VERSION "Vinfast Initial LGC"

NS_ :

BS_:

BU_: CHARGER_S VCU CHARGER_C HMI MCU REFLASH BMS1 BMS0 CLU
VAL_TABLE_ TestCmd 3 "Set UDT Fault" 2 "Set UDT warning2" 0 "Clear" 1 "Set UDT warning1" ;

BO_ 2432176283 E44_MCU: 8 Vector__XXX
 SG_ MCU_W_Phase_Current : 32|16@1+ (0.1,0) [0|6553.5] "A" Vector__XXX
 SG_ MCU_V_Phase_Current : 16|16@1+ (0.1,0) [0|6553.5] "A" Vector__XXX
 SG_ MCU_U_Phase_Current : 0|16@1+ (0.1,0) [0|6553.5] "A" Vector__XXX

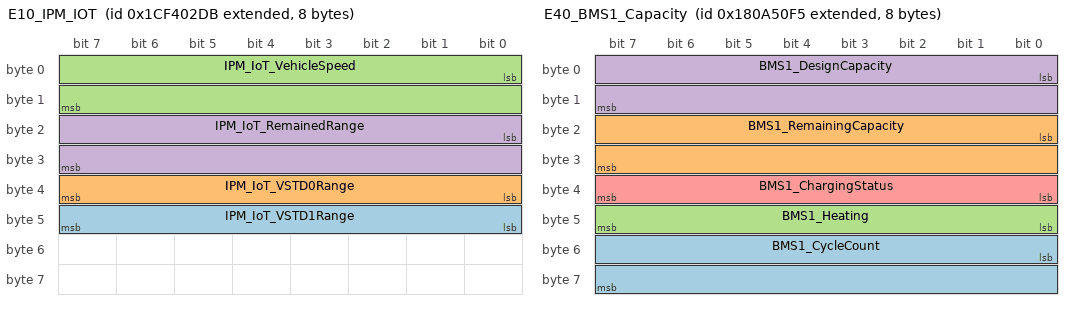
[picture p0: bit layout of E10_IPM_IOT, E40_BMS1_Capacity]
BO_ 2633237211 E10_IPM_IOT: 8 Vector__XXX
 SG_ IPM_IoT_VSTD1Range : 40|8@1+ (1,0) [0|255] "km" Vector__XXX
 SG_ IPM_IoT_VSTD0Range : 32|8@1+ (1,0) [0|255] "km" Vector__XXX
 SG_ IPM_IoT_VehicleSpeed : 0|16@1+ (0.1,0) [0|1000] "km/h" Vector__XXX
 SG_ IPM_IoT_RemainedRange : 16|16@1+ (0.1,0) [0|5000] "km" Vector__XXX

BO_ 2550878453 E39_BMS1_FailureCode: 8 Vector__XXX
 SG_ BMS1_VoltageAcquisitionFailure : 23|1@1+ (1,0) [0|1] "" Vector__XXX
 SG_ BMS1_TotalUndervoltage : 12|1@1+ (1,0) [0|1] "" Vector__XXX
 SG_ BMS1_TotalOvervoltage : 9|1@1+ (1,0) [0|1] "" Vector__XXX
 SG_ BMS1_TempAcquisitionFailure : 24|1@1+ (1,0) [0|1] "" Vector__XXX
 SG_ BMS1_MosTemperature : 6|1@1+ (1,0) [0|1] "" Vector__XXX
 SG_ BMS1_MosHighTemperature : 19|1@1+ (1,0) [0|1] "" Vector__XXX
 SG_ BMS1_LoadAccess : 4|1@1+ (1,0) [0|1] "" Vector__XXX
 SG_ BMS1_FullCharging : 10|1@1+ (1,0) [0|1] "" Vector__XXX
 SG_ BMS1_EnvironLowTemperature : 18|1@1+ (1,0) [0|1] "" Vector__XXX
 SG_ BMS1_EnvironHighTemperature : 17|1@1+ (1,0) [0|1] "" Vector__XXX
 SG_ BMS1_Discharging : 0|1@1+ (1,0) [0|1] "" Vector__XXX
 SG_ BMS1_DischargeShortCircuit : 21|1@1+ (1,0) [0|1] "" Vector__XXX
 SG_ BMS1_DischargeOvercurrent : 20|1@1+ (1,0) [0|1] "" Vector__XXX
 SG_ BMS1_DischargeMosOn : 2|1@1+ (1,0) [0|1] "" Vector__XXX
 SG_ BMS1_DischargeMosFailure : 25|1@1+ (1,0) [0|1] "" Vector__XXX
 SG_ BMS1_DischargeLowTemperature : 14|1@1+ (1,0) [0|1] "" Vector__XXX
 SG_ BMS1_DischargeHighTemperature : 13|1@1+ (1,0) [0|1] "" Vector__XXX
 SG_ BMS1_ChargingOvercurrent : 22|1@1+ (1,0) [0|1] "" Vector__XXX
 SG_ BMS1_ChargingMosFailure : 26|1@1+ (1,0) [0|1] "" Vector__XXX
 SG_ BMS1_ChargingLowTemperature : 16|1@1+ (1,0) [0|1] "" Vector__XXX
 SG_ BMS1_ChargingHighTemperature : 15|1@1+ (1,0) [0|1] "" Vector__XXX
 SG_ BMS1_Charging : 1|1@1+ (1,0) [0|1] "" Vector__XXX
 SG_ BMS1_ChargerisConnected : 5|1@1+ (1,0) [0|1] "" Vector__XXX
 SG_ BMS1_ChargeMosOn : 3|1@1+ (1,0) [0|1] "" Vector__XXX
 SG_ BMS1_CellVoltageDifference : 27|1@1+ (1,0) [0|1] "" Vector__XXX
 SG_ BMS1_CellUndervoltage : 11|1@1+ (1,0) [0|1] "" Vector__XXX
 SG_ BMS1_CellOvervoltage : 8|1@1+ (1,0) [0|1] "" Vector__XXX
 SG_ BMS1_AmbientTemperature : 7|1@1+ (1,0) [0|1] "" Vector__XXX

BO_ 2550878452 E19_BMS0_FailureCode: 8 Vector__XXX
 SG_ BMS0_VoltageAcquisitionFailure : 23|1@1+ (1,0) [0|1] "" Vector__XXX
 SG_ BMS0_TotalUndervoltage : 12|1@1+ (1,0) [0|1] "" Vector__XXX
 SG_ BMS0_TotalOvervoltage : 9|1@1+ (1,0) [0|1] "" Vector__XXX
 SG_ BMS0_TempAcquisitionFailure : 24|1@1+ (1,0) [0|1] "" Vector__XXX
 SG_ BMS0_MosTemperature : 6|1@1+ (1,0) [0|1] "" Vector__XXX
 SG_ BMS0_MosHighTemperature : 19|1@1+ (1,0) [0|1] "" Vector__XXX
 SG_ BMS0_LoadAccess : 4|1@1+ (1,0) [0|1] "" Vector__XXX
 SG_ BMS0_FullCharging : 10|1@1+ (1,0) [0|1] "" Vector__XXX
 SG_ BMS0_EnvironLowTemperature : 18|1@1+ (1,0) [0|1] "" Vector__XXX
 SG_ BMS0_EnvironHighTemperature : 17|1@1+ (1,0) [0|1] "" Vector__XXX
 SG_ BMS0_Discharging : 0|1@1+ (1,0) [0|1] "" Vector__XXX
 SG_ BMS0_DischargeShortCircuit : 21|1@1+ (1,0) [0|1] "" Vector__XXX
 SG_ BMS0_DischargeOvercurrent : 20|1@1+ (1,0) [0|1] "" Vector__XXX
 SG_ BMS0_DischargeMosOn : 2|1@1+ (1,0) [0|1] "" Vector__XXX
 SG_ BMS0_DischargeMosFailure : 25|1@1+ (1,0) [0|1] "" Vector__XXX
 SG_ BMS0_DischargeLowTemperature : 14|1@1+ (1,0) [0|1] "" Vector__XXX
 SG_ BMS0_DischargeHighTemperature : 13|1@1+ (1,0) [0|1] "" Vector__XXX
 SG_ BMS0_ChargingOvercurrent : 22|1@1+ (1,0) [0|1] "" Vector__XXX
 SG_ BMS0_ChargingMosFailure : 26|1@1+ (1,0) [0|1] "" Vector__XXX
 SG_ BMS0_ChargingLowTemperature : 16|1@1+ (1,0) [0|1] "" Vector__XXX
 SG_ BMS0_ChargingHighTemperature : 15|1@1+ (1,0) [0|1] "" Vector__XXX
 SG_ BMS0_Charging : 1|1@1+ (1,0) [0|1] "" Vector__XXX
 SG_ BMS0_ChargerisConnected : 5|1@1+ (1,0) [0|1] "" Vector__XXX
 SG_ BMS0_ChargeMosOn : 3|1@1+ (1,0) [0|1] "" Vector__XXX
 SG_ BMS0_CellVoltageDifference : 27|1@1+ (1,0) [0|1] "" Vector__XXX
 SG_ BMS0_CellUndervoltage : 11|1@1+ (1,0) [0|1] "" Vector__XXX
 SG_ BMS0_CellOvervoltage : 8|1@1+ (1,0) [0|1] "" Vector__XXX
 SG_ BMS0_AmbientTemperature : 7|1@1+ (1,0) [0|1] "" Vector__XXX

BO_ 1426 E53_SBC_Status2: 8 Vector__XXX
 SG_ SBC_OutputCurrent : 32|16@1+ (0.1,0) [0|6553.5] "A" Vector__XXX
 SG_ SBC_OutputVoltage : 16|16@1+ (0.1,0) [0|6553.5] "V" Vector__XXX
 SG_ SBC_InputVoltage : 0|16@1+ (0.1,0) [0|6553.5] "V" Vector__XXX

BO_ 2550588917 E42_BMS1_ChargerVoltageCurrent: 8 Vector__XXX
 SG_ BMS1_OutputControl : 32|8@1+ (1,0) [0|1] "" Vector__XXX
 SG_ BMS1_MaxVoltage : 0|16@1+ (0.1,0) [0|6553.5] "V" Vector__XXX
 SG_ BMS1_MaxCurrent : 16|16@1+ (1,0) [0|65535] "A" Vector__XXX

BO_ 2550747381 E41_BMS1_DebugInfo: 8 Vector__XXX
 SG_ BMS1_VersionNumber : 0|16@1+ (1,0) [0|65535] "" Vector__XXX

BO_ 2550812917 E40_BMS1_Capacity: 8 Vector__XXX
 SG_ BMS1_CycleCount : 48|16@1+ (1,0) [0|65535] "" Vector__XXX
 SG_ BMS1_RemainingCapacity : 16|16@1+ (1,0) [0|65535] "mAh" Vector__XXX
 SG_ BMS1_Heating : 40|8@1+ (1,0) [0|1] "" Vector__XXX
 SG_ BMS1_DesignCapacity : 0|16@1+ (1,0) [0|65535] "mAh" Vector__XXX
 SG_ BMS1_ChargingStatus : 32|8@1+ (1,0) [0|1] "" Vector__XXX

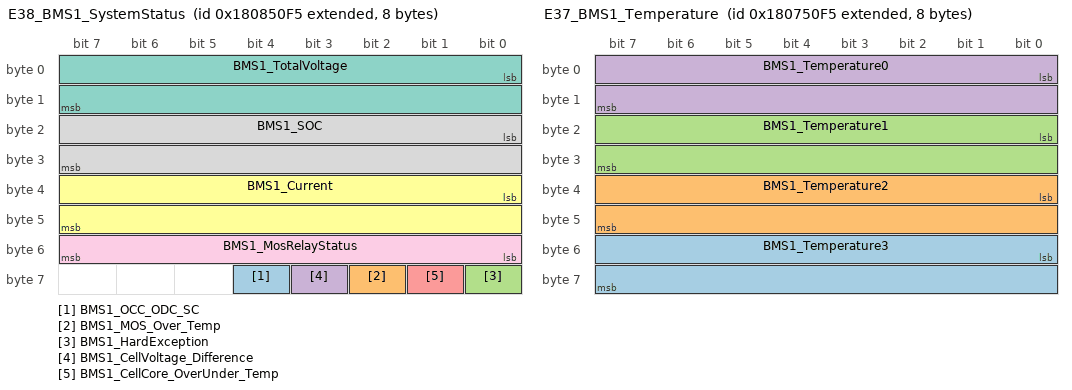
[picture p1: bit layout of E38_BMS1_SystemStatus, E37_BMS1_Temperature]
BO_ 2550681845 E38_BMS1_SystemStatus: 8 Vector__XXX
 SG_ BMS1_OCC_ODC_SC : 60|1@1+ (1,0) [0|1] "" Vector__XXX
 SG_ BMS1_MOS_Over_Temp : 58|1@1+ (1,0) [0|1] "" Vector__XXX
 SG_ BMS1_HardException : 56|1@1+ (1,0) [0|1] "" Vector__XXX
 SG_ BMS1_CellVoltage_Difference : 59|1@1+ (1,0) [0|1] "" Vector__XXX
 SG_ BMS1_CellCore_OverUnder_Temp : 57|1@1+ (1,0) [0|1] "" Vector__XXX
 SG_ BMS1_Current : 32|16@1+ (1,0) [0|65535] "A" Vector__XXX
 SG_ BMS1_TotalVoltage : 0|16@1+ (0.1,0) [0|6553.5] "V" Vector__XXX
 SG_ BMS1_SOC : 16|16@1+ (0.1,0) [0|6553.5] "%" Vector__XXX
 SG_ BMS1_MosRelayStatus : 48|8@1+ (1,0) [0|3] "" Vector__XXX

BO_ 2550616309 E37_BMS1_Temperature: 8 Vector__XXX
 SG_ BMS1_Temperature3 : 48|16@1+ (0.1,-40) [-40|6513.5] "℃" Vector__XXX
 SG_ BMS1_Temperature2 : 32|16@1+ (0.1,-40) [-40|6513.5] "℃" Vector__XXX
 SG_ BMS1_Temperature1 : 16|16@1+ (0.1,-40) [-40|6513.5] "℃" Vector__XXX
 SG_ BMS1_Temperature0 : 0|16@1+ (0.1,-40) [-40|6513.5] "℃" Vector__XXX

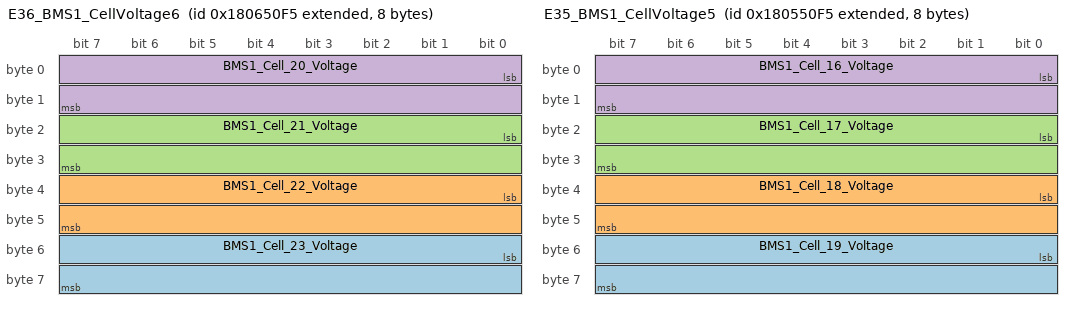
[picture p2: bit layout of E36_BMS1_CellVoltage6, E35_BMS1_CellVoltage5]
BO_ 2550550773 E36_BMS1_CellVoltage6: 8 Vector__XXX
 SG_ BMS1_Cell_23_Voltage : 48|16@1+ (1,0) [0|65535] "mV" Vector__XXX
 SG_ BMS1_Cell_22_Voltage : 32|16@1+ (1,0) [0|65535] "mV" Vector__XXX
 SG_ BMS1_Cell_21_Voltage : 16|16@1+ (1,0) [0|65535] "mV" Vector__XXX
 SG_ BMS1_Cell_20_Voltage : 0|16@1+ (1,0) [0|65535] "mV" Vector__XXX

BO_ 2550485237 E35_BMS1_CellVoltage5: 8 Vector__XXX
 SG_ BMS1_Cell_19_Voltage : 48|16@1+ (1,0) [0|65535] "mV" Vector__XXX
 SG_ BMS1_Cell_18_Voltage : 32|16@1+ (1,0) [0|65535] "mV" Vector__XXX
 SG_ BMS1_Cell_17_Voltage : 16|16@1+ (1,0) [0|65535] "mV" Vector__XXX
 SG_ BMS1_Cell_16_Voltage : 0|16@1+ (1,0) [0|65535] "mV" Vector__XXX

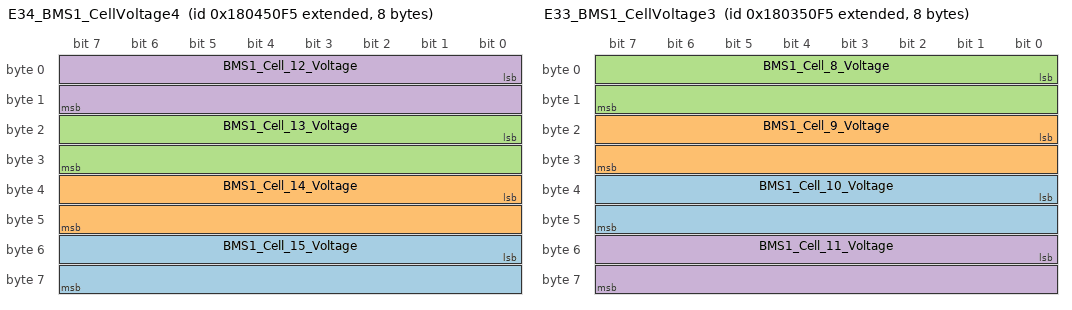
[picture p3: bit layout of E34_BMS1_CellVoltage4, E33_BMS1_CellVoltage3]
BO_ 2550419701 E34_BMS1_CellVoltage4: 8 Vector__XXX
 SG_ BMS1_Cell_15_Voltage : 48|16@1+ (1,0) [0|65535] "mV" Vector__XXX
 SG_ BMS1_Cell_14_Voltage : 32|16@1+ (1,0) [0|65535] "mV" Vector__XXX
 SG_ BMS1_Cell_13_Voltage : 16|16@1+ (1,0) [0|65535] "mV" Vector__XXX
 SG_ BMS1_Cell_12_Voltage : 0|16@1+ (1,0) [0|65535] "mV" Vector__XXX

BO_ 2550354165 E33_BMS1_CellVoltage3: 8 Vector__XXX
 SG_ BMS1_Cell_10_Voltage : 32|16@1+ (1,0) [0|65535] "mV" Vector__XXX
 SG_ BMS1_Cell_9_Voltage : 16|16@1+ (1,0) [0|65535] "mV" Vector__XXX
 SG_ BMS1_Cell_8_Voltage : 0|16@1+ (1,0) [0|65535] "mV" Vector__XXX
 SG_ BMS1_Cell_11_Voltage : 48|16@1+ (1,0) [0|65535] "mV" Vector__XXX

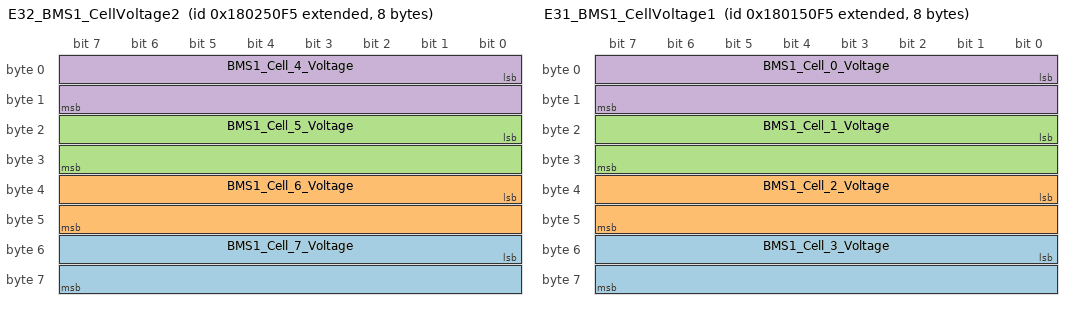
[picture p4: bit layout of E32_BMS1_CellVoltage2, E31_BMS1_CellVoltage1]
BO_ 2550288629 E32_BMS1_CellVoltage2: 8 Vector__XXX
 SG_ BMS1_Cell_7_Voltage : 48|16@1+ (1,0) [0|65535] "mV" Vector__XXX
 SG_ BMS1_Cell_6_Voltage : 32|16@1+ (1,0) [0|65535] "mV" Vector__XXX
 SG_ BMS1_Cell_5_Voltage : 16|16@1+ (1,0) [0|65535] "mV" Vector__XXX
 SG_ BMS1_Cell_4_Voltage : 0|16@1+ (1,0) [0|65535] "mV" Vector__XXX

BO_ 2550223093 E31_BMS1_CellVoltage1: 8 Vector__XXX
 SG_ BMS1_Cell_3_Voltage : 48|16@1+ (1,0) [0|65535] "mV" Vector__XXX
 SG_ BMS1_Cell_2_Voltage : 32|16@1+ (1,0) [0|65535] "mV" Vector__XXX
 SG_ BMS1_Cell_1_Voltage : 16|16@1+ (1,0) [0|65535] "mV" Vector__XXX
 SG_ BMS1_Cell_0_Voltage : 0|16@1+ (1,0) [0|65535] "mV" Vector__XXX

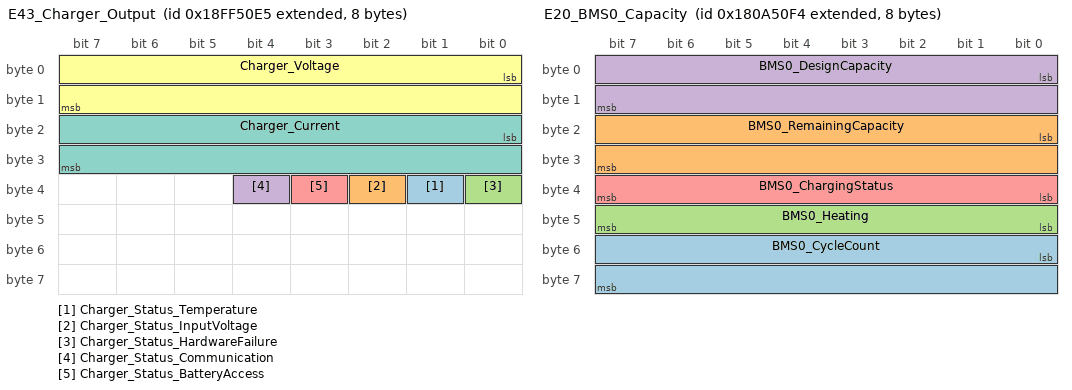
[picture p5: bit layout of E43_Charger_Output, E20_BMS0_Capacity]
BO_ 2566869221 E43_Charger_Output: 8 Vector__XXX
 SG_ Charger_Status_Temperature : 33|1@1+ (1,0) [0|1] "" Vector__XXX
 SG_ Charger_Status_InputVoltage : 34|1@1+ (1,0) [0|1] "" Vector__XXX
 SG_ Charger_Status_HardwareFailure : 32|1@1+ (1,0) [0|1] "" Vector__XXX
 SG_ Charger_Status_Communication : 36|1@1+ (1,0) [0|1] "" Vector__XXX
 SG_ Charger_Status_BatteryAccess : 35|1@1+ (1,0) [0|1] "" Vector__XXX
 SG_ Charger_Voltage : 0|16@1+ (0.1,0) [0|6553.5] "V" Vector__XXX
 SG_ Charger_Current : 16|16@1+ (0.1,0) [0|6553.5] "A" Vector__XXX

BO_ 2550588916 E22_BMS0_ChargerVoltageCurrent: 8 Vector__XXX
 SG_ BMS0_OutputControl : 32|8@1+ (1,0) [0|1] "" Vector__XXX
 SG_ BMS0_MaxVoltage : 0|16@1+ (0.1,0) [0|6553.5] "V" Vector__XXX
 SG_ BMS0_MaxCurrent : 16|16@1+ (1,0) [0|65535] "A" Vector__XXX

BO_ 2550747380 E21_BMS0_DebugInfo: 8 Vector__XXX
 SG_ BMS0_VersionNumber : 0|16@1+ (1,0) [0|65535] "" Vector__XXX

BO_ 2550812916 E20_BMS0_Capacity: 8 Vector__XXX
 SG_ BMS0_CycleCount : 48|16@1+ (1,0) [0|65535] "" Vector__XXX
 SG_ BMS0_RemainingCapacity : 16|16@1+ (1,0) [0|65535] "mAh" Vector__XXX
 SG_ BMS0_Heating : 40|8@1+ (1,0) [0|1] "" Vector__XXX
 SG_ BMS0_DesignCapacity : 0|16@1+ (1,0) [0|65535] "mAh" Vector__XXX
 SG_ BMS0_ChargingStatus : 32|8@1+ (1,0) [0|1] "" Vector__XXX

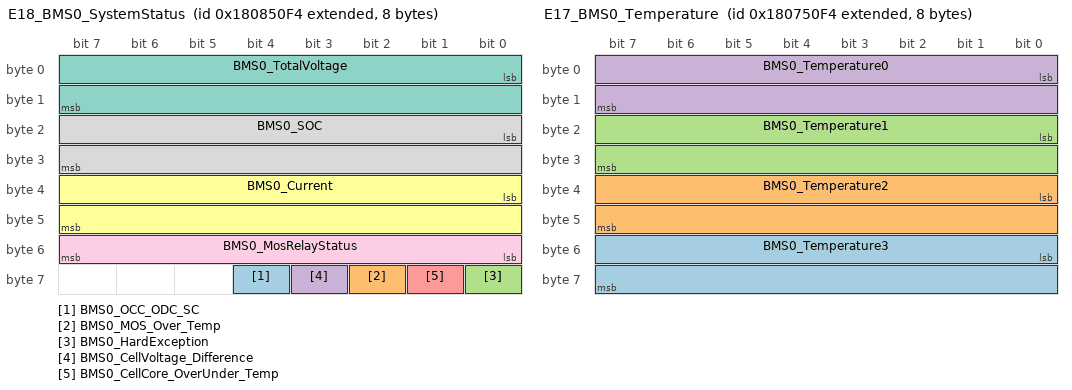
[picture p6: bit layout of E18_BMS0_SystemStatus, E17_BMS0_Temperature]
BO_ 2550681844 E18_BMS0_SystemStatus: 8 Vector__XXX
 SG_ BMS0_OCC_ODC_SC : 60|1@1+ (1,0) [0|1] "" Vector__XXX
 SG_ BMS0_MOS_Over_Temp : 58|1@1+ (1,0) [0|1] "" Vector__XXX
 SG_ BMS0_HardException : 56|1@1+ (1,0) [0|1] "" Vector__XXX
 SG_ BMS0_CellVoltage_Difference : 59|1@1+ (1,0) [0|1] "" Vector__XXX
 SG_ BMS0_CellCore_OverUnder_Temp : 57|1@1+ (1,0) [0|1] "" Vector__XXX
 SG_ BMS0_Current : 32|16@1+ (1,0) [0|65535] "A" Vector__XXX
 SG_ BMS0_TotalVoltage : 0|16@1+ (0.1,0) [0|6553.5] "V" Vector__XXX
 SG_ BMS0_SOC : 16|16@1+ (0.1,0) [0|6553.5] "%" Vector__XXX
 SG_ BMS0_MosRelayStatus : 48|8@1+ (1,0) [0|3] "" Vector__XXX

BO_ 2550616308 E17_BMS0_Temperature: 8 Vector__XXX
 SG_ BMS0_Temperature3 : 48|16@1+ (0.1,-40) [-40|6513.5] "℃" Vector__XXX
 SG_ BMS0_Temperature2 : 32|16@1+ (0.1,-40) [-40|6513.5] "℃" Vector__XXX
 SG_ BMS0_Temperature1 : 16|16@1+ (0.1,-40) [-40|6513.5] "℃" Vector__XXX
 SG_ BMS0_Temperature0 : 0|16@1+ (0.1,-40) [-40|6513.5] "℃" Vector__XXX

BO_ 2550550772 E16_BMS0_CellVoltage6: 8 Vector__XXX
 SG_ BMS0_Cell_23_Voltage : 48|16@1+ (1,0) [0|65535] "mV" Vector__XXX
 SG_ BMS0_Cell_22_Voltage : 32|16@1+ (1,0) [0|65535] "mV" Vector__XXX
 SG_ BMS0_Cell_21_Voltage : 16|16@1+ (1,0) [0|65535] "mV" Vector__XXX
 SG_ BMS0_Cell_20_Voltage : 0|16@1+ (1,0) [0|65535] "mV" Vector__XXX

BO_ 2550485236 E15_BMS0_CellVoltage5: 8 Vector__XXX
 SG_ BMS0_Cell_19_Voltage : 48|16@1+ (1,0) [0|65535] "mV" Vector__XXX
 SG_ BMS0_Cell_18_Voltage : 32|16@1+ (1,0) [0|65535] "mV" Vector__XXX
 SG_ BMS0_Cell_17_Voltage : 16|16@1+ (1,0) [0|65535] "mV" Vector__XXX
 SG_ BMS0_Cell_16_Voltage : 0|16@1+ (1,0) [0|65535] "mV" Vector__XXX

BO_ 2550419700 E14_BMS0_CellVoltage4: 8 Vector__XXX
 SG_ BMS0_Cell_15_Voltage : 48|16@1+ (1,0) [0|65535] "mV" Vector__XXX
 SG_ BMS0_Cell_14_Voltage : 32|16@1+ (1,0) [0|65535] "mV" Vector__XXX
 SG_ BMS0_Cell_13_Voltage : 16|16@1+ (1,0) [0|65535] "mV" Vector__XXX
 SG_ BMS0_Cell_12_Voltage : 0|16@1+ (1,0) [0|65535] "mV" Vector__XXX

BO_ 2550354164 E13_BMS0_CellVoltage3: 8 Vector__XXX
 SG_ BMS0_Cell_10_Voltage : 32|16@1+ (1,0) [0|65535] "mV" Vector__XXX
 SG_ BMS0_Cell_9_Voltage : 16|16@1+ (1,0) [0|65535] "mV" Vector__XXX
 SG_ BMS0_Cell_8_Voltage : 0|16@1+ (1,0) [0|65535] "mV" Vector__XXX
 SG_ BMS0_Cell_11_Voltage : 48|16@1+ (1,0) [0|65535] "mV" Vector__XXX

BO_ 2550288628 E12_BMS0_CellVoltage2: 8 Vector__XXX
 SG_ BMS0_Cell_7_Voltage : 48|16@1+ (1,0) [0|65535] "mV" Vector__XXX
 SG_ BMS0_Cell_6_Voltage : 32|16@1+ (1,0) [0|65535] "mV" Vector__XXX
 SG_ BMS0_Cell_5_Voltage : 16|16@1+ (1,0) [0|65535] "mV" Vector__XXX
 SG_ BMS0_Cell_4_Voltage : 0|16@1+ (1,0) [0|65535] "mV" Vector__XXX

BO_ 2550223092 E11_BMS0_CellVoltage1: 8 Vector__XXX
 SG_ BMS0_Cell_3_Voltage : 48|16@1+ (1,0) [0|65535] "mV" Vector__XXX
 SG_ BMS0_Cell_2_Voltage : 32|16@1+ (1,0) [0|65535] "mV" Vector__XXX
 SG_ BMS0_Cell_1_Voltage : 16|16@1+ (1,0) [0|65535] "mV" Vector__XXX
 SG_ BMS0_Cell_0_Voltage : 0|16@1+ (1,0) [0|65535] "mV" Vector__XXX

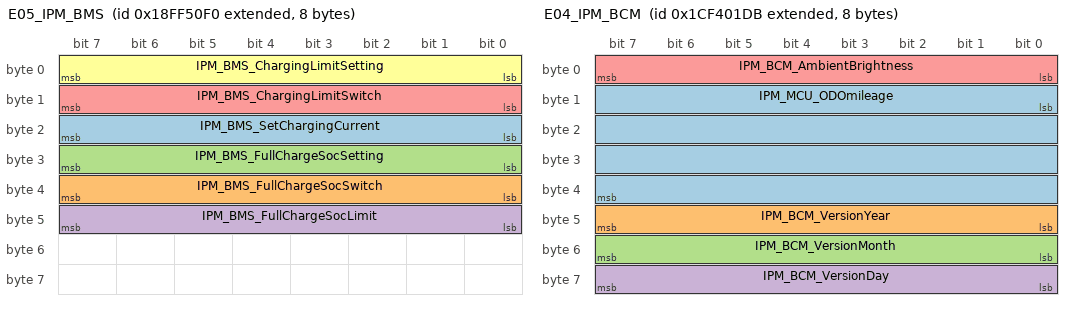
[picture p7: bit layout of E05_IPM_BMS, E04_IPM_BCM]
BO_ 2566869232 E05_IPM_BMS: 8 Vector__XXX
 SG_ IPM_BMS_SetChargingCurrent : 16|8@1+ (1,0) [0|100] "" Vector__XXX
 SG_ IPM_BMS_FullChargeSocSwitch : 32|8@1+ (1,0) [0|1] "" Vector__XXX
 SG_ IPM_BMS_FullChargeSocSetting : 24|8@1+ (1,0) [0|1] "" Vector__XXX
 SG_ IPM_BMS_FullChargeSocLimit : 40|8@1+ (1,0) [10|100] "" Vector__XXX
 SG_ IPM_BMS_ChargingLimitSwitch : 8|8@1+ (1,0) [0|1] "" Vector__XXX
 SG_ IPM_BMS_ChargingLimitSetting : 0|8@1+ (1,0) [0|1] "" Vector__XXX

BO_ 2633236955 E04_IPM_BCM: 8 Vector__XXX
 SG_ IPM_MCU_ODOmileage : 8|32@1+ (1,0) [0|999999] "km" Vector__XXX
 SG_ IPM_BCM_VersionYear : 40|8@1+ (1,0) [0|99] "" Vector__XXX
 SG_ IPM_BCM_VersionMonth : 48|8@1+ (1,0) [0|12] "" Vector__XXX
 SG_ IPM_BCM_VersionDay : 56|8@1+ (1,0) [0|31] "" Vector__XXX
 SG_ IPM_BCM_AmbientBrightness : 0|8@1+ (1,0) [0|10] "" Vector__XXX

BO_ 2550685947 E03_BCM_IPM: 8 Vector__XXX
 SG_ BCM_IPM_NFCcardCountdown : 40|8@1+ (1,0) [0|255] "" Vector__XXX
 SG_ BCM_IPM_BCMVersion : 48|16@1+ (1,0) [0|65535] "" Vector__XXX
 SG_ BCM_IPM_ChargerAccess : 6|1@1+ (1,0) [0|1] "" Vector__XXX
 SG_ BCM_IPM_ACC_Status : 11|1@1+ (1,0) [0|1] "" Vector__XXX
 SG_ BCM_IPM_WidnshieldMotor : 20|2@1+ (1,0) [0|3] "" Vector__XXX
 SG_ BCM_IPM_TapLock : 3|1@1+ (1,0) [0|1] "" Vector__XXX
 SG_ BCM_IPM_SideSupporter : 2|1@1+ (1,0) [0|1] "" Vector__XXX
 SG_ BCM_IPM_ShelfMotor : 22|2@1+ (1,0) [0|3] "" Vector__XXX
 SG_ BCM_IPM_PedalLock : 4|1@1+ (1,0) [0|1] "" Vector__XXX
 SG_ BCM_IPM_NfcCardStatus : 24|2@1+ (1,0) [0|3] "" Vector__XXX
 SG_ BCM_IPM_NfcCardModeCountdown : 32|8@1+ (1,0) [0|255] "" Vector__XXX
 SG_ BCM_IPM_NfcCardFeedback : 28|2@1+ (1,0) [0|3] "" Vector__XXX
 SG_ BCM_IPM_NfcCardDistribution : 26|2@1+ (1,0) [0|3] "" Vector__XXX
 SG_ BCM_IPM_Motion : 1|1@1+ (1,0) [0|1] "" Vector__XXX
 SG_ BCM_IPM_MechanicalKeyAcc : 9|1@1+ (1,0) [0|1] "" Vector__XXX
 SG_ BCM_IPM_InternalAcc : 8|1@1+ (1,0) [0|1] "" Vector__XXX
 SG_ BCM_IPM_Inclination : 0|1@1+ (1,0) [0|1] "" Vector__XXX
 SG_ BCM_IPM_HeatingSeat : 18|2@1+ (1,0) [0|3] "" Vector__XXX
 SG_ BCM_IPM_CombinationAuto : 10|1@1+ (1,0) [0|1] "" Vector__XXX
 SG_ BCM_IPM_BucketLock : 5|1@1+ (1,0) [0|1] "" Vector__XXX
 SG_ BCM_IPM_HeatingHandle : 16|2@1+ (1,0) [0|3] "" Vector__XXX

BO_ 2550681850 E01_BCM_MCU: 8 Vector__XXX
 SG_ BCM_IPM_ScreenSwitching : 32|8@1+ (1,0) [0|1] "" Vector__XXX
 SG_ BCM_IPM_VSTDConnection : 44|1@1+ (1,0) [0|1] "" Vector__XXX
 SG_ BCM_IPM_RightSwitchConnection : 42|1@1+ (1,0) [0|1] "" Vector__XXX
 SG_ BCM_IPM_RearLamlConnection : 41|1@1+ (1,0) [0|1] "" Vector__XXX
 SG_ BCM_IPM_LeftSwitchConnection : 43|1@1+ (1,0) [0|1] "" Vector__XXX
 SG_ BCM_IPM_HeadLamlConnection : 40|1@1+ (1,0) [0|1] "" Vector__XXX
 SG_ BCM_IPM_LowBrake : 23|1@1+ (1,0) [0|1] "" Vector__XXX
 SG_ BCM_IPM_ReverseGear_ReturnCancel : 22|1@1+ (1,0) [0|1] "" Vector__XXX
 SG_ BCM_MCU_MotorSelfLearning : 48|8@1+ (1,0) [0|1] "" Vector__XXX
 SG_ BCM_MCU_EmergencyExtinguishing : 20|1@1+ (1,0) [0|1] "" Vector__XXX
 SG_ BCM_MCU_Downshift : 19|1@1+ (1,0) [0|1] "" Vector__XXX
 SG_ BCM_MCU_Cruise : 21|1@1+ (1,0) [0|1] "" Vector__XXX
 SG_ BCM_MCU_ThrottleVoltage : 0|16@1+ (0.01,0) [0|500] "V" Vector__XXX
 SG_ BCM_MCU_CutOff_AutoButton : 17|1@1+ (1,0) [0|1] "" Vector__XXX
 SG_ BCM_MCU_SingleSupport : 18|1@1+ (1,0) [0|1] "" Vector__XXX
 SG_ BCM_MCU_DCDC_Voltage : 56|8@1+ (0.1,0) [0|25.5] "V" Vector__XXX
 SG_ BCM_MCU_Brake : 16|1@1+ (1,0) [0|1] "" Vector__XXX

BO_ 2550681849 E02_BCM_IPM: 8 Vector__XXX
 SG_ BCM_IPM_LightStatus_Passing : 5|1@1+ (1,0) [0|1] "" Vector__XXX
 SG_ BCM_IPM_DelayedPowerDown : 7|1@1+ (1,0) [0|1] "" Vector__XXX
 SG_ BCM_IPM_AutoHeadLamp : 6|1@1+ (1,0) [0|1] "" Vector__XXX
 SG_ BCM_IPM_WelcomeHome : 8|8@1+ (1,0) [0|255] "" Vector__XXX
 SG_ BCM_IPM_LightStatus_Turn_R : 1|1@1+ (1,0) [0|1] "" Vector__XXX
 SG_ BCM_IPM_LightStatus_Turn_L : 0|1@1+ (1,0) [0|1] "" Vector__XXX
 SG_ BCM_IPM_LightStatus_HighBeam : 3|1@1+ (1,0) [0|1] "" Vector__XXX
 SG_ BCM_IPM_LightStatus_HeadNear : 2|1@1+ (1,0) [0|1] "" Vector__XXX
 SG_ BCM_IPM_LightStatus_Brake : 4|1@1+ (1,0) [0|1] "" Vector__XXX
 SG_ BCM_IPM_LightFailure_Turn_R : 17|1@1+ (1,0) [0|1] "" Vector__XXX
 SG_ BCM_IPM_LightFailure_Turn_L : 16|1@1+ (1,0) [0|1] "" Vector__XXX
 SG_ BCM_IPM_LightFailure_HighBeam : 19|1@1+ (1,0) [0|1] "" Vector__XXX
 SG_ BCM_IPM_LightFailure_HeadNear : 18|1@1+ (1,0) [0|1] "" Vector__XXX
 SG_ BCM_IPM_LightFailure_Brake : 20|1@1+ (1,0) [0|1] "" Vector__XXX
 SG_ BCM_IPM_LightCurrent_Turn_R : 32|8@1+ (0.1,0) [0|25.5] "A" Vector__XXX
 SG_ BCM_IPM_LightCurrent_Turn_L : 24|8@1+ (0.1,0) [0|25.5] "A" Vector__XXX
 SG_ BCM_IPM_LightCurrent_HighBeam : 48|8@1+ (0.1,0) [0|25.5] "A" Vector__XXX
 SG_ BCM_IPM_LightCurrent_HeadNear : 40|8@1+ (0.1,0) [0|25.5] "A" Vector__XXX
 SG_ BCM_IPM_LightCurrent_Brake : 56|8@1+ (0.1,0) [0|25.5] "A" Vector__XXX

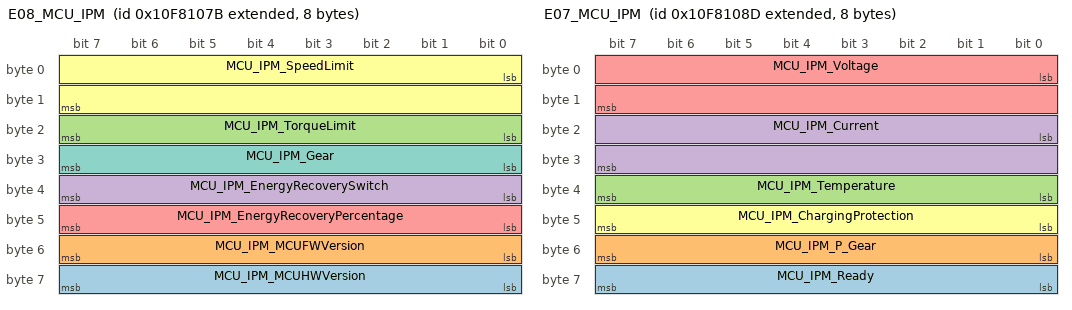
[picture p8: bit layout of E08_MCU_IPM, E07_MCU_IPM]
BO_ 2432176251 E08_MCU_IPM: 8 Vector__XXX
 SG_ MCU_IPM_MCUHWVersion : 56|8@1+ (1,0) [0|255] "" Vector__XXX
 SG_ MCU_IPM_MCUFWVersion : 48|8@1+ (1,0) [0|255] "" Vector__XXX
 SG_ MCU_IPM_TorqueLimit : 16|8@1+ (1,0) [0|100] "%" Vector__XXX
 SG_ MCU_IPM_EnergyRecoverySwitch : 32|8@1+ (1,0) [0|1] "" Vector__XXX
 SG_ MCU_IPM_EnergyRecoveryPercentage : 40|8@1+ (1,0) [0|100] "%" Vector__XXX
 SG_ MCU_IPM_SpeedLimit : 0|16@1+ (1,0) [0|20000] "RPM" Vector__XXX
 SG_ MCU_IPM_Gear : 24|8@1+ (1,0) [0|2] "" Vector__XXX

BO_ 2432176269 E07_MCU_IPM: 8 Vector__XXX
 SG_ MCU_IPM_Ready : 56|8@1+ (1,0) [0|1] "" Vector__XXX
 SG_ MCU_IPM_P_Gear : 48|8@1+ (1,0) [0|1] "" Vector__XXX
 SG_ MCU_IPM_Temperature : 32|8@1- (1,0) [-128|127] "℃" Vector__XXX
 SG_ MCU_IPM_Current : 16|16@1+ (0.1,0) [0|500] "A" Vector__XXX
 SG_ MCU_IPM_Voltage : 0|16@1+ (0.1,0) [0|1000] "V" Vector__XXX
 SG_ MCU_IPM_ChargingProtection : 40|8@1+ (1,0) [0|1] "" Vector__XXX

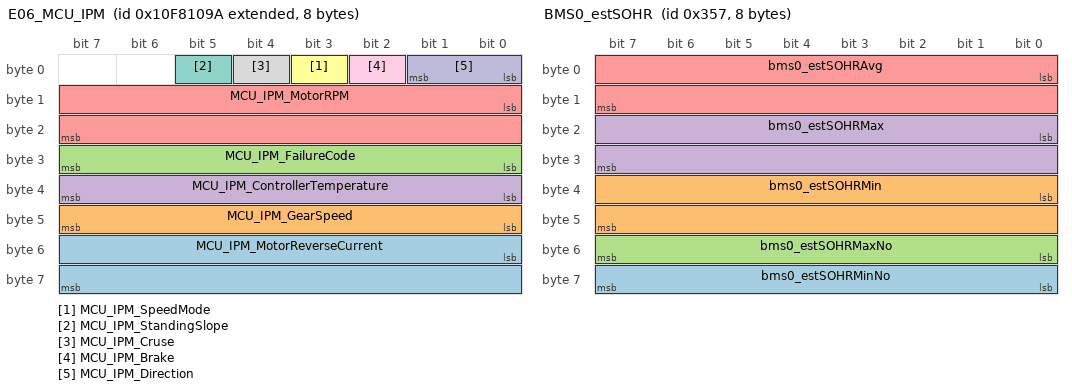
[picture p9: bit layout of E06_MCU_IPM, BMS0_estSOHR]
BO_ 2432176282 E06_MCU_IPM: 8 Vector__XXX
 SG_ MCU_IPM_MotorReverseCurrent : 48|16@1+ (0.1,0) [0|2000] "A" Vector__XXX
 SG_ MCU_IPM_GearSpeed : 40|8@1+ (1,0) [0|2] "" Vector__XXX
 SG_ MCU_IPM_FailureCode : 24|8@1+ (1,0) [0|20] "" Vector__XXX
 SG_ MCU_IPM_ControllerTemperature : 32|8@1- (1,0) [-128|127] "℃" Vector__XXX
 SG_ MCU_IPM_MotorRPM : 8|16@1+ (1,0) [0|20000] "RPM" Vector__XXX
 SG_ MCU_IPM_SpeedMode : 3|1@1+ (1,0) [0|1] "" Vector__XXX
 SG_ MCU_IPM_StandingSlope : 5|1@1+ (1,0) [0|1] "" Vector__XXX
 SG_ MCU_IPM_Cruse : 4|1@1+ (1,0) [0|1] "" Vector__XXX
 SG_ MCU_IPM_Brake : 2|1@1+ (1,0) [0|1] "" Vector__XXX
 SG_ MCU_IPM_Direction : 0|2@1+ (1,0) [0|2] "" Vector__XXX

BO_ 1425 E52_SBC_Status1: 2 Vector__XXX
 SG_ SBC_BMS_AliveCounter : 8|8@1+ (1,0) [0|255] "" Vector__XXX
 SG_ SBC_BMS_OnOffAck : 0|8@1+ (1,0) [0|255] "" Vector__XXX

BO_ 1424 E51_BMS_SBC_Control: 1 Vector__XXX
 SG_ BMS_SBC_SbcOn : 0|1@1+ (1,0) [0|1] "" Vector__XXX

BO_ 773 BMS0_devDebugEnable: 8 BMS0
 SG_ bms0_devDebugSox_Flag : 24|8@1+ (1,0) [0|255] "" Vector__XXX
 SG_ bms0_devDebugTemp_Flag : 16|8@1+ (1,0) [0|255] "" Vector__XXX
 SG_ bms0_devDebugCurrent_Flag : 8|8@1+ (1,0) [0|255] "" Vector__XXX
 SG_ bms0_devDebugCellVolt_Flag : 0|8@1+ (1,0) [0|255] "" Vector__XXX

BO_ 872 BMS1_msrPackStd: 8 BMS1
 SG_ bms1_msrCurrentPackStd : 0|16@1- (0.02,0) [-655.36|655.34] "A" Vector__XXX

BO_ 856 BMS0_msrPackStd: 8 BMS0
 SG_ bms0_msrCurrentPackStd : 0|16@1- (0.02,0) [-655.36|655.34] "A" Vector__XXX

BO_ 855 BMS0_estSOHR: 8 BMS0
 SG_ bms0_estSOHRMinNo : 56|8@1+ (1,0) [0|255] "" Vector__XXX
 SG_ bms0_estSOHRMin : 32|16@1+ (1,0) [0|65535] "%" Vector__XXX
 SG_ bms0_estSOHRMaxNo : 48|8@1+ (1,0) [0|255] "" Vector__XXX
 SG_ bms0_estSOHRMax : 16|16@1+ (1,0) [0|65535] "%" Vector__XXX
 SG_ bms0_estSOHRAvg : 0|16@1+ (1,0) [0|65535] "%" Vector__XXX

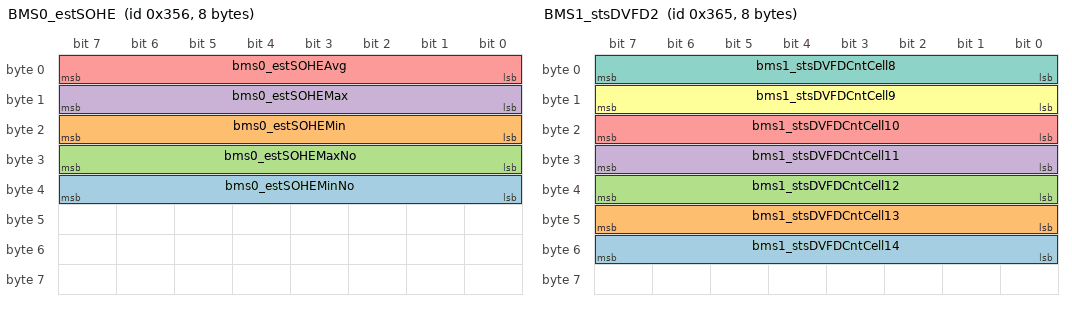
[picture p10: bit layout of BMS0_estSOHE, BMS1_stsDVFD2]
BO_ 854 BMS0_estSOHE: 8 BMS0
 SG_ bms0_estSOHEMinNo : 32|8@1+ (1,0) [0|255] "" Vector__XXX
 SG_ bms0_estSOHEMin : 16|8@1+ (1,0) [0|255] "%" Vector__XXX
 SG_ bms0_estSOHEMaxNo : 24|8@1+ (1,0) [0|15] "" Vector__XXX
 SG_ bms0_estSOHEMax : 8|8@1+ (1,0) [0|255] "%" Vector__XXX
 SG_ bms0_estSOHEAvg : 0|8@1+ (1,0) [0|255] "%" Vector__XXX

BO_ 869 BMS1_stsDVFD2: 8 BMS1
 SG_ bms1_stsDVFDCntCell14 : 48|8@1+ (1,0) [0|255] "" Vector__XXX
 SG_ bms1_stsDVFDCntCell13 : 40|8@1+ (1,0) [0|255] "" Vector__XXX
 SG_ bms1_stsDVFDCntCell12 : 32|8@1+ (1,0) [0|255] "" Vector__XXX
 SG_ bms1_stsDVFDCntCell11 : 24|8@1+ (1,0) [0|255] "" Vector__XXX
 SG_ bms1_stsDVFDCntCell10 : 16|8@1+ (1,0) [0|255] "" Vector__XXX
 SG_ bms1_stsDVFDCntCell9 : 8|8@1+ (1,0) [0|255] "" Vector__XXX
 SG_ bms1_stsDVFDCntCell8 : 0|8@1+ (1,0) [0|255] "" Vector__XXX

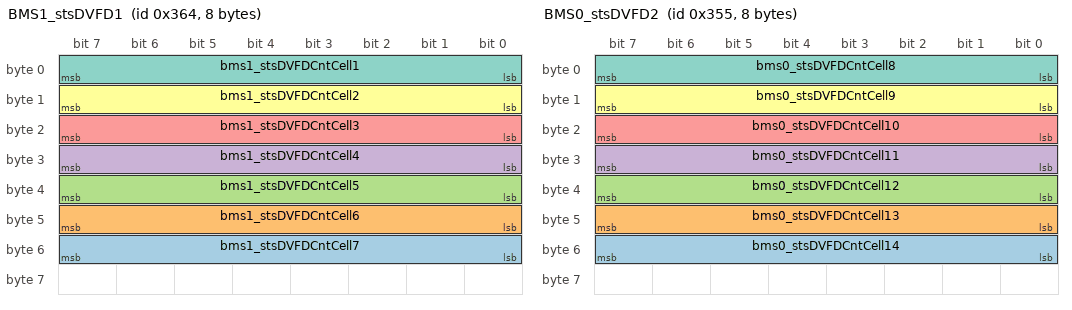
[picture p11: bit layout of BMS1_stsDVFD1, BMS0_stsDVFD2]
BO_ 868 BMS1_stsDVFD1: 8 BMS1
 SG_ bms1_stsDVFDCntCell7 : 48|8@1+ (1,0) [0|255] "" Vector__XXX
 SG_ bms1_stsDVFDCntCell6 : 40|8@1+ (1,0) [0|255] "" Vector__XXX
 SG_ bms1_stsDVFDCntCell5 : 32|8@1+ (1,0) [0|255] "" Vector__XXX
 SG_ bms1_stsDVFDCntCell4 : 24|8@1+ (1,0) [0|255] "" Vector__XXX
 SG_ bms1_stsDVFDCntCell3 : 16|8@1+ (1,0) [0|255] "" Vector__XXX
 SG_ bms1_stsDVFDCntCell2 : 8|8@1+ (1,0) [0|255] "" Vector__XXX
 SG_ bms1_stsDVFDCntCell1 : 0|8@1+ (1,0) [0|255] "" Vector__XXX

BO_ 853 BMS0_stsDVFD2: 8 BMS0
 SG_ bms0_stsDVFDCntCell14 : 48|8@1+ (1,0) [0|255] "" Vector__XXX
 SG_ bms0_stsDVFDCntCell13 : 40|8@1+ (1,0) [0|255] "" Vector__XXX
 SG_ bms0_stsDVFDCntCell12 : 32|8@1+ (1,0) [0|255] "" Vector__XXX
 SG_ bms0_stsDVFDCntCell11 : 24|8@1+ (1,0) [0|255] "" Vector__XXX
 SG_ bms0_stsDVFDCntCell10 : 16|8@1+ (1,0) [0|255] "" Vector__XXX
 SG_ bms0_stsDVFDCntCell9 : 8|8@1+ (1,0) [0|255] "" Vector__XXX
 SG_ bms0_stsDVFDCntCell8 : 0|8@1+ (1,0) [0|255] "" Vector__XXX

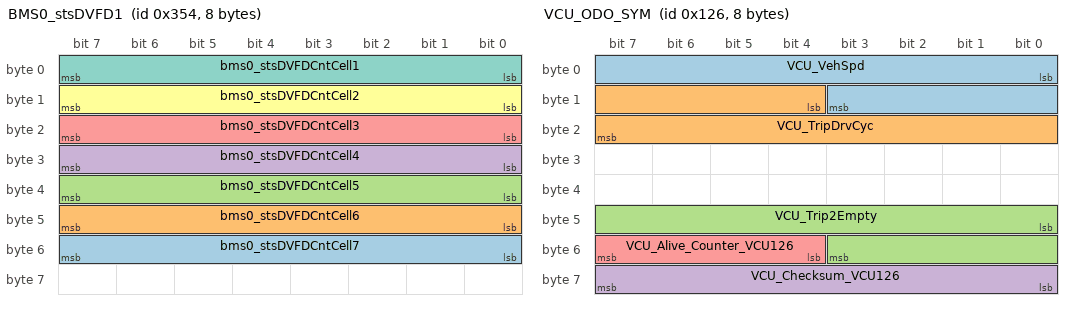
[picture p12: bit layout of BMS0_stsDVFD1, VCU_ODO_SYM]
BO_ 852 BMS0_stsDVFD1: 8 BMS0
 SG_ bms0_stsDVFDCntCell7 : 48|8@1+ (1,0) [0|255] "" Vector__XXX
 SG_ bms0_stsDVFDCntCell6 : 40|8@1+ (1,0) [0|255] "" Vector__XXX
 SG_ bms0_stsDVFDCntCell5 : 32|8@1+ (1,0) [0|255] "" Vector__XXX
 SG_ bms0_stsDVFDCntCell4 : 24|8@1+ (1,0) [0|255] "" Vector__XXX
 SG_ bms0_stsDVFDCntCell3 : 16|8@1+ (1,0) [0|255] "" Vector__XXX
 SG_ bms0_stsDVFDCntCell2 : 8|8@1+ (1,0) [0|255] "" Vector__XXX
 SG_ bms0_stsDVFDCntCell1 : 0|8@1+ (1,0) [0|255] "" Vector__XXX

BO_ 865 BMS1_estAccumEnergy: 8 BMS1
 SG_ bms1_estAccumEnergyDisc : 32|32@1- (0.001,0) [-2147483.648|2147483.647] "kWh" Vector__XXX
 SG_ bms1_estAccumEnergyChg : 0|32@1- (0.001,0) [-2147483.648|2147483.647] "kWh" Vector__XXX

BO_ 864 BMS1_estAccumCapacity: 8 BMS1
 SG_ bms1_estAccumCapacityDisc : 32|32@1- (1E-05,0) [-21474.83648|21474.83647] "kAh" Vector__XXX
 SG_ bms1_estAccumCapacityChg : 0|32@1- (1E-05,0) [-21474.83648|21474.83647] "kAh" Vector__XXX

BO_ 849 BMS0_estAccumEnergy: 8 Vector__XXX
 SG_ bms0_estAccumEnergyDisc : 32|32@1- (0.001,0) [-2147483.648|2147483.647] "kWh" Vector__XXX
 SG_ bms0_estAccumEnergyChg : 0|32@1- (0.001,0) [-2147483.648|2147483.647] "kWh" Vector__XXX

BO_ 848 BMS0_estAccumCapacity: 8 BMS0
 SG_ bms0_estAccumCapacityDisc : 32|32@1- (1E-05,0) [-21474.83648|21474.83647] "kAh" Vector__XXX
 SG_ bms0_estAccumCapacityChg : 0|32@1- (1E-05,0) [-21474.83648|21474.83647] "kAh"  CHARGER_S,CHARGER_C,VCU

BO_ 847 BMS1_msrTempAdvanced: 8 BMS1
 SG_ bms1_msrTempCell3Advanced : 32|16@1- (0.1,0) [-3276.8|3276.7] "℃"  VCU
 SG_ bms1_msrTempCell2Advanced : 16|16@1- (0.1,0) [-3276.8|3276.7] "℃"  VCU
 SG_ bms1_msrTempCell1Advanced : 0|16@1- (0.1,0) [-3276.8|3276.7] "℃"  VCU

BO_ 831 BMS0_msrTempAdvanced: 8 BMS0
 SG_ bms0_msrTempCell3Advanced : 32|16@1- (0.1,0) [-3276.8|3276.7] "℃"  VCU
 SG_ bms0_msrTempCell2Advanced : 16|16@1- (0.1,0) [-3276.8|3276.7] "℃"  VCU
 SG_ bms0_msrTempCell1Advanced : 0|16@1- (0.1,0) [-3276.8|3276.7] "℃"  VCU

BO_ 846 BMS1_estSOCAdvanced: 8 BMS1
 SG_ bms1_estSOHAdvanced : 16|16@1+ (0.1,0) [0|6553.5] "%"  VCU
 SG_ bms1_estRSOCAdvanced : 0|16@1+ (0.1,0) [0|6553.5] "%"  VCU

BO_ 830 BMS0_estSOCAdvanced: 8 BMS0
 SG_ bms0_estSOHAdvanced : 16|16@1+ (0.1,0) [0|6553.5] "%"  VCU
 SG_ bms0_estRSOCAdvanced : 0|16@1+ (0.1,0) [0|6553.5] "%"  VCU

BO_ 294 VCU_ODO_SYM: 8 VCU
 SG_ VCU_VehSpd : 0|12@1+ (0.1,0) [0|409.5] "km/h"  BMS1,BMS0
 SG_ VCU_TripDrvCyc : 12|12@1+ (0.1,0) [0|409.5] "km"  BMS1,BMS0
 SG_ VCU_Trip2Empty : 40|12@1+ (0.1,0) [0|409.5] ""  BMS1,BMS0
 SG_ VCU_Checksum_VCU126 : 56|8@1+ (1,0) [0|255] ""  BMS1,BMS0
 SG_ VCU_Alive_Counter_VCU126 : 52|4@1+ (1,0) [0|15] ""  BMS1,BMS0

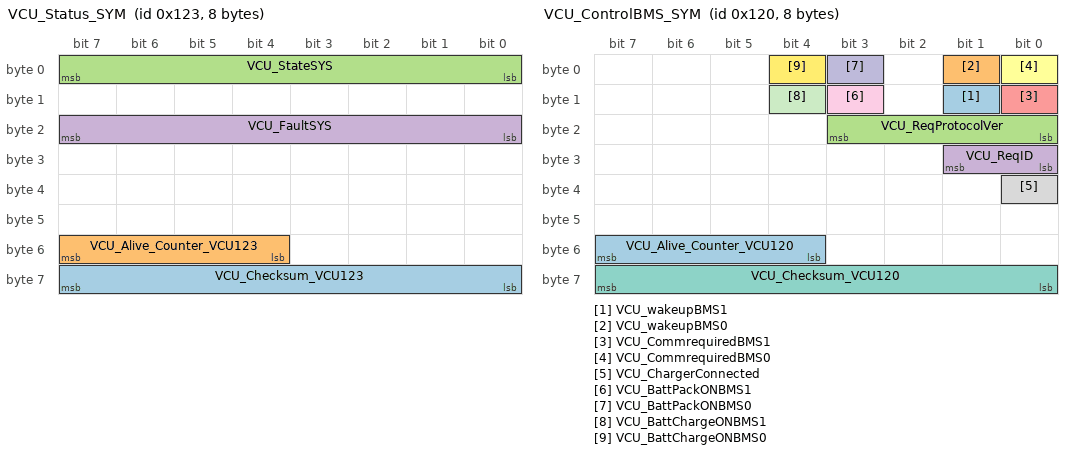
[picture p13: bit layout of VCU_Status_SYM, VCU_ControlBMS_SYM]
BO_ 291 VCU_Status_SYM: 8 VCU
 SG_ VCU_Checksum_VCU123 : 56|8@1+ (1,0) [0|255] ""  BMS1,BMS0
 SG_ VCU_Alive_Counter_VCU123 : 52|4@1+ (1,0) [0|15] ""  BMS1,BMS0
 SG_ VCU_StateSYS : 0|8@1+ (1,0) [0|255] ""  BMS1,BMS0
 SG_ VCU_FaultSYS : 16|8@1+ (1,0) [0|255] ""  BMS1,BMS0

BO_ 288 VCU_ControlBMS_SYM: 8 VCU
 SG_ VCU_wakeupBMS1 : 9|1@1+ (1,0) [0|1] ""  BMS1
 SG_ VCU_wakeupBMS0 : 1|1@1+ (1,0) [0|1] ""  BMS0
 SG_ VCU_ReqProtocolVer : 16|4@1+ (1,0) [0|15] ""  BMS1,BMS0
 SG_ VCU_ReqID : 24|2@1+ (1,0) [0|3] ""  BMS1,BMS0
 SG_ VCU_CommrequiredBMS1 : 8|1@1+ (1,0) [0|1] ""  BMS1
 SG_ VCU_CommrequiredBMS0 : 0|1@1+ (1,0) [0|1] ""  BMS0
 SG_ VCU_Checksum_VCU120 : 56|8@1+ (1,0) [0|255] ""  BMS1,BMS0
 SG_ VCU_ChargerConnected : 32|1@1+ (1,0) [0|1] ""  BMS1,BMS0
 SG_ VCU_BattPackONBMS1 : 11|1@1+ (1,0) [0|1] ""  BMS1
 SG_ VCU_BattPackONBMS0 : 3|1@1+ (1,0) [0|1] ""  BMS0
 SG_ VCU_BattChargeONBMS1 : 12|1@1+ (1,0) [0|1] ""  BMS1
 SG_ VCU_BattChargeONBMS0 : 4|1@1+ (1,0) [0|1] ""  BMS0
 SG_ VCU_Alive_Counter_VCU120 : 52|4@1+ (1,0) [0|15] ""  BMS1,BMS0

BO_ 1952 VCU_Mon_IO: 8 VCU
 SG_ Mon_KeyOnSw : 0|1@1+ (1,0) [0|1] "" Vector__XXX
 SG_ Mon_MCU_SUPPLY : 32|1@1+ (1,0) [0|1] "" Vector__XXX
 SG_ Mon_APP_SEN_SUPPLY : 33|1@1+ (1,0) [0|1] "" Vector__XXX
 SG_ Mon_ISO_CAN_BMS0_SUPPLY : 34|1@1+ (1,0) [0|1] "" Vector__XXX
 SG_ Mon_ChargeStsSw : 8|1@1+ (1,0) [0|1] "" Vector__XXX
 SG_ Mon_AppSw : 11|1@1+ (1,0) [0|1] "" Vector__XXX
 SG_ Mon_PassingSw : 18|1@1+ (1,0) [0|1] "" Vector__XXX
 SG_ Mon_RegenSw : 17|1@1+ (1,0) [0|1] "" Vector__XXX
 SG_ Mon_L_TurnSigSw : 2|1@1+ (1,0) [0|1] "" Vector__XXX
 SG_ Mon_R_TurnSigSw : 3|1@1+ (1,0) [0|1] "" Vector__XXX
 SG_ Mon_DCDC_RELAY : 36|1@1+ (1,0) [0|1] "" Vector__XXX
 SG_ Mon_LowBeamSw : 4|1@1+ (1,0) [0|1] "" Vector__XXX
 SG_ Mon_SeatOpenSw : 16|1@1+ (1,0) [0|1] "" Vector__XXX
 SG_ Mon_StartSw : 1|1@1+ (1,0) [0|1] "" Vector__XXX
 SG_ Mon_EmergencySw : 9|1@1+ (1,0) [0|1] "" Vector__XXX
 SG_ Mon_ReverseSw : 19|1@1+ (1,0) [0|1] "" Vector__XXX
 SG_ Mon_HignBeamSw : 5|1@1+ (1,0) [0|1] "" Vector__XXX
 SG_ Mon_BoostSw : 13|1@1+ (1,0) [0|1] "" Vector__XXX
 SG_ Mon_L_BatSw : 6|1@1+ (1,0) [0|1] "" Vector__XXX
 SG_ Mon_SeatOpenStsSw : 12|1@1+ (1,0) [0|1] "" Vector__XXX
 SG_ Mon_TripSw : 10|1@1+ (1,0) [0|1] "" Vector__XXX
 SG_ Mon_BatCoverOpenStsSw : 15|1@1+ (1,0) [0|1] "" Vector__XXX
 SG_ Mon_BrakeSw : 14|1@1+ (1,0) [0|1] "" Vector__XXX
 SG_ Mon_R_BatSw : 7|1@1+ (1,0) [0|1] "" Vector__XXX
 SG_ Mon_ISO_CAN_BMS1_SUPPLY : 35|1@1+ (1,0) [0|1] "" Vector__XXX
 SG_ Mon_SideStandSw : 20|1@1+ (1,0) [0|1] "" Vector__XXX
 SG_ Mon_HandleLock_Sol_N : 40|1@1+ (1,0) [0|1] "" Vector__XXX
 SG_ Mon_HandleLock_Sol_P : 41|1@1+ (1,0) [0|1] "" Vector__XXX
 SG_ Mon_Speaker_P : 43|1@1+ (1,0) [0|1] "" Vector__XXX
 SG_ Mon_Speaker_N : 42|1@1+ (1,0) [0|1] "" Vector__XXX
 SG_ Mon_HighBeamLamp : 46|1@1+ (1,0) [0|1] "" Vector__XXX
 SG_ Mon_LowBeamLamp : 45|1@1+ (1,0) [0|1] "" Vector__XXX
 SG_ Mon_L_TurnSigLamp : 51|1@1+ (1,0) [0|1] "" Vector__XXX
 SG_ Mon_ReverseLamp : 48|1@1+ (1,0) [0|1] "" Vector__XXX
 SG_ Mon_R_TurnSigLamp : 52|1@1+ (1,0) [0|1] "" Vector__XXX
 SG_ Mon_TailLamp : 44|1@1+ (1,0) [0|1] "" Vector__XXX
 SG_ Mon_WarningLamp2 : 50|1@1+ (1,0) [0|1] "" Vector__XXX
 SG_ Mon_WarningLamp1 : 49|1@1+ (1,0) [0|1] "" Vector__XXX
 SG_ Mon_CAN_LDO_EN : 24|1@1+ (1,0) [0|1] "" Vector__XXX
 SG_ Mon_Boost_Mod : 56|8@1+ (1,0) [0|255] "" Vector__XXX

BO_ 812 BMS1_ctrlCharger: 8 BMS1
 SG_ bms1_ctrlChargerTimeToFull : 32|16@1+ (1,0) [0|65535] "min"  VCU
 SG_ bms1_ctrlChargerLimitVoltage : 16|16@1+ (0.002,0) [0|131.07] "V"  CHARGER_S,VCU
 SG_ bms1_ctrlChargerLimitCurrent : 0|16@1- (0.02,0) [-655|655] "A"  CHARGER_S,VCU

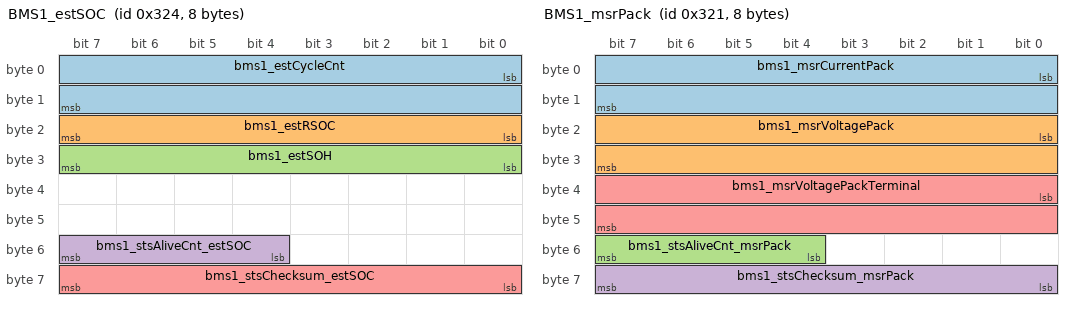
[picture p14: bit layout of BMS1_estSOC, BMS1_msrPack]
BO_ 804 BMS1_estSOC: 8 BMS1
 SG_ bms1_estCycleCnt : 0|16@1+ (1,0) [0|65535] ""  VCU
 SG_ bms1_estRSOC : 16|8@1+ (1,0) [0|255] "%"  VCU,CHARGER_S
 SG_ bms1_estSOH : 24|8@1+ (1,0) [0|255] "%"  VCU,CHARGER_S
 SG_ bms1_stsAliveCnt_estSOC : 52|4@1+ (1,0) [0|15] ""  VCU
 SG_ bms1_stsChecksum_estSOC : 56|8@1+ (1,0) [0|255] ""  VCU

BO_ 801 BMS1_msrPack: 8 BMS1
 SG_ bms1_msrCurrentPack : 0|16@1- (0.02,0) [-655|655] "A"  VCU,CHARGER_S
 SG_ bms1_msrVoltagePack : 16|16@1+ (0.002,0) [0|131.07] "V"  VCU,CHARGER_S
 SG_ bms1_stsAliveCnt_msrPack : 52|4@1+ (1,0) [0|15] ""  VCU
 SG_ bms1_stsChecksum_msrPack : 56|8@1+ (1,0) [0|255] ""  VCU
 SG_ bms1_msrVoltagePackTerminal : 32|16@1+ (0.002,0) [0|131.07] "V"  VCU,CHARGER_S

BO_ 800 BMS1_stsBMS: 8 BMS1
 SG_ bms1_stsAbnormalChargerCtrl : 48|1@1+ (1,0) [0|1] "" Vector__XXX
 SG_ bms1_stsBmsMode : 0|4@1+ (1,0) [0|15] ""  VCU,BMS0,CHARGER_S
 SG_ bms1_stsBmsState : 4|4@1+ (1,0) [0|15] ""  VCU,BMS0,CHARGER_S
 SG_ bms1_stsCurrentDirection : 14|2@1+ (1,0) [0|3] ""  VCU,BMS0,CHARGER_S
 SG_ bms1_stsDiagInfo : 16|8@1+ (1,0) [0|255] ""  VCU,BMS0,CHARGER_S
 SG_ bms1_stsFullyCharged : 26|2@1+ (1,0) [0|3] ""  VCU,BMS0,CHARGER_S
 SG_ bms1_stsIgnitionRecog : 24|2@1+ (1,0) [0|3] ""  VCU,BMS0,CHARGER_S
 SG_ bms1_stsPrechargeFET : 8|2@1+ (1,0) [0|3] ""  VCU,BMS0,CHARGER_S
 SG_ bms1_stsPwrCFET : 10|2@1+ (1,0) [0|3] ""  VCU,BMS0,CHARGER_S
 SG_ bms1_stsPwrDFET : 12|2@1+ (1,0) [0|3] ""  VCU,BMS0,CHARGER_S
 SG_ bms1_stsAliveCnt_stsBMS : 52|4@1+ (1,0) [0|15] ""  VCU,BMS0
 SG_ bms1_stsChecksum_stsBMS : 56|8@1+ (1,0) [0|255] ""  VCU,BMS0
 SG_ bms1_DiagMsg_Charger_Control : 28|2@1+ (1,0) [0|3] ""  VCU,CHARGER_S
 SG_ bms1_DiagMsg_Charger_Diag : 30|2@1+ (1,0) [0|3] ""  VCU,CHARGER_S
 SG_ bms1_DiagMsg_Charger_Status : 32|2@1+ (1,0) [0|3] ""  VCU,CHARGER_S
 SG_ bms1_DiagMsg_VCU_Control : 34|2@1+ (1,0) [0|3] ""  VCU
 SG_ bms1_DiagMsg_VCU_ODO : 36|2@1+ (1,0) [0|3] ""  VCU
 SG_ bms1_DiagMsg_VCU_Status : 38|2@1+ (1,0) [0|3] ""  VCU
 SG_ bms1_stsToogleMesaure : 50|1@1+ (1,0) [0|1] "-"  VCU
 SG_ bms1_stsToogleRunning : 51|1@1+ (1,0) [0|1] "-"  VCU
 SG_ bms1_stsLowSoheAlarm : 49|1@1+ (1,0) [0|1] "" Vector__XXX

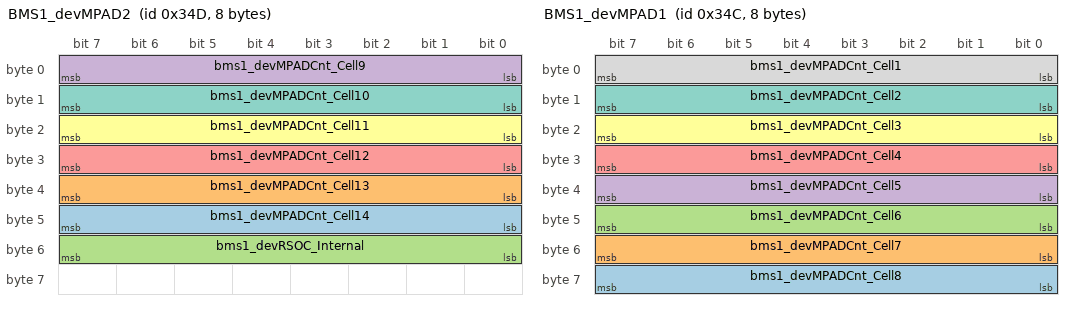
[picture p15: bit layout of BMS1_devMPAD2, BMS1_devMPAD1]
BO_ 845 BMS1_devMPAD2: 8 BMS1
 SG_ bms1_devMPADCnt_Cell14 : 40|8@1+ (1,0) [0|255] "" Vector__XXX
 SG_ bms1_devMPADCnt_Cell13 : 32|8@1+ (1,0) [0|255] "" Vector__XXX
 SG_ bms1_devRSOC_Internal : 48|8@1+ (1,0) [0|255] "%"  VCU
 SG_ bms1_devMPADCnt_Cell9 : 0|8@1+ (1,0) [0|255] ""  VCU
 SG_ bms1_devMPADCnt_Cell12 : 24|8@1+ (1,0) [0|255] ""  VCU
 SG_ bms1_devMPADCnt_Cell11 : 16|8@1+ (1,0) [0|255] ""  VCU
 SG_ bms1_devMPADCnt_Cell10 : 8|8@1+ (1,0) [0|255] ""  VCU

BO_ 844 BMS1_devMPAD1: 8 BMS1
 SG_ bms1_devMPADCnt_Cell8 : 56|8@1+ (1,0) [0|255] ""  VCU
 SG_ bms1_devMPADCnt_Cell7 : 48|8@1+ (1,0) [0|255] ""  VCU
 SG_ bms1_devMPADCnt_Cell6 : 40|8@1+ (1,0) [0|255] ""  VCU
 SG_ bms1_devMPADCnt_Cell5 : 32|8@1+ (1,0) [0|255] ""  VCU
 SG_ bms1_devMPADCnt_Cell4 : 24|8@1+ (1,0) [0|255] ""  VCU
 SG_ bms1_devMPADCnt_Cell3 : 16|8@1+ (1,0) [0|255] ""  VCU
 SG_ bms1_devMPADCnt_Cell2 : 8|8@1+ (1,0) [0|255] ""  VCU
 SG_ bms1_devMPADCnt_Cell1 : 0|8@1+ (1,0) [0|255] ""  VCU

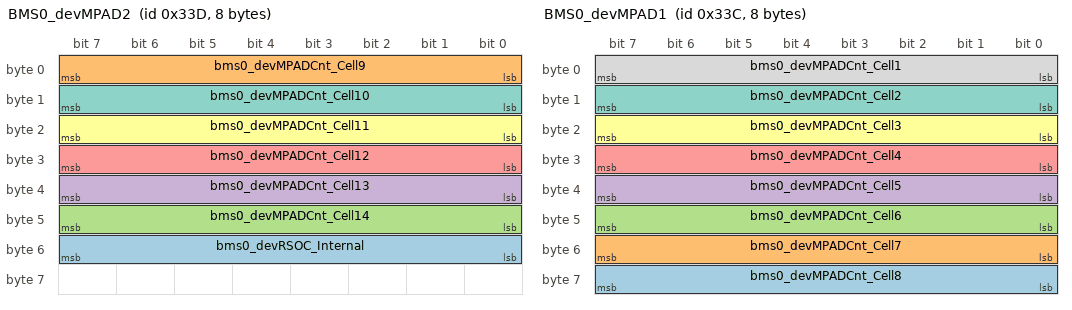
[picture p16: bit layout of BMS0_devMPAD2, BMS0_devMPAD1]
BO_ 829 BMS0_devMPAD2: 8 BMS0
 SG_ bms0_devRSOC_Internal : 48|8@1+ (1,0) [0|255] "%"  VCU
 SG_ bms0_devMPADCnt_Cell9 : 0|8@1+ (1,0) [0|255] ""  VCU
 SG_ bms0_devMPADCnt_Cell14 : 40|8@1+ (1,0) [0|255] ""  VCU
 SG_ bms0_devMPADCnt_Cell13 : 32|8@1+ (1,0) [0|255] ""  VCU
 SG_ bms0_devMPADCnt_Cell12 : 24|8@1+ (1,0) [0|255] ""  VCU
 SG_ bms0_devMPADCnt_Cell11 : 16|8@1+ (1,0) [0|255] ""  VCU
 SG_ bms0_devMPADCnt_Cell10 : 8|8@1+ (1,0) [0|255] ""  VCU

BO_ 828 BMS0_devMPAD1: 8 BMS0
 SG_ bms0_devMPADCnt_Cell8 : 56|8@1+ (1,0) [0|255] ""  VCU
 SG_ bms0_devMPADCnt_Cell7 : 48|8@1+ (1,0) [0|255] ""  VCU
 SG_ bms0_devMPADCnt_Cell6 : 40|8@1+ (1,0) [0|255] ""  VCU
 SG_ bms0_devMPADCnt_Cell5 : 32|8@1+ (1,0) [0|255] ""  VCU
 SG_ bms0_devMPADCnt_Cell4 : 24|8@1+ (1,0) [0|255] ""  VCU
 SG_ bms0_devMPADCnt_Cell3 : 16|8@1+ (1,0) [0|255] ""  VCU
 SG_ bms0_devMPADCnt_Cell2 : 8|8@1+ (1,0) [0|255] ""  VCU
 SG_ bms0_devMPADCnt_Cell1 : 0|8@1+ (1,0) [0|255] ""  VCU

BO_ 775 BMS0_MPAD2: 8 BMS0
 SG_ bms0_MPAD_EndUpdateRollCnt : 0|32@1+ (1,0) [0|4294967295] ""  REFLASH
 SG_ bms0_MPAD_EndAbDetAndBitFlag : 32|32@1+ (1,0) [0|4294967295] ""  REFLASH

BO_ 774 BMS0_MPAD1: 8 BMS0
 SG_ bms0_MPAD_StartUpdateRollCnt : 0|32@1+ (1,0) [0|4294967295] ""  REFLASH
 SG_ bms0_MPAD_StartAbDetAndBitFlag : 32|32@1+ (1,0) [0|4294967295] ""  REFLASH

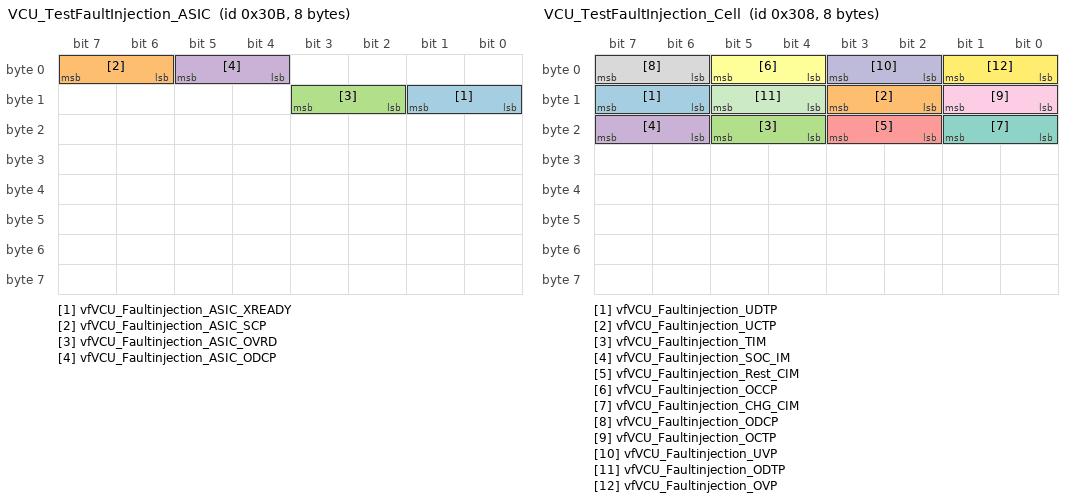
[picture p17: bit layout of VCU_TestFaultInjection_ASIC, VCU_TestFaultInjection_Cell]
BO_ 779 VCU_TestFaultInjection_ASIC: 8 VCU
 SG_ vfVCU_Faultinjection_ASIC_XREADY : 8|2@1+ (1,0) [0|1] ""  BMS1,BMS0
 SG_ vfVCU_Faultinjection_ASIC_SCP : 6|2@1+ (1,0) [0|1] ""  BMS1,BMS0
 SG_ vfVCU_Faultinjection_ASIC_OVRD : 10|2@1+ (1,0) [0|1] ""  BMS1,BMS0
 SG_ vfVCU_Faultinjection_ASIC_ODCP : 4|2@1+ (1,0) [0|1] ""  BMS1,BMS0

BO_ 776 VCU_TestFaultInjection_Cell: 8 VCU
 SG_ vfVCU_Faultinjection_UDTP : 14|2@1+ (1,0) [0|1] ""  BMS1,BMS0
 SG_ vfVCU_Faultinjection_UCTP : 10|2@1+ (1,0) [0|1] ""  BMS1,BMS0
 SG_ vfVCU_Faultinjection_TIM : 20|2@1+ (1,0) [0|1] ""  BMS1,BMS0
 SG_ vfVCU_Faultinjection_SOC_IM : 22|2@1+ (1,0) [0|1] ""  BMS1,BMS0
 SG_ vfVCU_Faultinjection_Rest_CIM : 18|2@1+ (1,0) [0|1] ""  BMS1,BMS0
 SG_ vfVCU_Faultinjection_OCCP : 4|2@1+ (1,0) [0|1] ""  BMS1,BMS0
 SG_ vfVCU_Faultinjection_CHG_CIM : 16|2@1+ (1,0) [0|1] ""  BMS1,BMS0
 SG_ vfVCU_Faultinjection_ODCP : 6|2@1+ (1,0) [0|1] ""  BMS1,BMS0
 SG_ vfVCU_Faultinjection_OCTP : 8|2@1+ (1,0) [0|1] ""  BMS1,BMS0
 SG_ vfVCU_Faultinjection_UVP : 2|2@1+ (1,0) [0|1] ""  BMS1,BMS0
 SG_ vfVCU_Faultinjection_ODTP : 12|2@1+ (1,0) [0|1] ""  BMS1,BMS0
 SG_ vfVCU_Faultinjection_OVP : 0|2@1+ (1,0) [0|1] ""  BMS1,BMS0

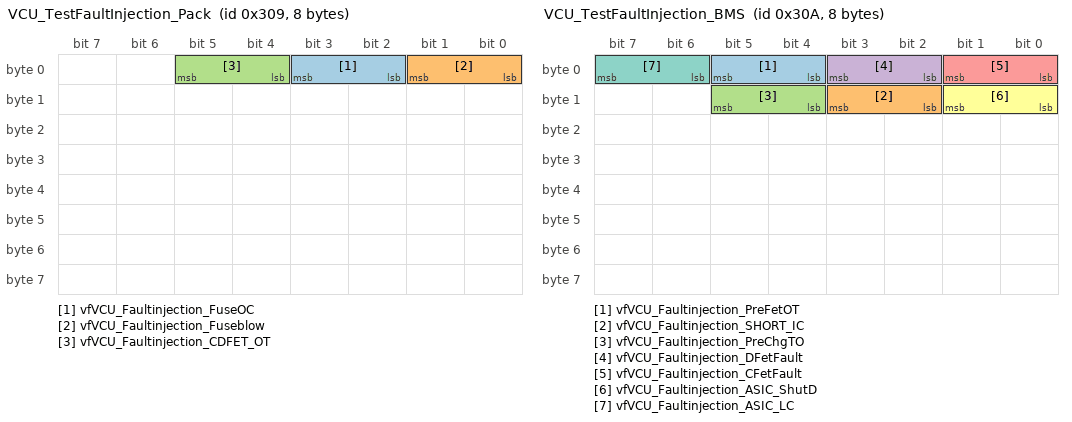
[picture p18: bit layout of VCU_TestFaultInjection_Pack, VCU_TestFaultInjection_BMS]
BO_ 777 VCU_TestFaultInjection_Pack: 8 VCU
 SG_ vfVCU_Faultinjection_FuseOC : 2|2@1+ (1,0) [0|1] ""  BMS1,BMS0
 SG_ vfVCU_Faultinjection_Fuseblow : 0|2@1+ (1,0) [0|1] ""  BMS1,BMS0
 SG_ vfVCU_Faultinjection_CDFET_OT : 4|2@1+ (1,0) [0|1] ""  BMS1,BMS0

BO_ 778 VCU_TestFaultInjection_BMS: 8 VCU
 SG_ vfVCU_Faultinjection_PreFetOT : 4|2@1+ (1,0) [0|1] ""  BMS0,BMS1
 SG_ vfVCU_Faultinjection_SHORT_IC : 10|2@1+ (1,0) [0|1] ""  BMS1,BMS0
 SG_ vfVCU_Faultinjection_PreChgTO : 12|2@1+ (1,0) [0|1] ""  BMS1,BMS0
 SG_ vfVCU_Faultinjection_DFetFault : 2|2@1+ (1,0) [0|1] ""  BMS1,BMS0
 SG_ vfVCU_Faultinjection_CFetFault : 0|2@1+ (1,0) [0|1] ""  BMS1,BMS0
 SG_ vfVCU_Faultinjection_ASIC_ShutD : 8|2@1+ (1,0) [0|1] ""  BMS1,BMS0
 SG_ vfVCU_Faultinjection_ASIC_LC : 6|2@1+ (1,0) [0|1] ""  BMS1,BMS0

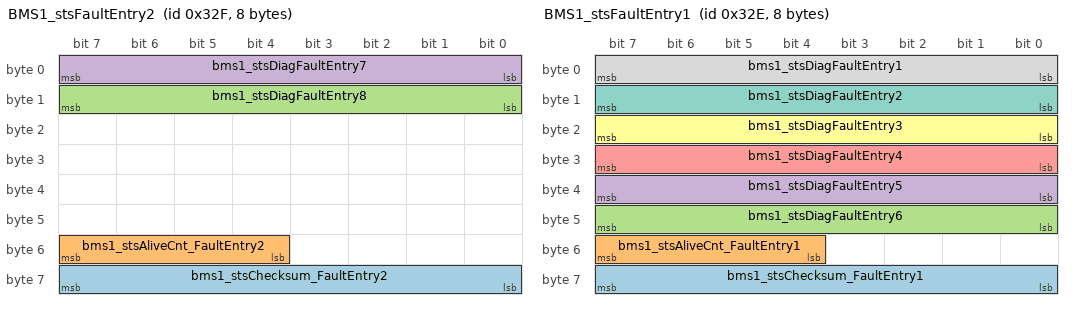
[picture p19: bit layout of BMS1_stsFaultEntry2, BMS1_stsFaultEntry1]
BO_ 815 BMS1_stsFaultEntry2: 8 BMS1
 SG_ bms1_stsChecksum_FaultEntry2 : 56|8@1+ (1,0) [0|255] ""  VCU
 SG_ bms1_stsAliveCnt_FaultEntry2 : 52|4@1+ (1,0) [0|15] ""  VCU
 SG_ bms1_stsDiagFaultEntry8 : 8|8@1+ (1,0) [0|255] ""  VCU
 SG_ bms1_stsDiagFaultEntry7 : 0|8@1+ (1,0) [0|255] ""  VCU

BO_ 814 BMS1_stsFaultEntry1: 8 BMS1
 SG_ bms1_stsChecksum_FaultEntry1 : 56|8@1+ (1,0) [0|255] ""  VCU
 SG_ bms1_stsAliveCnt_FaultEntry1 : 52|4@1+ (1,0) [0|15] ""  VCU
 SG_ bms1_stsDiagFaultEntry6 : 40|8@1+ (1,0) [0|255] ""  VCU
 SG_ bms1_stsDiagFaultEntry5 : 32|8@1+ (1,0) [0|255] ""  VCU
 SG_ bms1_stsDiagFaultEntry4 : 24|8@1+ (1,0) [0|255] ""  VCU
 SG_ bms1_stsDiagFaultEntry3 : 16|8@1+ (1,0) [0|255] ""  VCU
 SG_ bms1_stsDiagFaultEntry2 : 8|8@1+ (1,0) [0|255] ""  VCU
 SG_ bms1_stsDiagFaultEntry1 : 0|8@1+ (1,0) [0|255] ""  VCU

CM_ BU_ CHARGER_S "Series charger";
CM_ BU_ VCU "Vehicle control unit";
CM_ BU_ CHARGER_C "Cradle Charger";
CM_ BU_ HMI "Human interface";
CM_ BU_ MCU "Motor control unit";
CM_ BU_ REFLASH "Reflash tool (Boot update tool)";
CM_ BU_ BMS1 "48V Battery Pack0 (LGC)";
CM_ BU_ BMS0 "48V Battery Pack0 (LGC)";
CM_ BO_ 2432176283 "Message from MCU motor controller to instrument";
CM_ SG_ 2432176283 MCU_W_Phase_Current "Motor W-phase Current";
CM_ SG_ 2432176283 MCU_V_Phase_Current "Motor V-phase Current";
CM_ SG_ 2432176283 MCU_U_Phase_Current "Motor U-phase Current";
CM_ SG_ 2633237211 IPM_IoT_VSTD1Range "= SOC * 30km";
CM_ SG_ 2633237211 IPM_IoT_VSTD0Range "= SOC * 30km";
CM_ SG_ 2633237211 IPM_IoT_VehicleSpeed "= rpm * wheel diameter * speed coefficient";
CM_ SG_ 2633237211 IPM_IoT_RemainedRange "= main battery remaining capacity Ah * 1.5
1회 충전 주행거리가 나오면, 1.5는 수정될 예정";
CM_ BO_ 2550878453 "BMS #1 Failure Code";
CM_ SG_ 2550878453 BMS1_VoltageAcquisitionFailure "1: Voltage Acquisition Failure (such as collecting a single series of cell voltage 0V), 0: None";
CM_ SG_ 2550878453 BMS1_TotalUndervoltage "1: Total Undervoltage, 0: None";
CM_ SG_ 2550878453 BMS1_TotalOvervoltage "1: Total Overvoltage, 0: None";
CM_ SG_ 2550878453 BMS1_TempAcquisitionFailure "1: Temperature Acquisition Failure, 0: None";
CM_ SG_ 2550878453 BMS1_MosTemperature "1: MOS Temperature Fail, 0: None";
CM_ SG_ 2550878453 BMS1_MosHighTemperature "1: MOS High Temperature Protection, 0: None";
CM_ SG_ 2550878453 BMS1_LoadAccess "1: Load Access, 0: None
(Reserved)";
CM_ SG_ 2550878453 BMS1_FullCharging "1: Full Charging Protection, 0: None";
CM_ SG_ 2550878453 BMS1_EnvironLowTemperature "1: Environmental Low Temperature Protection, 0: None";
CM_ SG_ 2550878453 BMS1_EnvironHighTemperature "1: Environmental High Temperature Protection, 0: None";
CM_ SG_ 2550878453 BMS1_Discharging "1: Discharging, 0: No discharging";
CM_ SG_ 2550878453 BMS1_DischargeShortCircuit "1: Discharge Short Circuit Protection, 0: None";
CM_ SG_ 2550878453 BMS1_DischargeOvercurrent "1: Discharge Overcurrent Protection, 0: None";
CM_ SG_ 2550878453 BMS1_DischargeMosOn "1: Discharge MOS On, 0: None";
CM_ SG_ 2550878453 BMS1_DischargeMosFailure "1: Discharge MOS Failure, 0: None";
CM_ SG_ 2550878453 BMS1_DischargeLowTemperature "1: Discharge Low Temperature Protection, 0: None";
CM_ SG_ 2550878453 BMS1_DischargeHighTemperature "1: Discharge High Temperature Protection, 0: None";
CM_ SG_ 2550878453 BMS1_ChargingOvercurrent "1: Charging Overcurrent Protection, 0: None";
CM_ SG_ 2550878453 BMS1_ChargingMosFailure "1: Charging MOS Failure, 0: None";
CM_ SG_ 2550878453 BMS1_ChargingLowTemperature "1: Charging Low Temperature Protection, 0: None";
CM_ SG_ 2550878453 BMS1_ChargingHighTemperature "1: Charging High Temperature Protection, 0: None";
CM_ SG_ 2550878453 BMS1_Charging "1: Charging, 0: No charging";
CM_ SG_ 2550878453 BMS1_ChargerisConnected "1: Charger is Connected, 0: Charger is not connected";
CM_ SG_ 2550878453 BMS1_ChargeMosOn "1: Charge MOS On, 0: None";
CM_ SG_ 2550878453 BMS1_CellVoltageDifference "1: Battery Cell Voltage Difference (maximum cell voltage and minimum cell voltage difference greater than 0.3V), 0: None";
CM_ SG_ 2550878453 BMS1_CellUndervoltage "1: Cell Undervoltage, 0: None";
CM_ SG_ 2550878453 BMS1_CellOvervoltage "1: Cell Overvoltage, 0: None";
CM_ SG_ 2550878453 BMS1_AmbientTemperature "1: Ambient Temperature Fail, 0: None";
CM_ BO_ 2550878452 "BMS #0 Failure Code";
CM_ SG_ 2550878452 BMS0_VoltageAcquisitionFailure "1: Voltage Acquisition Failure (such as collecting a single series of cell voltage 0V), 0: None";
CM_ SG_ 2550878452 BMS0_TotalUndervoltage "1: Total Undervoltage, 0: None";
CM_ SG_ 2550878452 BMS0_TotalOvervoltage "1: Total Overvoltage, 0: None";
CM_ SG_ 2550878452 BMS0_TempAcquisitionFailure "1: Temperature Acquisition Failure, 0: None";
CM_ SG_ 2550878452 BMS0_MosTemperature "1: MOS Temperature Fail, 0: None";
CM_ SG_ 2550878452 BMS0_MosHighTemperature "1: MOS High Temperature Protection, 0: None";
CM_ SG_ 2550878452 BMS0_LoadAccess "1: Load Access, 0: None
(Reserved)";
CM_ SG_ 2550878452 BMS0_FullCharging "1: Full Charging Protection, 0: None";
CM_ SG_ 2550878452 BMS0_EnvironLowTemperature "1: Environmental Low Temperature Protection, 0: None";
CM_ SG_ 2550878452 BMS0_EnvironHighTemperature "1: Environmental High Temperature Protection, 0: None";
CM_ SG_ 2550878452 BMS0_Discharging "1: Discharging, 0: No discharging";
CM_ SG_ 2550878452 BMS0_DischargeShortCircuit "1: Discharge Short Circuit Protection, 0: None";
CM_ SG_ 2550878452 BMS0_DischargeOvercurrent "1: Discharge Overcurrent Protection, 0: None";
CM_ SG_ 2550878452 BMS0_DischargeMosOn "1: Discharge MOS On, 0: None";
CM_ SG_ 2550878452 BMS0_DischargeMosFailure "1: Discharge MOS Failure, 0: None";
CM_ SG_ 2550878452 BMS0_DischargeLowTemperature "1: Discharge Low Temperature Protection, 0: None";
CM_ SG_ 2550878452 BMS0_DischargeHighTemperature "1: Discharge High Temperature Protection, 0: None";
CM_ SG_ 2550878452 BMS0_ChargingOvercurrent "1: Charging Overcurrent Protection, 0: None";
CM_ SG_ 2550878452 BMS0_ChargingMosFailure "1: Charging MOS Failure, 0: None";
CM_ SG_ 2550878452 BMS0_ChargingLowTemperature "1: Charging Low Temperature Protection, 0: None";
CM_ SG_ 2550878452 BMS0_ChargingHighTemperature "1: Charging High Temperature Protection, 0: None";
CM_ SG_ 2550878452 BMS0_Charging "1: Charging, 0: No charging";
CM_ SG_ 2550878452 BMS0_ChargerisConnected "1: Charger is Connected, 0: Charger is not connected";
CM_ SG_ 2550878452 BMS0_ChargeMosOn "1: Charge MOS On, 0: None";
CM_ SG_ 2550878452 BMS0_CellVoltageDifference "1: Battery Cell Voltage Difference (maximum cell voltage and minimum cell voltage difference greater than 0.3V), 0: None";
CM_ SG_ 2550878452 BMS0_CellUndervoltage "1: Cell Undervoltage, 0: None";
CM_ SG_ 2550878452 BMS0_CellOvervoltage "1: Cell Overvoltage, 0: None";
CM_ SG_ 2550878452 BMS0_AmbientTemperature "1: Ambient Temperature Fail, 0: None";
CM_ BO_ 1426 "SBC Input/Output Voltage and Current";
CM_ BO_ 2550588917 "BMS #0 Charger Output Control Information
When BMS(A), BMS(B) is online at the same time, the charger only responds to BMS with low voltage.
";
CM_ SG_ 2550588917 BMS1_OutputControl "0: Charging.
1: Battery protection, Charger off
";
CM_ SG_ 2550588917 BMS1_MaxVoltage "Maximum allowable charging voltage";
CM_ SG_ 2550588917 BMS1_MaxCurrent "Maximum allowable charging current
";
CM_ BO_ 2550747381 "BMS #0 Debugging Information";
CM_ SG_ 2550747381 BMS1_VersionNumber "Version number";
CM_ BO_ 2550812917 "BMS #0
Design capacity
Remaining capacity
Charging status
Is it heating?
Cycle count";
CM_ SG_ 2550812917 BMS1_CycleCount "BMS #0 cycle count";
CM_ SG_ 2550812917 BMS1_RemainingCapacity "Remaining capacity";
CM_ SG_ 2550812917 BMS1_Heating "1: Heating
0: Unheated";
CM_ SG_ 2550812917 BMS1_DesignCapacity "Design capacity";
CM_ SG_ 2550812917 BMS1_ChargingStatus "1: Charging
0: not charging (Included CIN)
";
CM_ BO_ 2550681845 "BMS #0 System Status";
CM_ SG_ 2550681845 BMS1_OCC_ODC_SC "1:error, 0:none
Charging overcurrent, discharge overcurrent, short circuit.";
CM_ SG_ 2550681845 BMS1_MOS_Over_Temp "1:error, 0:none
Environmental, MOS high temperature protection";
CM_ SG_ 2550681845 BMS1_HardException "1: error, 0: none
voltage acquisition failure, temperature acquisition failure, charging and discharging MOS failure, etc
";
CM_ SG_ 2550681845 BMS1_CellVoltage_Difference "1:error, 0:none
Maximum cell voltage and minimum cell voltage difference greater than 0.3V";
CM_ SG_ 2550681845 BMS1_CellCore_OverUnder_Temp "1:error, 0:none
Battery charging/discharging high/low temperature protection

";
CM_ SG_ 2550681845 BMS1_Current "Battery current";
CM_ SG_ 2550681845 BMS1_TotalVoltage "Total battery voltage";
CM_ SG_ 2550681845 BMS1_SOC "SOC";
CM_ SG_ 2550681845 BMS1_MosRelayStatus "Bit0: Discharge MOS/Relay 0=Off 1=ON
Bit1: Charging MOS/Relay 0=Off 1=ON
";
CM_ BO_ 2550616309 "BMS #0 Battery Temperature Information (0-3)";
CM_ SG_ 2550616309 BMS1_Temperature3 "Battery temperature";
CM_ SG_ 2550616309 BMS1_Temperature2 "Battery temperature";
CM_ SG_ 2550616309 BMS1_Temperature1 "Battery temperature";
CM_ SG_ 2550616309 BMS1_Temperature0 "Battery temperature";
CM_ BO_ 2550550773 "BMS #0 Battery Cell Voltage Information (20-23) ";
CM_ SG_ 2550550773 BMS1_Cell_23_Voltage "Battery cell voltage";
CM_ SG_ 2550550773 BMS1_Cell_22_Voltage "Battery cell voltage";
CM_ SG_ 2550550773 BMS1_Cell_21_Voltage "Battery cell voltage";
CM_ SG_ 2550550773 BMS1_Cell_20_Voltage "Battery cell voltage";
CM_ BO_ 2550485237 "BMS #0 Battery Cell Voltage Information (16-19)";
CM_ SG_ 2550485237 BMS1_Cell_19_Voltage "Battery cell voltage";
CM_ SG_ 2550485237 BMS1_Cell_18_Voltage "Battery cell voltage";
CM_ SG_ 2550485237 BMS1_Cell_17_Voltage "Battery cell voltage";
CM_ SG_ 2550485237 BMS1_Cell_16_Voltage "Battery cell voltage";
CM_ BO_ 2550419701 "BMS #0 Battery Cell Voltage Information (12-15)";
CM_ SG_ 2550419701 BMS1_Cell_15_Voltage "Battery cell voltage";
CM_ SG_ 2550419701 BMS1_Cell_14_Voltage "Battery cell voltage";
CM_ SG_ 2550419701 BMS1_Cell_13_Voltage "Battery cell voltage";
CM_ SG_ 2550419701 BMS1_Cell_12_Voltage "Battery cell voltage";
CM_ BO_ 2550354165 "BMS #0 Battery Cell Voltage Information (8-11)";
CM_ SG_ 2550354165 BMS1_Cell_10_Voltage "Battery cell voltage";
CM_ SG_ 2550354165 BMS1_Cell_9_Voltage "Battery cell voltage";
CM_ SG_ 2550354165 BMS1_Cell_8_Voltage "Battery cell voltage";
CM_ SG_ 2550354165 BMS1_Cell_11_Voltage "Battery cell voltage";
CM_ BO_ 2550288629 "BMS #0 Battery Cell Voltage Information (4-7)";
CM_ SG_ 2550288629 BMS1_Cell_7_Voltage "Battery cell voltage";
CM_ SG_ 2550288629 BMS1_Cell_6_Voltage "Battery cell voltage";
CM_ SG_ 2550288629 BMS1_Cell_5_Voltage "Battery cell voltage";
CM_ SG_ 2550288629 BMS1_Cell_4_Voltage "Battery cell voltage";
CM_ BO_ 2550223093 "BMS #0 Battery Cell Voltage Information (0-3)";
CM_ SG_ 2550223093 BMS1_Cell_3_Voltage "Battery cell voltage";
CM_ SG_ 2550223093 BMS1_Cell_2_Voltage "Battery cell voltage";
CM_ SG_ 2550223093 BMS1_Cell_1_Voltage "Battery cell voltage";
CM_ SG_ 2550223093 BMS1_Cell_0_Voltage "Battery cell voltage";
CM_ BO_ 2566869221 "Charger output status information";
CM_ SG_ 2566869221 Charger_Status_Temperature "0: Normal
1: Charger temperature is too high to protect
";
CM_ SG_ 2566869221 Charger_Status_InputVoltage "0: Input voltage is normal
1: input voltage error, charger stop working
";
CM_ SG_ 2566869221 Charger_Status_HardwareFailure "0: Normal
1: Hardware failure
";
CM_ SG_ 2566869221 Charger_Status_Communication "0: Communication is normal
1: Communication reception timeout
";
CM_ SG_ 2566869221 Charger_Status_BatteryAccess "0: The battery is connected normally
1: The battery is not connected or the battery is reversed
(Initially, the BMS does not close the relay between the charger and the battery, so the charger will report failure 1 when it is powered on.)
";
CM_ SG_ 2566869221 Charger_Voltage "Charger output voltage";
CM_ SG_ 2566869221 Charger_Current "Charger output current";
CM_ BO_ 2550588916 "BMS #0 Charger Output Control Information
When BMS(A), BMS(B) is online at the same time, the charger only responds to BMS with low voltage.
";
CM_ SG_ 2550588916 BMS0_OutputControl "0: Charging.
1: Battery protection, Charger off
";
CM_ SG_ 2550588916 BMS0_MaxVoltage "Maximum allowable charging voltage";
CM_ SG_ 2550588916 BMS0_MaxCurrent "Maximum allowable charging current
";
CM_ BO_ 2550747380 "BMS #0 Debugging Information";
CM_ SG_ 2550747380 BMS0_VersionNumber "Version number";
CM_ BO_ 2550812916 "BMS #0
Design capacity
Remaining capacity
Charging status
Is it heating?
Cycle count";
CM_ SG_ 2550812916 BMS0_CycleCount "BMS #0 cycle count";
CM_ SG_ 2550812916 BMS0_RemainingCapacity "Remaining capacity";
CM_ SG_ 2550812916 BMS0_Heating "1: Heating
0: Unheated";
CM_ SG_ 2550812916 BMS0_DesignCapacity "Design capacity";
CM_ SG_ 2550812916 BMS0_ChargingStatus "1: Charging
0: not charging (Included CIN)
";
CM_ BO_ 2550681844 "BMS #0 System Status";
CM_ SG_ 2550681844 BMS0_OCC_ODC_SC "1:error, 0:none
Charging overcurrent, discharge overcurrent, short circuit.";
CM_ SG_ 2550681844 BMS0_MOS_Over_Temp "1:error, 0:none
Environmental, MOS high temperature protection";
CM_ SG_ 2550681844 BMS0_HardException "1: error, 0: none
voltage acquisition failure, temperature acquisition failure, charging and discharging MOS failure, etc
";
CM_ SG_ 2550681844 BMS0_CellVoltage_Difference "1:error, 0:none
Maximum cell voltage and minimum cell voltage difference greater than 0.3V";
CM_ SG_ 2550681844 BMS0_CellCore_OverUnder_Temp "1:error, 0:none
Battery charging/discharging high/low temperature protection

";
CM_ SG_ 2550681844 BMS0_Current "Battery current";
CM_ SG_ 2550681844 BMS0_TotalVoltage "Total battery voltage";
CM_ SG_ 2550681844 BMS0_SOC "SOC";
CM_ SG_ 2550681844 BMS0_MosRelayStatus "Bit0: Discharge MOS/Relay 0=Off 1=ON
Bit1: Charging MOS/Relay 0=Off 1=ON
";
CM_ BO_ 2550616308 "BMS #0 Battery Temperature Information (0-3)";
CM_ SG_ 2550616308 BMS0_Temperature3 "Battery temperature";
CM_ SG_ 2550616308 BMS0_Temperature2 "Battery temperature";
CM_ SG_ 2550616308 BMS0_Temperature1 "Battery temperature";
CM_ SG_ 2550616308 BMS0_Temperature0 "Battery temperature";
CM_ BO_ 2550550772 "BMS #0 Battery Cell Voltage Information (20-23) ";
CM_ SG_ 2550550772 BMS0_Cell_23_Voltage "Battery cell voltage";
CM_ SG_ 2550550772 BMS0_Cell_22_Voltage "Battery cell voltage";
CM_ SG_ 2550550772 BMS0_Cell_21_Voltage "Battery cell voltage";
CM_ SG_ 2550550772 BMS0_Cell_20_Voltage "Battery cell voltage";
CM_ BO_ 2550485236 "BMS #0 Battery Cell Voltage Information (16-19)";
CM_ SG_ 2550485236 BMS0_Cell_19_Voltage "Battery cell voltage";
CM_ SG_ 2550485236 BMS0_Cell_18_Voltage "Battery cell voltage";
CM_ SG_ 2550485236 BMS0_Cell_17_Voltage "Battery cell voltage";
CM_ SG_ 2550485236 BMS0_Cell_16_Voltage "Battery cell voltage";
CM_ BO_ 2550419700 "BMS #0 Battery Cell Voltage Information (12-15)";
CM_ SG_ 2550419700 BMS0_Cell_15_Voltage "Battery cell voltage";
CM_ SG_ 2550419700 BMS0_Cell_14_Voltage "Battery cell voltage";
CM_ SG_ 2550419700 BMS0_Cell_13_Voltage "Battery cell voltage";
CM_ SG_ 2550419700 BMS0_Cell_12_Voltage "Battery cell voltage";
CM_ BO_ 2550354164 "BMS #0 Battery Cell Voltage Information (8-11)";
CM_ SG_ 2550354164 BMS0_Cell_10_Voltage "Battery cell voltage";
CM_ SG_ 2550354164 BMS0_Cell_9_Voltage "Battery cell voltage";
CM_ SG_ 2550354164 BMS0_Cell_8_Voltage "Battery cell voltage";
CM_ SG_ 2550354164 BMS0_Cell_11_Voltage "Battery cell voltage";
CM_ BO_ 2550288628 "BMS #0 Battery Cell Voltage Information (4-7)";
CM_ SG_ 2550288628 BMS0_Cell_7_Voltage "Battery cell voltage";
CM_ SG_ 2550288628 BMS0_Cell_6_Voltage "Battery cell voltage";
CM_ SG_ 2550288628 BMS0_Cell_5_Voltage "Battery cell voltage";
CM_ SG_ 2550288628 BMS0_Cell_4_Voltage "Battery cell voltage";
CM_ BO_ 2550223092 "BMS #0 Battery Cell Voltage Information (0-3)";
CM_ SG_ 2550223092 BMS0_Cell_3_Voltage "Battery cell voltage";
CM_ SG_ 2550223092 BMS0_Cell_2_Voltage "Battery cell voltage";
CM_ SG_ 2550223092 BMS0_Cell_1_Voltage "Battery cell voltage";
CM_ SG_ 2550223092 BMS0_Cell_0_Voltage "Battery cell voltage";
CM_ BO_ 2566869232 "IPM instrument sends setup instructions to BMS
";
CM_ SG_ 2566869232 IPM_BMS_SetChargingCurrent "Set BMS allowable charging current";
CM_ SG_ 2566869232 IPM_BMS_FullChargeSocSwitch "0: SOC charging limit off (full charging)
1: SOC charging limit on
";
CM_ SG_ 2566869232 IPM_BMS_FullChargeSocSetting "0: read status (BMS cycle)
1: set status (IPM sends two frames)";
CM_ SG_ 2566869232 IPM_BMS_FullChargeSocLimit "Set full SOC
Charging power SOC minimum limit of 10%

";
CM_ SG_ 2566869232 IPM_BMS_ChargingLimitSwitch "0: turn off low power charging (max output)
1: turn on low power charging (set the current to the max allowable current for BMS according to yte3)
";
CM_ SG_ 2566869232 IPM_BMS_ChargingLimitSetting "Whether to set the current charging power limit current.
0: read status (BMS cycle)
1: set status (IPM sends two frames)
";
CM_ BO_ 2633236955 "Instrument data status";
CM_ SG_ 2633236955 IPM_MCU_ODOmileage "Instrument display total mileage
mileage data / km";
CM_ SG_ 2633236955 IPM_BCM_VersionYear "version number: year";
CM_ SG_ 2633236955 IPM_BCM_VersionMonth "version number: month";
CM_ SG_ 2633236955 IPM_BCM_VersionDay "version number: day";
CM_ SG_ 2633236955 IPM_BCM_AmbientBrightness "Ambient brightness level
01-level 1 (darkest)
02-level 2 (dark)
03-level 3 (dark)
Turn on (Auto mode)
04-level 4
05-level 5
06-level 6
do not switch
07-level 2 (light)
08-level 5 (light)
09-level 7 (brightest)
Turn off (Auto mode)
";
CM_ BO_ 2550685947 "Other keystrokes state and state command";
CM_ SG_ 2550685947 BCM_IPM_NFCcardCountdown "After entering card distribution mode, card distribution timeout countdown
";
CM_ SG_ 2550685947 BCM_IPM_BCMVersion "BCM Version Number";
CM_ SG_ 2550685947 BCM_IPM_ChargerAccess "charger access status
0: Not connected (disconnected)
1: Accessed (unlocked)";
CM_ SG_ 2550685947 BCM_IPM_ACC_Status "Bucket lock control After opening ACC,
Instrument screen off + forced P gear
0: not open
1: turned on (instrument off)";
CM_ SG_ 2550685947 BCM_IPM_WidnshieldMotor "Windshield status
0: off / disabled / no action
1: shelf forward moving
2: shelf backward moving
3: blocking / limiting protection
";
CM_ SG_ 2550685947 BCM_IPM_TapLock "0: locked
1: unlocked
";
CM_ SG_ 2550685947 BCM_IPM_SideSupporter "Side supporter sensor
0: drop
1: put away
";
CM_ SG_ 2550685947 BCM_IPM_ShelfMotor "Back shelf status
0: off / disabled / no action
1: shelf forward moving
2: shelf backward moving
3: blocking / limiting protection
";
CM_ SG_ 2550685947 BCM_IPM_PedalLock "0: locked (closed)
1: unlocked (opened)
";
CM_ SG_ 2550685947 BCM_IPM_NfcCardStatus "Card status: Number of cards
0: no card status
1: 1 card has been allocated
2: 2 cards have been allocated
3: 3 cards allocated (maximum)";
CM_ SG_ 2550685947 BCM_IPM_NfcCardModeCountdown "After entering card distribution mode, card distribution timeout countdown
";
CM_ SG_ 2550685947 BCM_IPM_NfcCardFeedback "Packa result feedback (Readable in card mode)
0: no feedback
1: card successful (1/3)
2: card successful (2/3)
3: card successful (3/3)
";
CM_ SG_ 2550685947 BCM_IPM_NfcCardDistribution "Card distribution mode
0: normal mode / exited
1: card distribution mode (1/3)
2: card distribution mode (2/3)
3: card distribution mode (3/3)
";
CM_ SG_ 2550685947 BCM_IPM_Motion "Three axis sensor
0: stopped
1: moving";
CM_ SG_ 2550685947 BCM_IPM_MechanicalKeyAcc "External ACC status (mechanical key open)
Note: Detects external ACC start-up, no defense (IoT state) within 1s, then synchronizes the tap lock unlock instruction
0: none
1: valid";
CM_ SG_ 2550685947 BCM_IPM_InternalAcc "BCM outputs ACC
Note: When the external ACC is currently judged to be 1. BCM cannot open/close internal ACC
0: none
1: valid
";
CM_ SG_ 2550685947 BCM_IPM_Inclination "Three axis sensor
0: normal
1: fall over";
CM_ SG_ 2550685947 BCM_IPM_HeatingSeat "Heating seat bucket operation status
0: off (disabled)
1: 1 stage heating
2: 2 stage heating
3: 3 stage heating
";
CM_ SG_ 2550685947 BCM_IPM_CombinationAuto "Bucket lock: Auto + P gear + No brake 1.5s;
Open pedal lock: Auto + P gear + Brake 1.5s;
Open ACC: Bluetooth valid + Seat valid + Auto click;
Close ACC: Motion stop + Emergency stopping signal + Auto 1.5s;
0: none
1: valid
";
CM_ SG_ 2550685947 BCM_IPM_BucketLock "0: locked (closed)
1: unlocked (opened)
";
CM_ SG_ 2550685947 BCM_IPM_HeatingHandle "Heating handle operation status
0: off (disabled)
1: 1 stage heating
2: 2 stage heating
3: 3 stage heating
";
CM_ BO_ 2550681850 "MCU control command, status (off signal status)";
CM_ SG_ 2550681850 BCM_IPM_ScreenSwitching "1. Switch instruction, immediately feedback throw screen is not connected, disappear after 2s;
2. enter the projection screen, return to the riding interface, cycle switching

0:Default
1:Switching";
CM_ SG_ 2550681850 BCM_IPM_VSTDConnection "VSTD Access Status (CAN)
Standard frame 0x314 This message status

0: Default is not connected (5s prompt)
1: Accessed (5s reminder)";
CM_ SG_ 2550681850 BCM_IPM_RightSwitchConnection "Right Switch Connection Status (LIN)

0: Access is normal
1: abnormalities are not detected (fault long display)";
CM_ SG_ 2550681850 BCM_IPM_RearLamlConnection "Rear taillight connection status (LIN)

0: Access is normal
1: abnormalities are not detected (fault long display)";
CM_ SG_ 2550681850 BCM_IPM_LeftSwitchConnection "Left Switch Connection Status (LIN)

0: Access is normal
1: abnormalities are not detected (fault long display)";
CM_ SG_ 2550681850 BCM_IPM_HeadLamlConnection "Headlamp Connection Status (LIN)

0: Access is normal
1: abnormalities are not detected (fault long display)";
CM_ SG_ 2550681850 BCM_IPM_LowBrake "Click the low brake signal on the extinguishing button
release P gear: brake + low brake

0: none
1: valid";
CM_ SG_ 2550681850 BCM_IPM_ReverseGear_ReturnCancel "0: none
1: valid
";
CM_ SG_ 2550681850 BCM_MCU_MotorSelfLearning "Controller self-learning instruction (BCM does not need)
0: default
1: self-learning
";
CM_ SG_ 2550681850 BCM_MCU_EmergencyExtinguishing "0: none
1: Off singnal / Forced P gear
";
CM_ SG_ 2550681850 BCM_MCU_Downshift "0: default
1: valid
";
CM_ SG_ 2550681850 BCM_MCU_Cruise "0: none
1: valid
";
CM_ SG_ 2550681850 BCM_MCU_ThrottleVoltage "Throttle signal output voltage";
CM_ SG_ 2550681850 BCM_MCU_CutOff_AutoButton "Cut-off_Auto button or Upshift_No 9 switch or High speed_pull switch
add time to judge: the controller needs to recognize signals such as click and click, long press, and double click.

0: default
1: valid";
CM_ SG_ 2550681850 BCM_MCU_SingleSupport "0: default
1: valid
";
CM_ SG_ 2550681850 BCM_MCU_DCDC_Voltage "Input voltage of BCM";
CM_ SG_ 2550681850 BCM_MCU_Brake "0: default
1: valid
";
CM_ BO_ 2550681849 "Lighting control instruction status (switch signal status)";
CM_ SG_ 2550681849 BCM_IPM_LightStatus_Passing "0: off
1: on";
CM_ SG_ 2550681849 BCM_IPM_DelayedPowerDown "Welcome home (all lights)
0: off
1: valid
";
CM_ SG_ 2550681849 BCM_IPM_AutoHeadLamp "Automatic Headlamp / Default on when power on
0: off
1: on";
CM_ SG_ 2550681849 BCM_IPM_WelcomeHome "Delayed power-off time
";
CM_ SG_ 2550681849 BCM_IPM_LightStatus_Turn_R "0: off
1: on";
CM_ SG_ 2550681849 BCM_IPM_LightStatus_Turn_L "0: off
1: on";
CM_ SG_ 2550681849 BCM_IPM_LightStatus_HighBeam "0: off
1: on";
CM_ SG_ 2550681849 BCM_IPM_LightStatus_HeadNear "0: off
1: on";
CM_ SG_ 2550681849 BCM_IPM_LightStatus_Brake "0: off
1: on";
CM_ SG_ 2550681849 BCM_IPM_LightFailure_Turn_R "0: none
1: failure
";
CM_ SG_ 2550681849 BCM_IPM_LightFailure_Turn_L "0: none
1: failure
";
CM_ SG_ 2550681849 BCM_IPM_LightFailure_HighBeam "0: none
1: failure
";
CM_ SG_ 2550681849 BCM_IPM_LightFailure_HeadNear "0: none
1: failure
";
CM_ SG_ 2550681849 BCM_IPM_LightFailure_Brake "0: none
1: failure
";
CM_ SG_ 2550681849 BCM_IPM_LightCurrent_Turn_R "R-turn lamp current
BCM output current";
CM_ SG_ 2550681849 BCM_IPM_LightCurrent_Turn_L "L-turn lamp current
BCM output current";
CM_ SG_ 2550681849 BCM_IPM_LightCurrent_HighBeam "High beam lamp current
BCM output current";
CM_ SG_ 2550681849 BCM_IPM_LightCurrent_HeadNear "Head light (near) lamp current
BCM output current";
CM_ SG_ 2550681849 BCM_IPM_LightCurrent_Brake "Brake lamp current
BCM output current";
CM_ BO_ 2432176251 "Message from MCU motor controller to instrument";
CM_ SG_ 2432176251 MCU_IPM_MCUHWVersion "MCU Hardware Version
11 = V1.1";
CM_ SG_ 2432176251 MCU_IPM_MCUFWVersion "MCU Firmware Version
11 = V1.1";
CM_ SG_ 2432176251 MCU_IPM_TorqueLimit "Maximum torque limit (%)";
CM_ SG_ 2432176251 MCU_IPM_EnergyRecoverySwitch "0: Invalid - Turn off energy recovery
1: valid - Enable energy recovery
";
CM_ SG_ 2432176251 MCU_IPM_EnergyRecoveryPercentage "Energy recovery intensity
Maximum energy recovery strength : 100%";
CM_ SG_ 2432176251 MCU_IPM_SpeedLimit "Maximum motor speed limit";
CM_ SG_ 2432176251 MCU_IPM_Gear "Used to correlate the maximum speed limit and torque limit, 
the maximum speed limit and output torque parameters under this range
Gear: 1st / 2nd / 3rd, cycle

1: 1st gear speed torque
2: 2nd gear speed torque
3: 3rd gear speed torque
";
CM_ BO_ 2432176269 "Message from MCU motor controller to instrument";
CM_ SG_ 2432176269 MCU_IPM_Ready "0: READY is not displayed
1: READY displayed";
CM_ SG_ 2432176269 MCU_IPM_P_Gear "0: P gear
1: P gear removed
";
CM_ SG_ 2432176269 MCU_IPM_Temperature "Motor Temperature";
CM_ SG_ 2432176269 MCU_IPM_Current "Current line output current";
CM_ SG_ 2432176269 MCU_IPM_Voltage "Current input voltage";
CM_ SG_ 2432176269 MCU_IPM_ChargingProtection "0: Not detected
1: Tested (Charged anti-walking)
";
CM_ BO_ 2432176282 "Message from MCU motor controller to instrument";
CM_ SG_ 2432176282 MCU_IPM_MotorReverseCurrent "Motor reverse current";
CM_ SG_ 2432176282 MCU_IPM_GearSpeed "0: Low speed (1st gear)
1: Medium speed (2nd gear)
2: High speed (3rd gear)";
CM_ SG_ 2432176282 MCU_IPM_FailureCode "See Failure Code List";
CM_ SG_ 2432176282 MCU_IPM_ControllerTemperature "Controller temperature";
CM_ SG_ 2432176282 MCU_IPM_MotorRPM "Motor speed";
CM_ SG_ 2432176282 MCU_IPM_SpeedMode "0: High speed
1: Low speed
";
CM_ SG_ 2432176282 MCU_IPM_StandingSlope "0: No standing slope
1: Standing on the slope
";
CM_ SG_ 2432176282 MCU_IPM_Cruse "0: No Cruise
1: Cruise
";
CM_ SG_ 2432176282 MCU_IPM_Brake "0: No brakes
1: Brake valid
";
CM_ SG_ 2432176282 MCU_IPM_Direction "00: Invalid/Default
01: Moving forward
10: Backward
";
CM_ BO_ 1425 "acknwledge of command and alive counter";
CM_ SG_ 1425 SBC_BMS_AliveCounter "increase by 1 each time when transmitting this message";
CM_ SG_ 1425 SBC_BMS_OnOffAck "1: charging on

2: charging off
";
CM_ BO_ 1424 "commands to control the SBC";
CM_ SG_ 1424 BMS_SBC_SbcOn "0:off, 1:on";
CM_ BO_ 773 "Test Command";
CM_ SG_ 773 bms0_devDebugSox_Flag "Status of cell balancing circuit.";
CM_ SG_ 773 bms0_devDebugTemp_Flag "Status of cell balancing circuit.";
CM_ SG_ 773 bms0_devDebugCurrent_Flag "Status of cell balancing circuit.";
CM_ SG_ 773 bms0_devDebugCellVolt_Flag "Status of cell balancing circuit.";
CM_ BO_ 872 "Status of battery pack.";
CM_ SG_ 872 bms1_msrCurrentPackStd "Measuring pack current,  charging is positive, discharging is negative.";
CM_ BO_ 856 "Status of battery pack.";
CM_ SG_ 856 bms0_msrCurrentPackStd "Measuring pack current,  charging is positive, discharging is negative.";
CM_ BO_ 855 "SOHR Avg, Max, Min";
CM_ SG_ 855 bms0_estSOHRMinNo "State of health.";
CM_ SG_ 855 bms0_estSOHRMin "State of health.";
CM_ SG_ 855 bms0_estSOHRMaxNo "State of health.";
CM_ SG_ 855 bms0_estSOHRMax "State of health.";
CM_ SG_ 855 bms0_estSOHRAvg "State of health.";
CM_ BO_ 854 "SOHE Avg, Max, Min";
CM_ SG_ 854 bms0_estSOHEMinNo "State of health.";
CM_ SG_ 854 bms0_estSOHEMin "State of health.";
CM_ SG_ 854 bms0_estSOHEMaxNo "State of health.";
CM_ SG_ 854 bms0_estSOHEMax "State of health.";
CM_ SG_ 854 bms0_estSOHEAvg "State of health.";
CM_ BO_ 869 "DVFD count for each Cell";
CM_ SG_ 869 bms1_stsDVFDCntCell14 "DVFD Count for each cell";
CM_ SG_ 869 bms1_stsDVFDCntCell13 "DVFD Count for each cell";
CM_ SG_ 869 bms1_stsDVFDCntCell12 "DVFD Count for each cell";
CM_ SG_ 869 bms1_stsDVFDCntCell11 "DVFD Count for each cell";
CM_ SG_ 869 bms1_stsDVFDCntCell10 "DVFD Count for each cell";
CM_ SG_ 869 bms1_stsDVFDCntCell9 "DVFD Count for each cell";
CM_ SG_ 869 bms1_stsDVFDCntCell8 "DVFD Count for each cell";
CM_ BO_ 868 "DVFD count for each Cell";
CM_ SG_ 868 bms1_stsDVFDCntCell7 "DVFD Count for each cell";
CM_ SG_ 868 bms1_stsDVFDCntCell6 "DVFD Count for each cell";
CM_ SG_ 868 bms1_stsDVFDCntCell5 "DVFD Count for each cell";
CM_ SG_ 868 bms1_stsDVFDCntCell4 "DVFD Count for each cell";
CM_ SG_ 868 bms1_stsDVFDCntCell3 "DVFD Count for each cell";
CM_ SG_ 868 bms1_stsDVFDCntCell2 "DVFD Count for each cell";
CM_ SG_ 868 bms1_stsDVFDCntCell1 "DVFD Count for each cell";
CM_ BO_ 853 "DVFD count for each Cell";
CM_ SG_ 853 bms0_stsDVFDCntCell14 "DVFD Count for each cell";
CM_ SG_ 853 bms0_stsDVFDCntCell13 "DVFD Count for each cell";
CM_ SG_ 853 bms0_stsDVFDCntCell12 "DVFD Count for each cell";
CM_ SG_ 853 bms0_stsDVFDCntCell11 "DVFD Count for each cell";
CM_ SG_ 853 bms0_stsDVFDCntCell10 "DVFD Count for each cell";
CM_ SG_ 853 bms0_stsDVFDCntCell9 "DVFD Count for each cell";
CM_ SG_ 853 bms0_stsDVFDCntCell8 "DVFD Count for each cell";
CM_ BO_ 852 "DVFD count for each Cell";
CM_ SG_ 852 bms0_stsDVFDCntCell7 "DVFD Count for each cell";
CM_ SG_ 852 bms0_stsDVFDCntCell6 "DVFD Count for each cell";
CM_ SG_ 852 bms0_stsDVFDCntCell5 "DVFD Count for each cell";
CM_ SG_ 852 bms0_stsDVFDCntCell4 "DVFD Count for each cell";
CM_ SG_ 852 bms0_stsDVFDCntCell3 "DVFD Count for each cell";
CM_ SG_ 852 bms0_stsDVFDCntCell2 "DVFD Count for each cell";
CM_ SG_ 852 bms0_stsDVFDCntCell1 "DVFD Count for each cell";
CM_ BO_ 865 "Accumulated Charging / Discharging Energy (for BSS)";
CM_ SG_ 865 bms1_estAccumEnergyDisc " Accumulated Discharging Energy";
CM_ SG_ 865 bms1_estAccumEnergyChg " Accumulated  Charging Energy";
CM_ BO_ 864 "Accumulated Charging / Discharging Capacity (for BSS)";
CM_ SG_ 864 bms1_estAccumCapacityDisc " Accumulated Discharging Capacity";
CM_ SG_ 864 bms1_estAccumCapacityChg " Accumulated Charging Capacity";
CM_ BO_ 849 "Accumulated Charging / Discharging Energy (for BSS)";
CM_ SG_ 849 bms0_estAccumEnergyDisc " Accumulated Discharging Energy";
CM_ SG_ 849 bms0_estAccumEnergyChg " Accumulated  Charging Energy";
CM_ BO_ 848 "Accumulated Charging / Discharging Capacity (for BSS)";
CM_ SG_ 848 bms0_estAccumCapacityDisc " Accumulated Discharging Capacity";
CM_ SG_ 848 bms0_estAccumCapacityChg " Accumulated Charging Capacity";
CM_ BO_ 847 "Cell temperature inside the battery pack. (Improved Resolution)";
CM_ SG_ 847 bms1_msrTempCell3Advanced "Cell3 Temperature - cell. (Improved Resolution)";
CM_ SG_ 847 bms1_msrTempCell2Advanced "Cell2 Temperature - cell. (Improved Resolution)";
CM_ SG_ 847 bms1_msrTempCell1Advanced "Cell1 Temperature - cell. (Improved Resolution)";
CM_ BO_ 831 "Cell temperature inside the battery pack. (Improved Resolution)";
CM_ SG_ 831 bms0_msrTempCell3Advanced "Cell3 Temperature - cell. (Improved Resolution)";
CM_ SG_ 831 bms0_msrTempCell2Advanced "Cell2 Temperature - cell. (Improved Resolution)";
CM_ SG_ 831 bms0_msrTempCell1Advanced "Cell1 Temperature - cell. (Improved Resolution)";
CM_ BO_ 846 "SOH, RSOC, Cycle count, ... of battery pack. (Improved Resolution)";
CM_ SG_ 846 bms1_estSOHAdvanced "State of health. (Improved Resolution)";
CM_ SG_ 846 bms1_estRSOCAdvanced "Relative State Of Charge. (Improved resolution)";
CM_ BO_ 830 "SOH, RSOC, Cycle count, ... of battery pack. (Improved Resolution)";
CM_ SG_ 830 bms0_estSOHAdvanced "State of health. (Improved Resolution)";
CM_ SG_ 830 bms0_estRSOCAdvanced "Relative State Of Charge. (Improved resolution)";
CM_ BO_ 294 "VCU - ODO Information";
CM_ BO_ 291 "VCU - VCU status";
CM_ BO_ 288 "VCU - BMS Control Message";
CM_ BO_ 812 "Status of Chariging status";
CM_ SG_ 812 bms1_ctrlChargerTimeToFull "Remaining Charging Time";
CM_ SG_ 812 bms1_ctrlChargerLimitVoltage "Voltage limitation value for charging (in case of fault, this value will be zero)";
CM_ SG_ 812 bms1_ctrlChargerLimitCurrent "Current limitation value for charging (in case of fault, this value will be zero)";
CM_ BO_ 804 "SOH, RSOC, Cycle count, ... of battery pack.";
CM_ SG_ 804 bms1_estCycleCnt "Cycle Count";
CM_ SG_ 804 bms1_estRSOC "Relative State Of Charge.";
CM_ SG_ 804 bms1_estSOH "State of health.";
CM_ SG_ 804 bms1_stsAliveCnt_estSOC "Alive count valure to check stuck message
(Value will be increased as like 0->1->2->…->15->0->1->2… every single transmit.)";
CM_ SG_ 804 bms1_stsChecksum_estSOC "Checksum value for each message
CS = BITWISEXOR([0],[1])
CS = BITWISEXOR(CS,[2])
CS = BITWISEXOR(CS,[3])
CS = BITWISEXOR(CS,[4])
CS = BITWISEXOR(CS,[5])
CS = BITWISEXOR(CS,[6])
[7] = CS";
CM_ BO_ 801 "Status of battery pack.";
CM_ SG_ 801 bms1_msrCurrentPack "Measuring pack current,  charging is positive, discharging is negative.";
CM_ SG_ 801 bms1_msrVoltagePack "Sum of all series cell voltage.";
CM_ SG_ 801 bms1_stsAliveCnt_msrPack "Alive count valure to check stuck message
(Value will be increased as like 0->1->2->…->15->0->1->2… every single transmit.)";
CM_ SG_ 801 bms1_stsChecksum_msrPack "Checksum value for each message
CS = BITWISEXOR([0],[1])
CS = BITWISEXOR(CS,[2])
CS = BITWISEXOR(CS,[3])
CS = BITWISEXOR(CS,[4])
CS = BITWISEXOR(CS,[5])
CS = BITWISEXOR(CS,[6])
[7] = CS";
CM_ SG_ 801 bms1_msrVoltagePackTerminal "voltage of battery terminal (p+,p-)";
CM_ BO_ 800 "Status of BMS.";
CM_ SG_ 800 bms1_stsAbnormalChargerCtrl "abnormal Charger current. > (limitcurrent * 1.1)";
CM_ SG_ 800 bms1_stsBmsMode "Present mode of the battery pack";
CM_ SG_ 800 bms1_stsBmsState "Present mode of the battery pack";
CM_ SG_ 800 bms1_stsCurrentDirection "Current(Amps) Direction";
CM_ SG_ 800 bms1_stsDiagInfo "This signal will be presented all diag. items status.";
CM_ SG_ 800 bms1_stsFullyCharged "Fully charged status. ";
CM_ SG_ 800 bms1_stsIgnitionRecog "Status that BMS recognizes ignition pin";
CM_ SG_ 800 bms1_stsPrechargeFET "control status of Precharge-FET";
CM_ SG_ 800 bms1_stsPwrCFET "control status of C-FET";
CM_ SG_ 800 bms1_stsPwrDFET "control status of D-FET";
CM_ SG_ 800 bms1_stsAliveCnt_stsBMS "Alive count valure to check stuck message
(Value will be increased as like 0->1->2->…->15->0->1->2… every single transmit.)";
CM_ SG_ 800 bms1_stsChecksum_stsBMS "Checksum value for each message
CS = BITWISEXOR([0],[1])
CS = BITWISEXOR(CS,[2])
CS = BITWISEXOR(CS,[3])
CS = BITWISEXOR(CS,[4])
CS = BITWISEXOR(CS,[5])
CS = BITWISEXOR(CS,[6])
[7] = CS";
CM_ SG_ 800 bms1_DiagMsg_Charger_Control "Message Diag.";
CM_ SG_ 800 bms1_DiagMsg_Charger_Diag "Message Diag.";
CM_ SG_ 800 bms1_DiagMsg_Charger_Status "Message Diag.";
CM_ SG_ 800 bms1_DiagMsg_VCU_Control "Message Diag.";
CM_ SG_ 800 bms1_DiagMsg_VCU_ODO "Message Diag.";
CM_ SG_ 800 bms1_DiagMsg_VCU_Status "Message Diag.";
CM_ SG_ 800 bms1_stsToogleMesaure "BMS Running toggle";
CM_ SG_ 800 bms1_stsToogleRunning "BMS Running toggle";
CM_ SG_ 800 bms1_stsLowSoheAlarm "low SOH alarm";
CM_ BO_ 845 "MPAD detect count";
CM_ SG_ 845 bms1_devMPADCnt_Cell14 "MPAD Count";
CM_ SG_ 845 bms1_devMPADCnt_Cell13 "MPAD Count";
CM_ SG_ 845 bms1_devRSOC_Internal "Relative State Of Charge. ( Internal )";
CM_ SG_ 845 bms1_devMPADCnt_Cell9 "MPAD Count";
CM_ SG_ 845 bms1_devMPADCnt_Cell12 "MPAD Count";
CM_ SG_ 845 bms1_devMPADCnt_Cell11 "MPAD Count";
CM_ SG_ 845 bms1_devMPADCnt_Cell10 "MPAD Count";
CM_ BO_ 844 "MPAD detect count";
CM_ SG_ 844 bms1_devMPADCnt_Cell8 "MPAD Count";
CM_ SG_ 844 bms1_devMPADCnt_Cell7 "MPAD Count";
CM_ SG_ 844 bms1_devMPADCnt_Cell6 "MPAD Count";
CM_ SG_ 844 bms1_devMPADCnt_Cell5 "MPAD Count";
CM_ SG_ 844 bms1_devMPADCnt_Cell4 "MPAD Count";
CM_ SG_ 844 bms1_devMPADCnt_Cell3 "MPAD Count";
CM_ SG_ 844 bms1_devMPADCnt_Cell2 "MPAD Count";
CM_ SG_ 844 bms1_devMPADCnt_Cell1 "MPAD Count";
CM_ BO_ 829 "MPAD detect count";
CM_ SG_ 829 bms0_devRSOC_Internal "Relative State Of Charge. ( Internal )";
CM_ SG_ 829 bms0_devMPADCnt_Cell9 "MPAD Count";
CM_ SG_ 829 bms0_devMPADCnt_Cell14 "MPAD Count";
CM_ SG_ 829 bms0_devMPADCnt_Cell13 "MPAD Count";
CM_ SG_ 829 bms0_devMPADCnt_Cell12 "MPAD Count";
CM_ SG_ 829 bms0_devMPADCnt_Cell11 "MPAD Count";
CM_ SG_ 829 bms0_devMPADCnt_Cell10 "MPAD Count";
CM_ BO_ 828 "MPAD detect count";
CM_ SG_ 828 bms0_devMPADCnt_Cell8 "MPAD Count";
CM_ SG_ 828 bms0_devMPADCnt_Cell7 "MPAD Count";
CM_ SG_ 828 bms0_devMPADCnt_Cell6 "MPAD Count";
CM_ SG_ 828 bms0_devMPADCnt_Cell5 "MPAD Count";
CM_ SG_ 828 bms0_devMPADCnt_Cell4 "MPAD Count";
CM_ SG_ 828 bms0_devMPADCnt_Cell3 "MPAD Count";
CM_ SG_ 828 bms0_devMPADCnt_Cell2 "MPAD Count";
CM_ SG_ 828 bms0_devMPADCnt_Cell1 "MPAD Count";
CM_ BO_ 775 "MPAD degug ( single pack )";
CM_ SG_ 775 bms0_MPAD_EndUpdateRollCnt "Pack life time mileage data (ODO data)";
CM_ SG_ 775 bms0_MPAD_EndAbDetAndBitFlag "Pack life time mileage data (ODO data)";
CM_ BO_ 774 "MPAD degug ( single pack )";
CM_ SG_ 774 bms0_MPAD_StartUpdateRollCnt "Pack life time mileage data (ODO data)";
CM_ SG_ 774 bms0_MPAD_StartAbDetAndBitFlag "Pack life time mileage data (ODO data)";
CM_ BO_ 779 "Test Command";
CM_ SG_ 779 vfVCU_Faultinjection_ASIC_XREADY "FaultInjection";
CM_ SG_ 779 vfVCU_Faultinjection_ASIC_SCP "FaultInjection";
CM_ SG_ 779 vfVCU_Faultinjection_ASIC_OVRD "FaultInjection";
CM_ SG_ 779 vfVCU_Faultinjection_ASIC_ODCP "FaultInjection";
CM_ BO_ 776 "Test Command";
CM_ SG_ 776 vfVCU_Faultinjection_UDTP "FaultInjection";
CM_ SG_ 776 vfVCU_Faultinjection_UCTP "FaultInjection";
CM_ SG_ 776 vfVCU_Faultinjection_TIM "FaultInjection";
CM_ SG_ 776 vfVCU_Faultinjection_SOC_IM "FaultInjection";
CM_ SG_ 776 vfVCU_Faultinjection_Rest_CIM "FaultInjection";
CM_ SG_ 776 vfVCU_Faultinjection_OCCP "FaultInjection";
CM_ SG_ 776 vfVCU_Faultinjection_CHG_CIM "FaultInjection";
CM_ SG_ 776 vfVCU_Faultinjection_ODCP "FaultInjection";
CM_ SG_ 776 vfVCU_Faultinjection_OCTP "FaultInjection";
CM_ SG_ 776 vfVCU_Faultinjection_UVP "FaultInjection";
CM_ SG_ 776 vfVCU_Faultinjection_ODTP "FaultInjection";
CM_ SG_ 776 vfVCU_Faultinjection_OVP "FaultInjection";
CM_ BO_ 777 "Test Command";
CM_ SG_ 777 vfVCU_Faultinjection_FuseOC "FaultInjection";
CM_ SG_ 777 vfVCU_Faultinjection_Fuseblow "FaultInjection";
CM_ SG_ 777 vfVCU_Faultinjection_CDFET_OT "FaultInjection";
CM_ BO_ 778 "Test Command";
CM_ SG_ 778 vfVCU_Faultinjection_PreFetOT "FaultInjection";
CM_ SG_ 778 vfVCU_Faultinjection_SHORT_IC "FaultInjection";
CM_ SG_ 778 vfVCU_Faultinjection_PreChgTO "FaultInjection : Precharge timeout";
CM_ SG_ 778 vfVCU_Faultinjection_DFetFault "FaultInjection";
CM_ SG_ 778 vfVCU_Faultinjection_CFetFault "FaultInjection";
CM_ SG_ 778 vfVCU_Faultinjection_ASIC_ShutD "FaultInjection";
CM_ SG_ 778 vfVCU_Faultinjection_ASIC_LC "FaultInjection";
CM_ BO_ 815 "FaultEntry ( 7~8 / 8 )";
CM_ SG_ 815 bms1_stsChecksum_FaultEntry2 "Checksum value for each message
CS = BITWISEXOR([0],[1])
CS = BITWISEXOR(CS,[2])
CS = BITWISEXOR(CS,[3])
CS = BITWISEXOR(CS,[4])
CS = BITWISEXOR(CS,[5])
CS = BITWISEXOR(CS,[6])
[7] = CS";
CM_ SG_ 815 bms1_stsAliveCnt_FaultEntry2 "Alive count valure to check stuck message
(Value will be increased as like 0->1->2->…->15->0->1->2… every single transmit.)";
CM_ SG_ 815 bms1_stsDiagFaultEntry8 "This signal will be presented diag. list ( 8/8 )";
CM_ SG_ 815 bms1_stsDiagFaultEntry7 "This signal will be presented diag. list ( 7/8 )";
CM_ BO_ 814 "FaultEntry ( 1~6 / 8 )";
CM_ SG_ 814 bms1_stsChecksum_FaultEntry1 "Checksum value for each message
CS = BITWISEXOR([0],[1])
CS = BITWISEXOR(CS,[2])
CS = BITWISEXOR(CS,[3])
CS = BITWISEXOR(CS,[4])
CS = BITWISEXOR(CS,[5])
CS = BITWISEXOR(CS,[6])
[7] = CS";
CM_ SG_ 814 bms1_stsAliveCnt_FaultEntry1 "Alive count valure to check stuck message
(Value will be increased as like 0->1->2->…->15->0->1->2… every single transmit.)";
CM_ SG_ 814 bms1_stsDiagFaultEntry6 "This signal will be presented diag. list ( 6/8 )";
CM_ SG_ 814 bms1_stsDiagFaultEntry5 "This signal will be presented diag. list ( 5/8 )";
CM_ SG_ 814 bms1_stsDiagFaultEntry4 "This signal will be presented diag. list ( 4/8 )";
CM_ SG_ 814 bms1_stsDiagFaultEntry3 "This signal will be presented diag. list ( 3/8 )";
CM_ SG_ 814 bms1_stsDiagFaultEntry2 "This signal will be presented diag. list ( 2/8 )";
CM_ SG_ 814 bms1_stsDiagFaultEntry1 "This signal will be presented diag. list ( 1/8 )";
BA_DEF_  "BusECUIdLength" INT 5 6;
BA_DEF_  "BusID" INT 0 255;
BA_DEF_  "BusName" STRING ;
BA_DEF_  "BusType" STRING ;
BA_DEF_  "DBName" STRING ;
BA_DEF_ BO_  "cycleMilliSecs100" INT 0 100;
BA_DEF_ BO_  "GenMsgCycleTime" INT 0 65000;
BA_DEF_ BO_  "GenMsgSendType" ENUM  "Fixed Periodic","Enabled Periodic","NoMsgSendType","Event";
BA_DEF_ BO_  "targetGw" ENUM  "BPG","BGW","IVI","SDCM","ALL";
BA_DEF_ BO_  "transmitMsgRateEthernetMs" ENUM  "10","100","1000";
BA_DEF_ BU_  "NmDefaultAddress" ENUM  "USE_PRIMARY_ADDRESS","USE_SECONDARY_ADDRESS";
BA_DEF_ BU_  "NodeLayerModules" STRING ;
BA_DEF_ SG_  "GenSigStartValue" INT 0 0;
BA_DEF_ SG_  "SNARequired" ENUM  "Required","NotRequired";
BA_DEF_DEF_  "BusECUIdLength" 5;
BA_DEF_DEF_  "BusID" 0;
BA_DEF_DEF_  "BusName" "AuxBattery";
BA_DEF_DEF_  "BusType" "CAN";
BA_DEF_DEF_  "DBName" "";
BA_DEF_DEF_  "cycleMilliSecs100" 100;
BA_DEF_DEF_  "GenMsgCycleTime" 0;
BA_DEF_DEF_  "GenMsgSendType" "NoMsgSendType";
BA_DEF_DEF_  "targetGw" "ALL";
BA_DEF_DEF_  "transmitMsgRateEthernetMs" "1000";
BA_DEF_DEF_  "NmDefaultAddress" "USE_PRIMARY_ADDRESS";
BA_DEF_DEF_  "NodeLayerModules" "CANoeILNLVector.dll";
BA_DEF_DEF_  "GenSigStartValue" 0;
BA_DEF_DEF_  "SNARequired" "Required";
BA_ "BusID" 136;
BA_ "BusName" "Battery";
BA_ "DBName" "EV";
BA_ "transmitMsgRateEthernetMs" BO_ 2550685947 1;
BA_ "transmitMsgRateEthernetMs" BO_ 2550681850 1;
BA_ "transmitMsgRateEthernetMs" BO_ 2550681849 1;
BA_ "transmitMsgRateEthernetMs" BO_ 2432176251 1;
BA_ "transmitMsgRateEthernetMs" BO_ 2432176269 1;
BA_ "transmitMsgRateEthernetMs" BO_ 2432176282 1;
BA_ "GenMsgCycleTime" BO_ 773 100;
BA_ "GenMsgSendType" BO_ 773 0;
BA_ "GenMsgSendType" BO_ 872 0;
BA_ "GenMsgCycleTime" BO_ 872 250;
BA_ "GenMsgSendType" BO_ 856 0;
BA_ "GenMsgCycleTime" BO_ 856 250;
BA_ "GenMsgCycleTime" BO_ 855 100;
BA_ "GenMsgSendType" BO_ 855 0;
BA_ "GenMsgCycleTime" BO_ 854 100;
BA_ "GenMsgSendType" BO_ 854 0;
BA_ "GenMsgSendType" BO_ 869 0;
BA_ "GenMsgCycleTime" BO_ 869 5000;
BA_ "GenMsgSendType" BO_ 868 0;
BA_ "GenMsgCycleTime" BO_ 868 5000;
BA_ "GenMsgSendType" BO_ 853 0;
BA_ "GenMsgCycleTime" BO_ 853 5000;
BA_ "GenMsgSendType" BO_ 852 0;
BA_ "GenMsgCycleTime" BO_ 852 5000;
BA_ "GenMsgSendType" BO_ 865 0;
BA_ "GenMsgCycleTime" BO_ 865 1000;
BA_ "GenMsgSendType" BO_ 864 0;
BA_ "GenMsgCycleTime" BO_ 864 1000;
BA_ "GenMsgSendType" BO_ 849 0;
BA_ "GenMsgCycleTime" BO_ 849 1000;
BA_ "GenMsgSendType" BO_ 848 0;
BA_ "GenMsgCycleTime" BO_ 848 1000;
BA_ "GenMsgSendType" BO_ 847 0;
BA_ "GenMsgCycleTime" BO_ 847 1000;
BA_ "GenMsgSendType" BO_ 831 0;
BA_ "GenMsgCycleTime" BO_ 831 1000;
BA_ "GenMsgSendType" BO_ 846 0;
BA_ "GenMsgCycleTime" BO_ 846 100;
BA_ "GenMsgSendType" BO_ 830 0;
BA_ "GenMsgCycleTime" BO_ 830 100;
BA_ "GenMsgCycleTime" BO_ 294 100;
BA_ "GenMsgSendType" BO_ 294 0;
BA_ "GenMsgCycleTime" BO_ 291 10;
BA_ "GenMsgSendType" BO_ 291 0;
BA_ "GenMsgCycleTime" BO_ 288 10;
BA_ "GenMsgSendType" BO_ 288 0;
BA_ "GenMsgSendType" BO_ 812 0;
BA_ "GenMsgCycleTime" BO_ 812 1000;
BA_ "GenMsgSendType" BO_ 804 0;
BA_ "GenMsgCycleTime" BO_ 804 100;
BA_ "GenMsgSendType" BO_ 801 0;
BA_ "GenMsgCycleTime" BO_ 801 150;
BA_ "GenMsgSendType" BO_ 800 0;
BA_ "GenMsgCycleTime" BO_ 800 10;
BA_ "GenMsgCycleTime" BO_ 845 1000;
BA_ "GenMsgSendType" BO_ 845 0;
BA_ "GenMsgCycleTime" BO_ 844 1000;
BA_ "GenMsgSendType" BO_ 844 0;
BA_ "GenMsgCycleTime" BO_ 829 1000;
BA_ "GenMsgSendType" BO_ 829 0;
BA_ "GenMsgCycleTime" BO_ 828 1000;
BA_ "GenMsgSendType" BO_ 828 0;
BA_ "GenMsgCycleTime" BO_ 775 250;
BA_ "GenMsgSendType" BO_ 775 0;
BA_ "GenMsgCycleTime" BO_ 774 250;
BA_ "GenMsgSendType" BO_ 774 0;
BA_ "GenMsgSendType" BO_ 779 0;
BA_ "GenMsgCycleTime" BO_ 779 100;
BA_ "GenMsgSendType" BO_ 776 0;
BA_ "GenMsgCycleTime" BO_ 776 100;
BA_ "GenMsgSendType" BO_ 777 0;
BA_ "GenMsgCycleTime" BO_ 777 100;
BA_ "GenMsgSendType" BO_ 778 0;
BA_ "GenMsgCycleTime" BO_ 778 100;
BA_ "GenMsgCycleTime" BO_ 815 100;
BA_ "GenMsgSendType" BO_ 815 0;
BA_ "GenMsgCycleTime" BO_ 814 100;
BA_ "GenMsgSendType" BO_ 814 0;
BA_ "GenSigStartValue" SG_ 2550616309 BMS1_Temperature3 400;
BA_ "GenSigStartValue" SG_ 2550616309 BMS1_Temperature2 400;
BA_ "GenSigStartValue" SG_ 2550616309 BMS1_Temperature1 400;
BA_ "GenSigStartValue" SG_ 2550616309 BMS1_Temperature0 400;
BA_ "GenSigStartValue" SG_ 2550616308 BMS0_Temperature3 400;
BA_ "GenSigStartValue" SG_ 2550616308 BMS0_Temperature2 400;
BA_ "GenSigStartValue" SG_ 2550616308 BMS0_Temperature1 400;
BA_ "GenSigStartValue" SG_ 2550616308 BMS0_Temperature0 400;
BA_ "GenSigStartValue" SG_ 2566869232 IPM_BMS_FullChargeSocLimit 100;
VAL_ 291 VCU_StateSYS 1 "Sleep" 0 "Shutdown" ;
VAL_ 291 VCU_FaultSYS 0 "-" ;
VAL_ 288 VCU_wakeupBMS1 1 "ON" 0 "OFF" ;
VAL_ 288 VCU_wakeupBMS0 1 "ON" 0 "OFF" ;
VAL_ 288 VCU_ReqProtocolVer 14 "RSVD" 13 "RSVD" 12 "RSVD" 11 "RSVD" 10 "RSVD" 9 "RSVD" 8 "RSVD" 7 "RSVD" 6 "RSVD" 5 "RSVD" 4 "RSVD" 3 "RSVD" 2 "WACCO" 1 "SYM" 0 "KEF" ;
VAL_ 288 VCU_ReqID 3 "RSVD" 2 "2nd Pack upper 1st Pack" 1 "1st Pack nearby GND" 0 "RSVD" ;
VAL_ 288 VCU_CommrequiredBMS1 0 "OFF" 1 "ON" ;
VAL_ 288 VCU_CommrequiredBMS0 0 "OFF" 1 "ON" ;
VAL_ 288 VCU_ChargerConnected 0 "OFF" 1 "ON" ;
VAL_ 288 VCU_BattPackONBMS1 0 "OFF" 1 "ON" ;
VAL_ 288 VCU_BattPackONBMS0 0 "OFF" 1 "ON" ;
VAL_ 288 VCU_BattChargeONBMS1 0 "OFF" 1 "ON" ;
VAL_ 288 VCU_BattChargeONBMS0 0 "OFF" 1 "ON" ;
VAL_ 800 bms1_stsBmsMode 0 "STANDBY Mode" 1 "SNA" 2 "SNA" 3 "WORKING Mode" ;
VAL_ 800 bms1_stsBmsState 0 "NORAML State" 1 "SLEEP State" 2 "SHUTDOWN State" 3 "MAINTENANCE State" ;
VAL_ 800 bms1_stsCurrentDirection 0 "REST" 1 "CHARGING" 2 "DISCHARGING" ;
VAL_ 800 bms1_stsDiagInfo 140 "Diag Cell - Diff SOHe_FAILURE" 139 "Diag Cell - Diff SOHe_FAULT" 138 "Diag Cell - Diff SOHe_WARN2" 137 "Diag Cell - Diff SOHe_WARN1" 136 "Diag Cell - Low SOHe_FAILURE" 135 "Diag Cell - Low SOHe_FAULT" 134 "Diag Cell - Low SOHe_WARN2" 133 "Diag Cell - Low SOHe_WARN1" 132 "Diag ASIC - OVERRIDE_FAILURE" 131 "Diag ASIC - OVERRIDE_FAULT" 130 "Diag ASIC - OVERRIDE_WARN2" 129 "Diag ASIC - OVERRIDE_WARN1" 128 "Diag ASIC - XREADY_FAILURE" 127 "Diag ASIC - XREADY_FAULT" 126 "Diag ASIC - XREADY_WARN2" 125 "Diag ASIC - XREADY_WARN1" 124 "SNA" 123 "SNA" 122 "SNA" 121 "SNA" 120 "Diag ASIC - SCD_FAILURE" 119 "Diag ASIC - SCD_FAULT" 118 "Diag ASIC - SCD_WARN2" 117 "Diag ASIC - SCD_WARN1" 116 "SNA" 115 "SNA" 114 "SNA" 113 "SNA" 112 "Diag ASIC - ODC_FAILURE" 111 "Diag ASIC - ODC_FAULT" 110 "Diag ASIC - ODC_WARN2" 109 "Diag ASIC - ODC_WARN1" 108 "Diag ASIC - UV_FAILURE" 107 "Diag ASIC - UV_FAULT" 106 "Diag ASIC - UV_WARN2" 105 "Diag ASIC - UV_WARN1" 104 "Diag ASIC - OV_FAILURE" 103 "Diag ASIC - OV_FAULT" 102 "Diag ASIC - OV_WARN2" 101 "Diag ASIC - OV_WARN1" 100 "Diag Pack - FETsOT_FAILURE" 99 "Diag Pack - FETsOT_FAULT" 98 "Diag Pack - FETsOT_WARN2" 97 "Diag Pack - FETsOT_WARN1" 96 "Diag Pack - FUSEOC_FAILURE" 95 "Diag Pack - FUSEOC_FAULT" 94 "Diag Pack - FUSEOC_WARN2" 93 "Diag Pack - FUSEOC_WARN1" 92 "Diag Pack - FUSEBLOW_FAILURE" 91 "Diag Pack - FUSEBLOW_FAULT" 90 "Diag Pack - FUSEBLOW_WARN2" 89 "Diag Pack - FUSEBLOW_WARN1" 88 "Diag Pack - FUSEROHM_FAILURE" 87 "Diag Pack - FUSEROHM_FAULT" 86 "Diag Pack - FUSEROHM_WARN2" 85 "Diag Pack - FUSEROHM_WARN1" 84 "Diag BMS- ASIC_LOC_FAILURE" 83 "Diag BMS- ASIC_LOC_FAULT" 82 "Diag BMS- ASIC_LOC_WARN2" 81 "Diag BMS- ASIC_LOC_WARN1" 80 "Diag BMS- ASIC_SHUTDOWN_FAILURE" 79 "Diag BMS- ASIC_SHUTDOWN_FAULT" 78 "Diag BMS- ASIC_SHUTDOWN_WARN2" 77 "Diag BMS- ASIC_SHUTDOWN_WARN1" 76 "Diag BMS- PFET_TIMEOUT_FAILURE" 75 "Diag BMS- PFET_TIMEOUT_FAULT" 74 "Diag BMS- PFET_TIMEOUT_WARN2" 73 "Diag BMS- PFET_TIMEOUT_WARN1" 72 "Diag BMS- PFET_OT_FAILURE" 71 "Diag BMS- PFET_OT_FAULT" 70 "Diag BMS- PFET_OT_WARN2" 69 "Diag BMS- PFET_OT_WARN1" 68 "Diag BMS- CFET_FAILURE" 67 "Diag BMS- CFET_FAULT" 66 "Diag BMS- CFET_WARN2" 65 "Diag BMS- CFET_WARN1" 64 "Diag BMS- DFET_FAILURE" 63 "Diag BMS- DFET_FAULT" 62 "Diag BMS- DFET_WARN2" 61 "Diag BMS- DFET_WARN1" 60 "Diag BMS- SHORT IC" 59 "Diag BMS- OVIC_FAULT" 58 "Diag BMS- OVIC_WARN2" 57 "Diag BMS- OVIC_WARN1" 56 "Diag Cell - SOC-IM_FAILURE" 55 "Diag Cell - SOC-IM_FAULT" 54 "Diag Cell - SOC-IM_WARN2" 53 "Diag Cell - SOC-IM_WARN1" 52 "Diag Cell - TIM_FAILURE" 51 "Diag Cell - TIM_FAULT" 50 "Diag Cell - TIM_WARN2" 49 "Diag Cell - TIM_WARN1" 48 "Diag Cell - CIM-REST_FAILURE" 47 "Diag Cell - CIM-REST_FAULT" 46 "Diag Cell - CIM-REST_WARN2" 45 "Diag Cell - CIM-REST_WARN1" 44 "Diag Cell - CIM-CHG_FAILURE" 43 "Diag Cell - CIM-CHG_FAULT" 42 "Diag Cell - CIM-CHG_WARN2" 41 "Diag Cell - CIM-CHG_WARN1" 40 "Diag Cell - UDTP_FAILURE" 39 "Diag Cell - UDTP_FAULT" 38 "Diag Cell - UDTP_WARN2" 37 "Diag Cell - UDTP_WARN1" 36 "Diag Cell - UCTP_FAILURE" 35 "Diag Cell - UCTP_FAULT" 34 "Diag Cell - UCTP_WARN2" 33 "Diag Cell - UCTP_WARN1" 32 "Diag Cell - ODTP_FAILURE" 31 "Diag Cell - ODTP_FAULT" 30 "Diag Cell - ODTP_WARN2" 29 "Diag Cell - ODTP_WARN1" 28 "Diag Cell - OCTP_FAILURE" 27 "Diag Cell - OCTP_FAULT" 26 "Diag Cell - OCTP_WARN2" 25 "Diag Cell - OCTP_WARN1" 24 "Diag Cell - ODCP_FAILURE" 23 "Diag Cell - ODCP_FAULT" 22 "Diag Cell - ODCP_WARN2" 21 "Diag Cell - ODCP_WARN1" 20 "Diag Cell - OCCP_FAILURE" 19 "Diag Cell - OCCP_FAULT" 18 "Diag Cell - OCCP_WARN2" 17 "Diag Cell - OCCP_WARN1" 16 "Diag Cell - UVP_PACK_FAILURE" 15 "Diag Cell - UVP_PACK_FAULT" 14 "Diag Cell - UVP_PACK_WARN2" 13 "Diag Cell - UVP_PACK_WARN1" 12 "Diag Cell - OVP_PACK_FAILURE" 11 "Diag Cell - OVP_PACK_FAULT" 10 "Diag Cell - OVP_PACK_WARN2" 9 "Diag Cell - OVP_PACK_WARN1" 8 "Diag Cell - UVP_FAILURE" 7 "Diag Cell - UVP_FAULT" 6 "Diag Cell - UVP_WARN2" 5 "Diag Cell - UVP_WARN1" 4 "Diag Cell - OVP_FAILURE" 3 "Diag Cell - OVP_FAULT" 2 "Diag Cell - OVP_WARN2" 1 "Diag Cell - OVP_WARN1" 0 "NORMAL" ;
VAL_ 800 bms1_stsFullyCharged 0 "N/A" 1 "CHARGING" 2 "FULLY CHARGED" ;
VAL_ 800 bms1_stsIgnitionRecog 0 "DISABLE" 1 "ENABLE" ;
VAL_ 800 bms1_stsPrechargeFET 0 "OFF" 1 "ON" 2 "RSVD1" 3 "RSVD2" ;
VAL_ 800 bms1_stsPwrCFET 0 "OFF" 1 "ON" 2 "RSVD1" 3 "RSVD2" ;
VAL_ 800 bms1_stsPwrDFET 0 "OFF" 1 "ON" 2 "RSVD1" 3 "RSVD2" ;
VAL_ 800 bms1_DiagMsg_Charger_Control 3 "Message Timeout Error" 2 "CheckSum Error" 0 "Normal" 1 "Alive Count Error" ;
VAL_ 800 bms1_DiagMsg_Charger_Diag 3 "Message Timeout Error" 2 "CheckSum Error" 0 "Normal" 1 "Alive Count Error" ;
VAL_ 800 bms1_DiagMsg_Charger_Status 3 "Message Timeout Error" 2 "CheckSum Error" 0 "Normal" 1 "Alive Count Error" ;
VAL_ 800 bms1_DiagMsg_VCU_Control 3 "Message Timeout Error" 2 "CheckSum Error" 0 "Normal" 1 "Alive Count Error" ;
VAL_ 800 bms1_DiagMsg_VCU_ODO 3 "Message Timeout Error" 2 "CheckSum Error" 0 "Normal" 1 "Alive Count Error" ;
VAL_ 800 bms1_DiagMsg_VCU_Status 3 "Message Timeout Error" 2 "CheckSum Error" 0 "Normal" 1 "Alive Count Error" ;
VAL_ 779 vfVCU_Faultinjection_ASIC_XREADY 3 "Fault" 0 "Normal" ;
VAL_ 779 vfVCU_Faultinjection_ASIC_SCP 3 "Fault" 0 "Normal" ;
VAL_ 779 vfVCU_Faultinjection_ASIC_OVRD 3 "Fault" 0 "Normal" ;
VAL_ 779 vfVCU_Faultinjection_ASIC_ODCP 3 "Fault" 0 "Normal" ;
VAL_ 776 vfVCU_Faultinjection_UDTP 3 "Set Fault" 2 "Set warning2" 0 "Normal" 1 "Set warning1" ;
VAL_ 776 vfVCU_Faultinjection_UCTP 3 "Set Fault" 2 "Set warning2" 0 "Normal" 1 "Set warning1" ;
VAL_ 776 vfVCU_Faultinjection_TIM 0 "Normal" 1 "Set warning1" ;
VAL_ 776 vfVCU_Faultinjection_SOC_IM 3 "Set Fault" 0 "Normal" 1 "Set warning1" ;
VAL_ 776 vfVCU_Faultinjection_Rest_CIM 0 "Normal" 1 "Set warning1" ;
VAL_ 776 vfVCU_Faultinjection_OCCP 3 "Set Fault" 2 "Set warning2" 0 "Normal" 1 "Set warning1" ;
VAL_ 776 vfVCU_Faultinjection_CHG_CIM 0 "Normal" 1 "Set warning1" ;
VAL_ 776 vfVCU_Faultinjection_ODCP 3 "Set Fault" 2 "Set warning2" 0 "Normal" 1 "Set warning1" ;
VAL_ 776 vfVCU_Faultinjection_OCTP 3 "Set Fault" 2 "Set warning2" 0 "Normal" 1 "Set warning1" ;
VAL_ 776 vfVCU_Faultinjection_UVP 3 "Set Fault" 2 "Set warning2" 0 "Normal" 1 "Set warning1" ;
VAL_ 776 vfVCU_Faultinjection_ODTP 3 "Set Fault" 2 "Set warning2" 0 "Normal" 1 "Set warning1" ;
VAL_ 776 vfVCU_Faultinjection_OVP 3 "Set Fault" 2 "Set warning2" 0 "Normal" 1 "Set warning1" ;
VAL_ 777 vfVCU_Faultinjection_FuseOC 2 "Warning2" 0 "Normal" 1 "Warning1" ;
VAL_ 777 vfVCU_Faultinjection_Fuseblow 3 "Fault" 0 "Normal" ;
VAL_ 777 vfVCU_Faultinjection_CDFET_OT 3 "Fault" 2 "Warning2" 0 "Normal" 1 "Warning1" ;
VAL_ 778 vfVCU_Faultinjection_PreFetOT 3 "Fault" 0 "Normal" ;
VAL_ 778 vfVCU_Faultinjection_SHORT_IC 3 "Fault" 0 "Normal" ;
VAL_ 778 vfVCU_Faultinjection_PreChgTO 3 "Fault" 0 "Normal" ;
VAL_ 778 vfVCU_Faultinjection_DFetFault 3 "Fault" 0 "Normal" ;
VAL_ 778 vfVCU_Faultinjection_CFetFault 3 "Fault" 0 "Normal" ;
VAL_ 778 vfVCU_Faultinjection_ASIC_ShutD 3 "Fault" 0 "Normal" ;
VAL_ 778 vfVCU_Faultinjection_ASIC_LC 3 "Fault" 0 "Normal" ;
VAL_ 815 bms1_stsDiagFaultEntry8 136 "Diag Cell - Low SOHe_FAILURE" 135 "Diag Cell - Low SOHe_FAULT" 134 "Diag Cell - Low SOHe_WARN2" 133 "Diag Cell - Low SOHe_WARN1" 132 "Diag ASIC - OVERRIDE_FAILURE" 131 "Diag ASIC - OVERRIDE_FAULT" 130 "Diag ASIC - OVERRIDE_WARN2" 129 "Diag ASIC - OVERRIDE_WARN1" 128 "Diag ASIC - XREADY_FAILURE" 127 "Diag ASIC - XREADY_FAULT" 126 "Diag ASIC - XREADY_WARN2" 125 "Diag ASIC - XREADY_WARN1" 124 "SNA" 123 "SNA" 122 "SNA" 121 "SNA" 120 "Diag ASIC - SCD_FAILURE" 119 "Diag ASIC - SCD_FAULT" 118 "Diag ASIC - SCD_WARN2" 117 "Diag ASIC - SCD_WARN1" 116 "SNA" 115 "SNA" 114 "SNA" 113 "SNA" 112 "Diag ASIC - ODC_FAILURE" 111 "Diag ASIC - ODC_FAULT" 110 "Diag ASIC - ODC_WARN2" 109 "Diag ASIC - ODC_WARN1" 108 "Diag ASIC - UV_FAILURE" 107 "Diag ASIC - UV_FAULT" 106 "Diag ASIC - UV_WARN2" 105 "Diag ASIC - UV_WARN1" 104 "Diag ASIC - OV_FAILURE" 103 "Diag ASIC - OV_FAULT" 102 "Diag ASIC - OV_WARN2" 101 "Diag ASIC - OV_WARN1" 100 "Diag Pack - FETsOT_FAILURE" 99 "Diag Pack - FETsOT_FAULT" 98 "Diag Pack - FETsOT_WARN2" 97 "Diag Pack - FETsOT_WARN1" 96 "Diag Pack - FUSEOC_FAILURE" 95 "Diag Pack - FUSEOC_FAULT" 94 "Diag Pack - FUSEOC_WARN2" 93 "Diag Pack - FUSEOC_WARN1" 92 "Diag Pack - FUSEBLOW_FAILURE" 91 "Diag Pack - FUSEBLOW_FAULT" 90 "Diag Pack - FUSEBLOW_WARN2" 89 "Diag Pack - FUSEBLOW_WARN1" 88 "Diag Pack - FUSEROHM_FAILURE" 87 "Diag Pack - FUSEROHM_FAULT" 86 "Diag Pack - FUSEROHM_WARN2" 85 "Diag Pack - FUSEROHM_WARN1" 84 "Diag BMS- ASIC_LOC_FAILURE" 83 "Diag BMS- ASIC_LOC_FAULT" 82 "Diag BMS- ASIC_LOC_WARN2" 81 "Diag BMS- ASIC_LOC_WARN1" 80 "Diag BMS- ASIC_SHUTDOWN_FAILURE" 79 "Diag BMS- ASIC_SHUTDOWN_FAULT" 78 "Diag BMS- ASIC_SHUTDOWN_WARN2" 77 "Diag BMS- ASIC_SHUTDOWN_WARN1" 76 "Diag BMS- PFET_TIMEOUT_FAILURE" 75 "Diag BMS- PFET_TIMEOUT_FAULT" 74 "Diag BMS- PFET_TIMEOUT_WARN2" 73 "Diag BMS- PFET_TIMEOUT_WARN1" 72 "Diag BMS- PFET_OT_FAILURE" 71 "Diag BMS- PFET_OT_FAULT" 70 "Diag BMS- PFET_OT_WARN2" 69 "Diag BMS- PFET_OT_WARN1" 68 "Diag BMS- CFET_FAILURE" 67 "Diag BMS- CFET_FAULT" 66 "Diag BMS- CFET_WARN2" 65 "Diag BMS- CFET_WARN1" 64 "Diag BMS- DFET_FAILURE" 63 "Diag BMS- DFET_FAULT" 62 "Diag BMS- DFET_WARN2" 61 "Diag BMS- DFET_WARN1" 60 "Diag BMS- SHORT IC" 59 "Diag BMS- OVIC_FAULT" 58 "Diag BMS- OVIC_WARN2" 57 "Diag BMS- OVIC_WARN1" 56 "Diag Cell - SOC-IM_FAILURE" 55 "Diag Cell - SOC-IM_FAULT" 54 "Diag Cell - SOC-IM_WARN2" 53 "Diag Cell - SOC-IM_WARN1" 52 "Diag Cell - TIM_FAILURE" 51 "Diag Cell - TIM_FAULT" 50 "Diag Cell - TIM_WARN2" 49 "Diag Cell - TIM_WARN1" 48 "Diag Cell - CIM-REST_FAILURE" 47 "Diag Cell - CIM-REST_FAULT" 46 "Diag Cell - CIM-REST_WARN2" 45 "Diag Cell - CIM-REST_WARN1" 44 "Diag Cell - CIM-CHG_FAILURE" 43 "Diag Cell - CIM-CHG_FAULT" 42 "Diag Cell - CIM-CHG_WARN2" 41 "Diag Cell - CIM-CHG_WARN1" 40 "Diag Cell - UDTP_FAILURE" 39 "Diag Cell - UDTP_FAULT" 38 "Diag Cell - UDTP_WARN2" 37 "Diag Cell - UDTP_WARN1" 36 "Diag Cell - UCTP_FAILURE" 35 "Diag Cell - UCTP_FAULT" 34 "Diag Cell - UCTP_WARN2" 33 "Diag Cell - UCTP_WARN1" 32 "Diag Cell - ODTP_FAILURE" 31 "Diag Cell - ODTP_FAULT" 30 "Diag Cell - ODTP_WARN2" 29 "Diag Cell - ODTP_WARN1" 28 "Diag Cell - OCTP_FAILURE" 27 "Diag Cell - OCTP_FAULT" 26 "Diag Cell - OCTP_WARN2" 25 "Diag Cell - OCTP_WARN1" 24 "Diag Cell - ODCP_FAILURE" 23 "Diag Cell - ODCP_FAULT" 22 "Diag Cell - ODCP_WARN2" 21 "Diag Cell - ODCP_WARN1" 20 "Diag Cell - OCCP_FAILURE" 19 "Diag Cell - OCCP_FAULT" 18 "Diag Cell - OCCP_WARN2" 17 "Diag Cell - OCCP_WARN1" 16 "Diag Cell - UVP_PACK_FAILURE" 15 "Diag Cell - UVP_PACK_FAULT" 14 "Diag Cell - UVP_PACK_WARN2" 13 "Diag Cell - UVP_PACK_WARN1" 12 "Diag Cell - OVP_PACK_FAILURE" 11 "Diag Cell - OVP_PACK_FAULT" 10 "Diag Cell - OVP_PACK_WARN2" 9 "Diag Cell - OVP_PACK_WARN1" 8 "Diag Cell - UVP_FAILURE" 7 "Diag Cell - UVP_FAULT" 6 "Diag Cell - UVP_WARN2" 5 "Diag Cell - UVP_WARN1" 4 "Diag Cell - OVP_FAILURE" 3 "Diag Cell - OVP_FAULT" 2 "Diag Cell - OVP_WARN2" 1 "Diag Cell - OVP_WARN1" 0 "NORMAL" ;
VAL_ 815 bms1_stsDiagFaultEntry7 136 "Diag Cell - Low SOHe_FAILURE" 135 "Diag Cell - Low SOHe_FAULT" 134 "Diag Cell - Low SOHe_WARN2" 133 "Diag Cell - Low SOHe_WARN1" 132 "Diag ASIC - OVERRIDE_FAILURE" 131 "Diag ASIC - OVERRIDE_FAULT" 130 "Diag ASIC - OVERRIDE_WARN2" 129 "Diag ASIC - OVERRIDE_WARN1" 128 "Diag ASIC - XREADY_FAILURE" 127 "Diag ASIC - XREADY_FAULT" 126 "Diag ASIC - XREADY_WARN2" 125 "Diag ASIC - XREADY_WARN1" 124 "SNA" 123 "SNA" 122 "SNA" 121 "SNA" 120 "Diag ASIC - SCD_FAILURE" 119 "Diag ASIC - SCD_FAULT" 118 "Diag ASIC - SCD_WARN2" 117 "Diag ASIC - SCD_WARN1" 116 "SNA" 115 "SNA" 114 "SNA" 113 "SNA" 112 "Diag ASIC - ODC_FAILURE" 111 "Diag ASIC - ODC_FAULT" 110 "Diag ASIC - ODC_WARN2" 109 "Diag ASIC - ODC_WARN1" 108 "Diag ASIC - UV_FAILURE" 107 "Diag ASIC - UV_FAULT" 106 "Diag ASIC - UV_WARN2" 105 "Diag ASIC - UV_WARN1" 104 "Diag ASIC - OV_FAILURE" 103 "Diag ASIC - OV_FAULT" 102 "Diag ASIC - OV_WARN2" 101 "Diag ASIC - OV_WARN1" 100 "Diag Pack - FETsOT_FAILURE" 99 "Diag Pack - FETsOT_FAULT" 98 "Diag Pack - FETsOT_WARN2" 97 "Diag Pack - FETsOT_WARN1" 96 "Diag Pack - FUSEOC_FAILURE" 95 "Diag Pack - FUSEOC_FAULT" 94 "Diag Pack - FUSEOC_WARN2" 93 "Diag Pack - FUSEOC_WARN1" 92 "Diag Pack - FUSEBLOW_FAILURE" 91 "Diag Pack - FUSEBLOW_FAULT" 90 "Diag Pack - FUSEBLOW_WARN2" 89 "Diag Pack - FUSEBLOW_WARN1" 88 "Diag Pack - FUSEROHM_FAILURE" 87 "Diag Pack - FUSEROHM_FAULT" 86 "Diag Pack - FUSEROHM_WARN2" 85 "Diag Pack - FUSEROHM_WARN1" 84 "Diag BMS- ASIC_LOC_FAILURE" 83 "Diag BMS- ASIC_LOC_FAULT" 82 "Diag BMS- ASIC_LOC_WARN2" 81 "Diag BMS- ASIC_LOC_WARN1" 80 "Diag BMS- ASIC_SHUTDOWN_FAILURE" 79 "Diag BMS- ASIC_SHUTDOWN_FAULT" 78 "Diag BMS- ASIC_SHUTDOWN_WARN2" 77 "Diag BMS- ASIC_SHUTDOWN_WARN1" 76 "Diag BMS- PFET_TIMEOUT_FAILURE" 75 "Diag BMS- PFET_TIMEOUT_FAULT" 74 "Diag BMS- PFET_TIMEOUT_WARN2" 73 "Diag BMS- PFET_TIMEOUT_WARN1" 72 "Diag BMS- PFET_OT_FAILURE" 71 "Diag BMS- PFET_OT_FAULT" 70 "Diag BMS- PFET_OT_WARN2" 69 "Diag BMS- PFET_OT_WARN1" 68 "Diag BMS- CFET_FAILURE" 67 "Diag BMS- CFET_FAULT" 66 "Diag BMS- CFET_WARN2" 65 "Diag BMS- CFET_WARN1" 64 "Diag BMS- DFET_FAILURE" 63 "Diag BMS- DFET_FAULT" 62 "Diag BMS- DFET_WARN2" 61 "Diag BMS- DFET_WARN1" 60 "Diag BMS- SHORT IC" 59 "Diag BMS- OVIC_FAULT" 58 "Diag BMS- OVIC_WARN2" 57 "Diag BMS- OVIC_WARN1" 56 "Diag Cell - SOC-IM_FAILURE" 55 "Diag Cell - SOC-IM_FAULT" 54 "Diag Cell - SOC-IM_WARN2" 53 "Diag Cell - SOC-IM_WARN1" 52 "Diag Cell - TIM_FAILURE" 51 "Diag Cell - TIM_FAULT" 50 "Diag Cell - TIM_WARN2" 49 "Diag Cell - TIM_WARN1" 48 "Diag Cell - CIM-REST_FAILURE" 47 "Diag Cell - CIM-REST_FAULT" 46 "Diag Cell - CIM-REST_WARN2" 45 "Diag Cell - CIM-REST_WARN1" 44 "Diag Cell - CIM-CHG_FAILURE" 43 "Diag Cell - CIM-CHG_FAULT" 42 "Diag Cell - CIM-CHG_WARN2" 41 "Diag Cell - CIM-CHG_WARN1" 40 "Diag Cell - UDTP_FAILURE" 39 "Diag Cell - UDTP_FAULT" 38 "Diag Cell - UDTP_WARN2" 37 "Diag Cell - UDTP_WARN1" 36 "Diag Cell - UCTP_FAILURE" 35 "Diag Cell - UCTP_FAULT" 34 "Diag Cell - UCTP_WARN2" 33 "Diag Cell - UCTP_WARN1" 32 "Diag Cell - ODTP_FAILURE" 31 "Diag Cell - ODTP_FAULT" 30 "Diag Cell - ODTP_WARN2" 29 "Diag Cell - ODTP_WARN1" 28 "Diag Cell - OCTP_FAILURE" 27 "Diag Cell - OCTP_FAULT" 26 "Diag Cell - OCTP_WARN2" 25 "Diag Cell - OCTP_WARN1" 24 "Diag Cell - ODCP_FAILURE" 23 "Diag Cell - ODCP_FAULT" 22 "Diag Cell - ODCP_WARN2" 21 "Diag Cell - ODCP_WARN1" 20 "Diag Cell - OCCP_FAILURE" 19 "Diag Cell - OCCP_FAULT" 18 "Diag Cell - OCCP_WARN2" 17 "Diag Cell - OCCP_WARN1" 16 "Diag Cell - UVP_PACK_FAILURE" 15 "Diag Cell - UVP_PACK_FAULT" 14 "Diag Cell - UVP_PACK_WARN2" 13 "Diag Cell - UVP_PACK_WARN1" 12 "Diag Cell - OVP_PACK_FAILURE" 11 "Diag Cell - OVP_PACK_FAULT" 10 "Diag Cell - OVP_PACK_WARN2" 9 "Diag Cell - OVP_PACK_WARN1" 8 "Diag Cell - UVP_FAILURE" 7 "Diag Cell - UVP_FAULT" 6 "Diag Cell - UVP_WARN2" 5 "Diag Cell - UVP_WARN1" 4 "Diag Cell - OVP_FAILURE" 3 "Diag Cell - OVP_FAULT" 2 "Diag Cell - OVP_WARN2" 1 "Diag Cell - OVP_WARN1" 0 "NORMAL" ;
VAL_ 814 bms1_stsDiagFaultEntry6 136 "Diag Cell - Low SOHe_FAILURE" 135 "Diag Cell - Low SOHe_FAULT" 134 "Diag Cell - Low SOHe_WARN2" 133 "Diag Cell - Low SOHe_WARN1" 132 "Diag ASIC - OVERRIDE_FAILURE" 131 "Diag ASIC - OVERRIDE_FAULT" 130 "Diag ASIC - OVERRIDE_WARN2" 129 "Diag ASIC - OVERRIDE_WARN1" 128 "Diag ASIC - XREADY_FAILURE" 127 "Diag ASIC - XREADY_FAULT" 126 "Diag ASIC - XREADY_WARN2" 125 "Diag ASIC - XREADY_WARN1" 124 "SNA" 123 "SNA" 122 "SNA" 121 "SNA" 120 "Diag ASIC - SCD_FAILURE" 119 "Diag ASIC - SCD_FAULT" 118 "Diag ASIC - SCD_WARN2" 117 "Diag ASIC - SCD_WARN1" 116 "SNA" 115 "SNA" 114 "SNA" 113 "SNA" 112 "Diag ASIC - ODC_FAILURE" 111 "Diag ASIC - ODC_FAULT" 110 "Diag ASIC - ODC_WARN2" 109 "Diag ASIC - ODC_WARN1" 108 "Diag ASIC - UV_FAILURE" 107 "Diag ASIC - UV_FAULT" 106 "Diag ASIC - UV_WARN2" 105 "Diag ASIC - UV_WARN1" 104 "Diag ASIC - OV_FAILURE" 103 "Diag ASIC - OV_FAULT" 102 "Diag ASIC - OV_WARN2" 101 "Diag ASIC - OV_WARN1" 100 "Diag Pack - FETsOT_FAILURE" 99 "Diag Pack - FETsOT_FAULT" 98 "Diag Pack - FETsOT_WARN2" 97 "Diag Pack - FETsOT_WARN1" 96 "Diag Pack - FUSEOC_FAILURE" 95 "Diag Pack - FUSEOC_FAULT" 94 "Diag Pack - FUSEOC_WARN2" 93 "Diag Pack - FUSEOC_WARN1" 92 "Diag Pack - FUSEBLOW_FAILURE" 91 "Diag Pack - FUSEBLOW_FAULT" 90 "Diag Pack - FUSEBLOW_WARN2" 89 "Diag Pack - FUSEBLOW_WARN1" 88 "Diag Pack - FUSEROHM_FAILURE" 87 "Diag Pack - FUSEROHM_FAULT" 86 "Diag Pack - FUSEROHM_WARN2" 85 "Diag Pack - FUSEROHM_WARN1" 84 "Diag BMS- ASIC_LOC_FAILURE" 83 "Diag BMS- ASIC_LOC_FAULT" 82 "Diag BMS- ASIC_LOC_WARN2" 81 "Diag BMS- ASIC_LOC_WARN1" 80 "Diag BMS- ASIC_SHUTDOWN_FAILURE" 79 "Diag BMS- ASIC_SHUTDOWN_FAULT" 78 "Diag BMS- ASIC_SHUTDOWN_WARN2" 77 "Diag BMS- ASIC_SHUTDOWN_WARN1" 76 "Diag BMS- PFET_TIMEOUT_FAILURE" 75 "Diag BMS- PFET_TIMEOUT_FAULT" 74 "Diag BMS- PFET_TIMEOUT_WARN2" 73 "Diag BMS- PFET_TIMEOUT_WARN1" 72 "Diag BMS- PFET_OT_FAILURE" 71 "Diag BMS- PFET_OT_FAULT" 70 "Diag BMS- PFET_OT_WARN2" 69 "Diag BMS- PFET_OT_WARN1" 68 "Diag BMS- CFET_FAILURE" 67 "Diag BMS- CFET_FAULT" 66 "Diag BMS- CFET_WARN2" 65 "Diag BMS- CFET_WARN1" 64 "Diag BMS- DFET_FAILURE" 63 "Diag BMS- DFET_FAULT" 62 "Diag BMS- DFET_WARN2" 61 "Diag BMS- DFET_WARN1" 60 "Diag BMS- SHORT IC" 59 "Diag BMS- OVIC_FAULT" 58 "Diag BMS- OVIC_WARN2" 57 "Diag BMS- OVIC_WARN1" 56 "Diag Cell - SOC-IM_FAILURE" 55 "Diag Cell - SOC-IM_FAULT" 54 "Diag Cell - SOC-IM_WARN2" 53 "Diag Cell - SOC-IM_WARN1" 52 "Diag Cell - TIM_FAILURE" 51 "Diag Cell - TIM_FAULT" 50 "Diag Cell - TIM_WARN2" 49 "Diag Cell - TIM_WARN1" 48 "Diag Cell - CIM-REST_FAILURE" 47 "Diag Cell - CIM-REST_FAULT" 46 "Diag Cell - CIM-REST_WARN2" 45 "Diag Cell - CIM-REST_WARN1" 44 "Diag Cell - CIM-CHG_FAILURE" 43 "Diag Cell - CIM-CHG_FAULT" 42 "Diag Cell - CIM-CHG_WARN2" 41 "Diag Cell - CIM-CHG_WARN1" 40 "Diag Cell - UDTP_FAILURE" 39 "Diag Cell - UDTP_FAULT" 38 "Diag Cell - UDTP_WARN2" 37 "Diag Cell - UDTP_WARN1" 36 "Diag Cell - UCTP_FAILURE" 35 "Diag Cell - UCTP_FAULT" 34 "Diag Cell - UCTP_WARN2" 33 "Diag Cell - UCTP_WARN1" 32 "Diag Cell - ODTP_FAILURE" 31 "Diag Cell - ODTP_FAULT" 30 "Diag Cell - ODTP_WARN2" 29 "Diag Cell - ODTP_WARN1" 28 "Diag Cell - OCTP_FAILURE" 27 "Diag Cell - OCTP_FAULT" 26 "Diag Cell - OCTP_WARN2" 25 "Diag Cell - OCTP_WARN1" 24 "Diag Cell - ODCP_FAILURE" 23 "Diag Cell - ODCP_FAULT" 22 "Diag Cell - ODCP_WARN2" 21 "Diag Cell - ODCP_WARN1" 20 "Diag Cell - OCCP_FAILURE" 19 "Diag Cell - OCCP_FAULT" 18 "Diag Cell - OCCP_WARN2" 17 "Diag Cell - OCCP_WARN1" 16 "Diag Cell - UVP_PACK_FAILURE" 15 "Diag Cell - UVP_PACK_FAULT" 14 "Diag Cell - UVP_PACK_WARN2" 13 "Diag Cell - UVP_PACK_WARN1" 12 "Diag Cell - OVP_PACK_FAILURE" 11 "Diag Cell - OVP_PACK_FAULT" 10 "Diag Cell - OVP_PACK_WARN2" 9 "Diag Cell - OVP_PACK_WARN1" 8 "Diag Cell - UVP_FAILURE" 7 "Diag Cell - UVP_FAULT" 6 "Diag Cell - UVP_WARN2" 5 "Diag Cell - UVP_WARN1" 4 "Diag Cell - OVP_FAILURE" 3 "Diag Cell - OVP_FAULT" 2 "Diag Cell - OVP_WARN2" 1 "Diag Cell - OVP_WARN1" 0 "NORMAL" ;
VAL_ 814 bms1_stsDiagFaultEntry5 136 "Diag Cell - Low SOHe_FAILURE" 135 "Diag Cell - Low SOHe_FAULT" 134 "Diag Cell - Low SOHe_WARN2" 133 "Diag Cell - Low SOHe_WARN1" 132 "Diag ASIC - OVERRIDE_FAILURE" 131 "Diag ASIC - OVERRIDE_FAULT" 130 "Diag ASIC - OVERRIDE_WARN2" 129 "Diag ASIC - OVERRIDE_WARN1" 128 "Diag ASIC - XREADY_FAILURE" 127 "Diag ASIC - XREADY_FAULT" 126 "Diag ASIC - XREADY_WARN2" 125 "Diag ASIC - XREADY_WARN1" 124 "SNA" 123 "SNA" 122 "SNA" 121 "SNA" 120 "Diag ASIC - SCD_FAILURE" 119 "Diag ASIC - SCD_FAULT" 118 "Diag ASIC - SCD_WARN2" 117 "Diag ASIC - SCD_WARN1" 116 "SNA" 115 "SNA" 114 "SNA" 113 "SNA" 112 "Diag ASIC - ODC_FAILURE" 111 "Diag ASIC - ODC_FAULT" 110 "Diag ASIC - ODC_WARN2" 109 "Diag ASIC - ODC_WARN1" 108 "Diag ASIC - UV_FAILURE" 107 "Diag ASIC - UV_FAULT" 106 "Diag ASIC - UV_WARN2" 105 "Diag ASIC - UV_WARN1" 104 "Diag ASIC - OV_FAILURE" 103 "Diag ASIC - OV_FAULT" 102 "Diag ASIC - OV_WARN2" 101 "Diag ASIC - OV_WARN1" 100 "Diag Pack - FETsOT_FAILURE" 99 "Diag Pack - FETsOT_FAULT" 98 "Diag Pack - FETsOT_WARN2" 97 "Diag Pack - FETsOT_WARN1" 96 "Diag Pack - FUSEOC_FAILURE" 95 "Diag Pack - FUSEOC_FAULT" 94 "Diag Pack - FUSEOC_WARN2" 93 "Diag Pack - FUSEOC_WARN1" 92 "Diag Pack - FUSEBLOW_FAILURE" 91 "Diag Pack - FUSEBLOW_FAULT" 90 "Diag Pack - FUSEBLOW_WARN2" 89 "Diag Pack - FUSEBLOW_WARN1" 88 "Diag Pack - FUSEROHM_FAILURE" 87 "Diag Pack - FUSEROHM_FAULT" 86 "Diag Pack - FUSEROHM_WARN2" 85 "Diag Pack - FUSEROHM_WARN1" 84 "Diag BMS- ASIC_LOC_FAILURE" 83 "Diag BMS- ASIC_LOC_FAULT" 82 "Diag BMS- ASIC_LOC_WARN2" 81 "Diag BMS- ASIC_LOC_WARN1" 80 "Diag BMS- ASIC_SHUTDOWN_FAILURE" 79 "Diag BMS- ASIC_SHUTDOWN_FAULT" 78 "Diag BMS- ASIC_SHUTDOWN_WARN2" 77 "Diag BMS- ASIC_SHUTDOWN_WARN1" 76 "Diag BMS- PFET_TIMEOUT_FAILURE" 75 "Diag BMS- PFET_TIMEOUT_FAULT" 74 "Diag BMS- PFET_TIMEOUT_WARN2" 73 "Diag BMS- PFET_TIMEOUT_WARN1" 72 "Diag BMS- PFET_OT_FAILURE" 71 "Diag BMS- PFET_OT_FAULT" 70 "Diag BMS- PFET_OT_WARN2" 69 "Diag BMS- PFET_OT_WARN1" 68 "Diag BMS- CFET_FAILURE" 67 "Diag BMS- CFET_FAULT" 66 "Diag BMS- CFET_WARN2" 65 "Diag BMS- CFET_WARN1" 64 "Diag BMS- DFET_FAILURE" 63 "Diag BMS- DFET_FAULT" 62 "Diag BMS- DFET_WARN2" 61 "Diag BMS- DFET_WARN1" 60 "Diag BMS- SHORT IC" 59 "Diag BMS- OVIC_FAULT" 58 "Diag BMS- OVIC_WARN2" 57 "Diag BMS- OVIC_WARN1" 56 "Diag Cell - SOC-IM_FAILURE" 55 "Diag Cell - SOC-IM_FAULT" 54 "Diag Cell - SOC-IM_WARN2" 53 "Diag Cell - SOC-IM_WARN1" 52 "Diag Cell - TIM_FAILURE" 51 "Diag Cell - TIM_FAULT" 50 "Diag Cell - TIM_WARN2" 49 "Diag Cell - TIM_WARN1" 48 "Diag Cell - CIM-REST_FAILURE" 47 "Diag Cell - CIM-REST_FAULT" 46 "Diag Cell - CIM-REST_WARN2" 45 "Diag Cell - CIM-REST_WARN1" 44 "Diag Cell - CIM-CHG_FAILURE" 43 "Diag Cell - CIM-CHG_FAULT" 42 "Diag Cell - CIM-CHG_WARN2" 41 "Diag Cell - CIM-CHG_WARN1" 40 "Diag Cell - UDTP_FAILURE" 39 "Diag Cell - UDTP_FAULT" 38 "Diag Cell - UDTP_WARN2" 37 "Diag Cell - UDTP_WARN1" 36 "Diag Cell - UCTP_FAILURE" 35 "Diag Cell - UCTP_FAULT" 34 "Diag Cell - UCTP_WARN2" 33 "Diag Cell - UCTP_WARN1" 32 "Diag Cell - ODTP_FAILURE" 31 "Diag Cell - ODTP_FAULT" 30 "Diag Cell - ODTP_WARN2" 29 "Diag Cell - ODTP_WARN1" 28 "Diag Cell - OCTP_FAILURE" 27 "Diag Cell - OCTP_FAULT" 26 "Diag Cell - OCTP_WARN2" 25 "Diag Cell - OCTP_WARN1" 24 "Diag Cell - ODCP_FAILURE" 23 "Diag Cell - ODCP_FAULT" 22 "Diag Cell - ODCP_WARN2" 21 "Diag Cell - ODCP_WARN1" 20 "Diag Cell - OCCP_FAILURE" 19 "Diag Cell - OCCP_FAULT" 18 "Diag Cell - OCCP_WARN2" 17 "Diag Cell - OCCP_WARN1" 16 "Diag Cell - UVP_PACK_FAILURE" 15 "Diag Cell - UVP_PACK_FAULT" 14 "Diag Cell - UVP_PACK_WARN2" 13 "Diag Cell - UVP_PACK_WARN1" 12 "Diag Cell - OVP_PACK_FAILURE" 11 "Diag Cell - OVP_PACK_FAULT" 10 "Diag Cell - OVP_PACK_WARN2" 9 "Diag Cell - OVP_PACK_WARN1" 8 "Diag Cell - UVP_FAILURE" 7 "Diag Cell - UVP_FAULT" 6 "Diag Cell - UVP_WARN2" 5 "Diag Cell - UVP_WARN1" 4 "Diag Cell - OVP_FAILURE" 3 "Diag Cell - OVP_FAULT" 2 "Diag Cell - OVP_WARN2" 1 "Diag Cell - OVP_WARN1" 0 "NORMAL" ;
VAL_ 814 bms1_stsDiagFaultEntry4 136 "Diag Cell - Low SOHe_FAILURE" 135 "Diag Cell - Low SOHe_FAULT" 134 "Diag Cell - Low SOHe_WARN2" 133 "Diag Cell - Low SOHe_WARN1" 132 "Diag ASIC - OVERRIDE_FAILURE" 131 "Diag ASIC - OVERRIDE_FAULT" 130 "Diag ASIC - OVERRIDE_WARN2" 129 "Diag ASIC - OVERRIDE_WARN1" 128 "Diag ASIC - XREADY_FAILURE" 127 "Diag ASIC - XREADY_FAULT" 126 "Diag ASIC - XREADY_WARN2" 125 "Diag ASIC - XREADY_WARN1" 124 "SNA" 123 "SNA" 122 "SNA" 121 "SNA" 120 "Diag ASIC - SCD_FAILURE" 119 "Diag ASIC - SCD_FAULT" 118 "Diag ASIC - SCD_WARN2" 117 "Diag ASIC - SCD_WARN1" 116 "SNA" 115 "SNA" 114 "SNA" 113 "SNA" 112 "Diag ASIC - ODC_FAILURE" 111 "Diag ASIC - ODC_FAULT" 110 "Diag ASIC - ODC_WARN2" 109 "Diag ASIC - ODC_WARN1" 108 "Diag ASIC - UV_FAILURE" 107 "Diag ASIC - UV_FAULT" 106 "Diag ASIC - UV_WARN2" 105 "Diag ASIC - UV_WARN1" 104 "Diag ASIC - OV_FAILURE" 103 "Diag ASIC - OV_FAULT" 102 "Diag ASIC - OV_WARN2" 101 "Diag ASIC - OV_WARN1" 100 "Diag Pack - FETsOT_FAILURE" 99 "Diag Pack - FETsOT_FAULT" 98 "Diag Pack - FETsOT_WARN2" 97 "Diag Pack - FETsOT_WARN1" 96 "Diag Pack - FUSEOC_FAILURE" 95 "Diag Pack - FUSEOC_FAULT" 94 "Diag Pack - FUSEOC_WARN2" 93 "Diag Pack - FUSEOC_WARN1" 92 "Diag Pack - FUSEBLOW_FAILURE" 91 "Diag Pack - FUSEBLOW_FAULT" 90 "Diag Pack - FUSEBLOW_WARN2" 89 "Diag Pack - FUSEBLOW_WARN1" 88 "Diag Pack - FUSEROHM_FAILURE" 87 "Diag Pack - FUSEROHM_FAULT" 86 "Diag Pack - FUSEROHM_WARN2" 85 "Diag Pack - FUSEROHM_WARN1" 84 "Diag BMS- ASIC_LOC_FAILURE" 83 "Diag BMS- ASIC_LOC_FAULT" 82 "Diag BMS- ASIC_LOC_WARN2" 81 "Diag BMS- ASIC_LOC_WARN1" 80 "Diag BMS- ASIC_SHUTDOWN_FAILURE" 79 "Diag BMS- ASIC_SHUTDOWN_FAULT" 78 "Diag BMS- ASIC_SHUTDOWN_WARN2" 77 "Diag BMS- ASIC_SHUTDOWN_WARN1" 76 "Diag BMS- PFET_TIMEOUT_FAILURE" 75 "Diag BMS- PFET_TIMEOUT_FAULT" 74 "Diag BMS- PFET_TIMEOUT_WARN2" 73 "Diag BMS- PFET_TIMEOUT_WARN1" 72 "Diag BMS- PFET_OT_FAILURE" 71 "Diag BMS- PFET_OT_FAULT" 70 "Diag BMS- PFET_OT_WARN2" 69 "Diag BMS- PFET_OT_WARN1" 68 "Diag BMS- CFET_FAILURE" 67 "Diag BMS- CFET_FAULT" 66 "Diag BMS- CFET_WARN2" 65 "Diag BMS- CFET_WARN1" 64 "Diag BMS- DFET_FAILURE" 63 "Diag BMS- DFET_FAULT" 62 "Diag BMS- DFET_WARN2" 61 "Diag BMS- DFET_WARN1" 60 "Diag BMS- SHORT IC" 59 "Diag BMS- OVIC_FAULT" 58 "Diag BMS- OVIC_WARN2" 57 "Diag BMS- OVIC_WARN1" 56 "Diag Cell - SOC-IM_FAILURE" 55 "Diag Cell - SOC-IM_FAULT" 54 "Diag Cell - SOC-IM_WARN2" 53 "Diag Cell - SOC-IM_WARN1" 52 "Diag Cell - TIM_FAILURE" 51 "Diag Cell - TIM_FAULT" 50 "Diag Cell - TIM_WARN2" 49 "Diag Cell - TIM_WARN1" 48 "Diag Cell - CIM-REST_FAILURE" 47 "Diag Cell - CIM-REST_FAULT" 46 "Diag Cell - CIM-REST_WARN2" 45 "Diag Cell - CIM-REST_WARN1" 44 "Diag Cell - CIM-CHG_FAILURE" 43 "Diag Cell - CIM-CHG_FAULT" 42 "Diag Cell - CIM-CHG_WARN2" 41 "Diag Cell - CIM-CHG_WARN1" 40 "Diag Cell - UDTP_FAILURE" 39 "Diag Cell - UDTP_FAULT" 38 "Diag Cell - UDTP_WARN2" 37 "Diag Cell - UDTP_WARN1" 36 "Diag Cell - UCTP_FAILURE" 35 "Diag Cell - UCTP_FAULT" 34 "Diag Cell - UCTP_WARN2" 33 "Diag Cell - UCTP_WARN1" 32 "Diag Cell - ODTP_FAILURE" 31 "Diag Cell - ODTP_FAULT" 30 "Diag Cell - ODTP_WARN2" 29 "Diag Cell - ODTP_WARN1" 28 "Diag Cell - OCTP_FAILURE" 27 "Diag Cell - OCTP_FAULT" 26 "Diag Cell - OCTP_WARN2" 25 "Diag Cell - OCTP_WARN1" 24 "Diag Cell - ODCP_FAILURE" 23 "Diag Cell - ODCP_FAULT" 22 "Diag Cell - ODCP_WARN2" 21 "Diag Cell - ODCP_WARN1" 20 "Diag Cell - OCCP_FAILURE" 19 "Diag Cell - OCCP_FAULT" 18 "Diag Cell - OCCP_WARN2" 17 "Diag Cell - OCCP_WARN1" 16 "Diag Cell - UVP_PACK_FAILURE" 15 "Diag Cell - UVP_PACK_FAULT" 14 "Diag Cell - UVP_PACK_WARN2" 13 "Diag Cell - UVP_PACK_WARN1" 12 "Diag Cell - OVP_PACK_FAILURE" 11 "Diag Cell - OVP_PACK_FAULT" 10 "Diag Cell - OVP_PACK_WARN2" 9 "Diag Cell - OVP_PACK_WARN1" 8 "Diag Cell - UVP_FAILURE" 7 "Diag Cell - UVP_FAULT" 6 "Diag Cell - UVP_WARN2" 5 "Diag Cell - UVP_WARN1" 4 "Diag Cell - OVP_FAILURE" 3 "Diag Cell - OVP_FAULT" 2 "Diag Cell - OVP_WARN2" 1 "Diag Cell - OVP_WARN1" 0 "NORMAL" ;
VAL_ 814 bms1_stsDiagFaultEntry3 136 "Diag Cell - Low SOHe_FAILURE" 135 "Diag Cell - Low SOHe_FAULT" 134 "Diag Cell - Low SOHe_WARN2" 133 "Diag Cell - Low SOHe_WARN1" 132 "Diag ASIC - OVERRIDE_FAILURE" 131 "Diag ASIC - OVERRIDE_FAULT" 130 "Diag ASIC - OVERRIDE_WARN2" 129 "Diag ASIC - OVERRIDE_WARN1" 128 "Diag ASIC - XREADY_FAILURE" 127 "Diag ASIC - XREADY_FAULT" 126 "Diag ASIC - XREADY_WARN2" 125 "Diag ASIC - XREADY_WARN1" 124 "SNA" 123 "SNA" 122 "SNA" 121 "SNA" 120 "Diag ASIC - SCD_FAILURE" 119 "Diag ASIC - SCD_FAULT" 118 "Diag ASIC - SCD_WARN2" 117 "Diag ASIC - SCD_WARN1" 116 "SNA" 115 "SNA" 114 "SNA" 113 "SNA" 112 "Diag ASIC - ODC_FAILURE" 111 "Diag ASIC - ODC_FAULT" 110 "Diag ASIC - ODC_WARN2" 109 "Diag ASIC - ODC_WARN1" 108 "Diag ASIC - UV_FAILURE" 107 "Diag ASIC - UV_FAULT" 106 "Diag ASIC - UV_WARN2" 105 "Diag ASIC - UV_WARN1" 104 "Diag ASIC - OV_FAILURE" 103 "Diag ASIC - OV_FAULT" 102 "Diag ASIC - OV_WARN2" 101 "Diag ASIC - OV_WARN1" 100 "Diag Pack - FETsOT_FAILURE" 99 "Diag Pack - FETsOT_FAULT" 98 "Diag Pack - FETsOT_WARN2" 97 "Diag Pack - FETsOT_WARN1" 96 "Diag Pack - FUSEOC_FAILURE" 95 "Diag Pack - FUSEOC_FAULT" 94 "Diag Pack - FUSEOC_WARN2" 93 "Diag Pack - FUSEOC_WARN1" 92 "Diag Pack - FUSEBLOW_FAILURE" 91 "Diag Pack - FUSEBLOW_FAULT" 90 "Diag Pack - FUSEBLOW_WARN2" 89 "Diag Pack - FUSEBLOW_WARN1" 88 "Diag Pack - FUSEROHM_FAILURE" 87 "Diag Pack - FUSEROHM_FAULT" 86 "Diag Pack - FUSEROHM_WARN2" 85 "Diag Pack - FUSEROHM_WARN1" 84 "Diag BMS- ASIC_LOC_FAILURE" 83 "Diag BMS- ASIC_LOC_FAULT" 82 "Diag BMS- ASIC_LOC_WARN2" 81 "Diag BMS- ASIC_LOC_WARN1" 80 "Diag BMS- ASIC_SHUTDOWN_FAILURE" 79 "Diag BMS- ASIC_SHUTDOWN_FAULT" 78 "Diag BMS- ASIC_SHUTDOWN_WARN2" 77 "Diag BMS- ASIC_SHUTDOWN_WARN1" 76 "Diag BMS- PFET_TIMEOUT_FAILURE" 75 "Diag BMS- PFET_TIMEOUT_FAULT" 74 "Diag BMS- PFET_TIMEOUT_WARN2" 73 "Diag BMS- PFET_TIMEOUT_WARN1" 72 "Diag BMS- PFET_OT_FAILURE" 71 "Diag BMS- PFET_OT_FAULT" 70 "Diag BMS- PFET_OT_WARN2" 69 "Diag BMS- PFET_OT_WARN1" 68 "Diag BMS- CFET_FAILURE" 67 "Diag BMS- CFET_FAULT" 66 "Diag BMS- CFET_WARN2" 65 "Diag BMS- CFET_WARN1" 64 "Diag BMS- DFET_FAILURE" 63 "Diag BMS- DFET_FAULT" 62 "Diag BMS- DFET_WARN2" 61 "Diag BMS- DFET_WARN1" 60 "Diag BMS- SHORT IC" 59 "Diag BMS- OVIC_FAULT" 58 "Diag BMS- OVIC_WARN2" 57 "Diag BMS- OVIC_WARN1" 56 "Diag Cell - SOC-IM_FAILURE" 55 "Diag Cell - SOC-IM_FAULT" 54 "Diag Cell - SOC-IM_WARN2" 53 "Diag Cell - SOC-IM_WARN1" 52 "Diag Cell - TIM_FAILURE" 51 "Diag Cell - TIM_FAULT" 50 "Diag Cell - TIM_WARN2" 49 "Diag Cell - TIM_WARN1" 48 "Diag Cell - CIM-REST_FAILURE" 47 "Diag Cell - CIM-REST_FAULT" 46 "Diag Cell - CIM-REST_WARN2" 45 "Diag Cell - CIM-REST_WARN1" 44 "Diag Cell - CIM-CHG_FAILURE" 43 "Diag Cell - CIM-CHG_FAULT" 42 "Diag Cell - CIM-CHG_WARN2" 41 "Diag Cell - CIM-CHG_WARN1" 40 "Diag Cell - UDTP_FAILURE" 39 "Diag Cell - UDTP_FAULT" 38 "Diag Cell - UDTP_WARN2" 37 "Diag Cell - UDTP_WARN1" 36 "Diag Cell - UCTP_FAILURE" 35 "Diag Cell - UCTP_FAULT" 34 "Diag Cell - UCTP_WARN2" 33 "Diag Cell - UCTP_WARN1" 32 "Diag Cell - ODTP_FAILURE" 31 "Diag Cell - ODTP_FAULT" 30 "Diag Cell - ODTP_WARN2" 29 "Diag Cell - ODTP_WARN1" 28 "Diag Cell - OCTP_FAILURE" 27 "Diag Cell - OCTP_FAULT" 26 "Diag Cell - OCTP_WARN2" 25 "Diag Cell - OCTP_WARN1" 24 "Diag Cell - ODCP_FAILURE" 23 "Diag Cell - ODCP_FAULT" 22 "Diag Cell - ODCP_WARN2" 21 "Diag Cell - ODCP_WARN1" 20 "Diag Cell - OCCP_FAILURE" 19 "Diag Cell - OCCP_FAULT" 18 "Diag Cell - OCCP_WARN2" 17 "Diag Cell - OCCP_WARN1" 16 "Diag Cell - UVP_PACK_FAILURE" 15 "Diag Cell - UVP_PACK_FAULT" 14 "Diag Cell - UVP_PACK_WARN2" 13 "Diag Cell - UVP_PACK_WARN1" 12 "Diag Cell - OVP_PACK_FAILURE" 11 "Diag Cell - OVP_PACK_FAULT" 10 "Diag Cell - OVP_PACK_WARN2" 9 "Diag Cell - OVP_PACK_WARN1" 8 "Diag Cell - UVP_FAILURE" 7 "Diag Cell - UVP_FAULT" 6 "Diag Cell - UVP_WARN2" 5 "Diag Cell - UVP_WARN1" 4 "Diag Cell - OVP_FAILURE" 3 "Diag Cell - OVP_FAULT" 2 "Diag Cell - OVP_WARN2" 1 "Diag Cell - OVP_WARN1" 0 "NORMAL" ;
VAL_ 814 bms1_stsDiagFaultEntry2 136 "Diag Cell - Low SOHe_FAILURE" 135 "Diag Cell - Low SOHe_FAULT" 134 "Diag Cell - Low SOHe_WARN2" 133 "Diag Cell - Low SOHe_WARN1" 132 "Diag ASIC - OVERRIDE_FAILURE" 131 "Diag ASIC - OVERRIDE_FAULT" 130 "Diag ASIC - OVERRIDE_WARN2" 129 "Diag ASIC - OVERRIDE_WARN1" 128 "Diag ASIC - XREADY_FAILURE" 127 "Diag ASIC - XREADY_FAULT" 126 "Diag ASIC - XREADY_WARN2" 125 "Diag ASIC - XREADY_WARN1" 124 "SNA" 123 "SNA" 122 "SNA" 121 "SNA" 120 "Diag ASIC - SCD_FAILURE" 119 "Diag ASIC - SCD_FAULT" 118 "Diag ASIC - SCD_WARN2" 117 "Diag ASIC - SCD_WARN1" 116 "SNA" 115 "SNA" 114 "SNA" 113 "SNA" 112 "Diag ASIC - ODC_FAILURE" 111 "Diag ASIC - ODC_FAULT" 110 "Diag ASIC - ODC_WARN2" 109 "Diag ASIC - ODC_WARN1" 108 "Diag ASIC - UV_FAILURE" 107 "Diag ASIC - UV_FAULT" 106 "Diag ASIC - UV_WARN2" 105 "Diag ASIC - UV_WARN1" 104 "Diag ASIC - OV_FAILURE" 103 "Diag ASIC - OV_FAULT" 102 "Diag ASIC - OV_WARN2" 101 "Diag ASIC - OV_WARN1" 100 "Diag Pack - FETsOT_FAILURE" 99 "Diag Pack - FETsOT_FAULT" 98 "Diag Pack - FETsOT_WARN2" 97 "Diag Pack - FETsOT_WARN1" 96 "Diag Pack - FUSEOC_FAILURE" 95 "Diag Pack - FUSEOC_FAULT" 94 "Diag Pack - FUSEOC_WARN2" 93 "Diag Pack - FUSEOC_WARN1" 92 "Diag Pack - FUSEBLOW_FAILURE" 91 "Diag Pack - FUSEBLOW_FAULT" 90 "Diag Pack - FUSEBLOW_WARN2" 89 "Diag Pack - FUSEBLOW_WARN1" 88 "Diag Pack - FUSEROHM_FAILURE" 87 "Diag Pack - FUSEROHM_FAULT" 86 "Diag Pack - FUSEROHM_WARN2" 85 "Diag Pack - FUSEROHM_WARN1" 84 "Diag BMS- ASIC_LOC_FAILURE" 83 "Diag BMS- ASIC_LOC_FAULT" 82 "Diag BMS- ASIC_LOC_WARN2" 81 "Diag BMS- ASIC_LOC_WARN1" 80 "Diag BMS- ASIC_SHUTDOWN_FAILURE" 79 "Diag BMS- ASIC_SHUTDOWN_FAULT" 78 "Diag BMS- ASIC_SHUTDOWN_WARN2" 77 "Diag BMS- ASIC_SHUTDOWN_WARN1" 76 "Diag BMS- PFET_TIMEOUT_FAILURE" 75 "Diag BMS- PFET_TIMEOUT_FAULT" 74 "Diag BMS- PFET_TIMEOUT_WARN2" 73 "Diag BMS- PFET_TIMEOUT_WARN1" 72 "Diag BMS- PFET_OT_FAILURE" 71 "Diag BMS- PFET_OT_FAULT" 70 "Diag BMS- PFET_OT_WARN2" 69 "Diag BMS- PFET_OT_WARN1" 68 "Diag BMS- CFET_FAILURE" 67 "Diag BMS- CFET_FAULT" 66 "Diag BMS- CFET_WARN2" 65 "Diag BMS- CFET_WARN1" 64 "Diag BMS- DFET_FAILURE" 63 "Diag BMS- DFET_FAULT" 62 "Diag BMS- DFET_WARN2" 61 "Diag BMS- DFET_WARN1" 60 "Diag BMS- SHORT IC" 59 "Diag BMS- OVIC_FAULT" 58 "Diag BMS- OVIC_WARN2" 57 "Diag BMS- OVIC_WARN1" 56 "Diag Cell - SOC-IM_FAILURE" 55 "Diag Cell - SOC-IM_FAULT" 54 "Diag Cell - SOC-IM_WARN2" 53 "Diag Cell - SOC-IM_WARN1" 52 "Diag Cell - TIM_FAILURE" 51 "Diag Cell - TIM_FAULT" 50 "Diag Cell - TIM_WARN2" 49 "Diag Cell - TIM_WARN1" 48 "Diag Cell - CIM-REST_FAILURE" 47 "Diag Cell - CIM-REST_FAULT" 46 "Diag Cell - CIM-REST_WARN2" 45 "Diag Cell - CIM-REST_WARN1" 44 "Diag Cell - CIM-CHG_FAILURE" 43 "Diag Cell - CIM-CHG_FAULT" 42 "Diag Cell - CIM-CHG_WARN2" 41 "Diag Cell - CIM-CHG_WARN1" 40 "Diag Cell - UDTP_FAILURE" 39 "Diag Cell - UDTP_FAULT" 38 "Diag Cell - UDTP_WARN2" 37 "Diag Cell - UDTP_WARN1" 36 "Diag Cell - UCTP_FAILURE" 35 "Diag Cell - UCTP_FAULT" 34 "Diag Cell - UCTP_WARN2" 33 "Diag Cell - UCTP_WARN1" 32 "Diag Cell - ODTP_FAILURE" 31 "Diag Cell - ODTP_FAULT" 30 "Diag Cell - ODTP_WARN2" 29 "Diag Cell - ODTP_WARN1" 28 "Diag Cell - OCTP_FAILURE" 27 "Diag Cell - OCTP_FAULT" 26 "Diag Cell - OCTP_WARN2" 25 "Diag Cell - OCTP_WARN1" 24 "Diag Cell - ODCP_FAILURE" 23 "Diag Cell - ODCP_FAULT" 22 "Diag Cell - ODCP_WARN2" 21 "Diag Cell - ODCP_WARN1" 20 "Diag Cell - OCCP_FAILURE" 19 "Diag Cell - OCCP_FAULT" 18 "Diag Cell - OCCP_WARN2" 17 "Diag Cell - OCCP_WARN1" 16 "Diag Cell - UVP_PACK_FAILURE" 15 "Diag Cell - UVP_PACK_FAULT" 14 "Diag Cell - UVP_PACK_WARN2" 13 "Diag Cell - UVP_PACK_WARN1" 12 "Diag Cell - OVP_PACK_FAILURE" 11 "Diag Cell - OVP_PACK_FAULT" 10 "Diag Cell - OVP_PACK_WARN2" 9 "Diag Cell - OVP_PACK_WARN1" 8 "Diag Cell - UVP_FAILURE" 7 "Diag Cell - UVP_FAULT" 6 "Diag Cell - UVP_WARN2" 5 "Diag Cell - UVP_WARN1" 4 "Diag Cell - OVP_FAILURE" 3 "Diag Cell - OVP_FAULT" 2 "Diag Cell - OVP_WARN2" 1 "Diag Cell - OVP_WARN1" 0 "NORMAL" ;
VAL_ 814 bms1_stsDiagFaultEntry1 136 "Diag Cell - Low SOHe_FAILURE" 135 "Diag Cell - Low SOHe_FAULT" 134 "Diag Cell - Low SOHe_WARN2" 133 "Diag Cell - Low SOHe_WARN1" 132 "Diag ASIC - OVERRIDE_FAILURE" 131 "Diag ASIC - OVERRIDE_FAULT" 130 "Diag ASIC - OVERRIDE_WARN2" 129 "Diag ASIC - OVERRIDE_WARN1" 128 "Diag ASIC - XREADY_FAILURE" 127 "Diag ASIC - XREADY_FAULT" 126 "Diag ASIC - XREADY_WARN2" 125 "Diag ASIC - XREADY_WARN1" 124 "SNA" 123 "SNA" 122 "SNA" 121 "SNA" 120 "Diag ASIC - SCD_FAILURE" 119 "Diag ASIC - SCD_FAULT" 118 "Diag ASIC - SCD_WARN2" 117 "Diag ASIC - SCD_WARN1" 116 "SNA" 115 "SNA" 114 "SNA" 113 "SNA" 112 "Diag ASIC - ODC_FAILURE" 111 "Diag ASIC - ODC_FAULT" 110 "Diag ASIC - ODC_WARN2" 109 "Diag ASIC - ODC_WARN1" 108 "Diag ASIC - UV_FAILURE" 107 "Diag ASIC - UV_FAULT" 106 "Diag ASIC - UV_WARN2" 105 "Diag ASIC - UV_WARN1" 104 "Diag ASIC - OV_FAILURE" 103 "Diag ASIC - OV_FAULT" 102 "Diag ASIC - OV_WARN2" 101 "Diag ASIC - OV_WARN1" 100 "Diag Pack - FETsOT_FAILURE" 99 "Diag Pack - FETsOT_FAULT" 98 "Diag Pack - FETsOT_WARN2" 97 "Diag Pack - FETsOT_WARN1" 96 "Diag Pack - FUSEOC_FAILURE" 95 "Diag Pack - FUSEOC_FAULT" 94 "Diag Pack - FUSEOC_WARN2" 93 "Diag Pack - FUSEOC_WARN1" 92 "Diag Pack - FUSEBLOW_FAILURE" 91 "Diag Pack - FUSEBLOW_FAULT" 90 "Diag Pack - FUSEBLOW_WARN2" 89 "Diag Pack - FUSEBLOW_WARN1" 88 "Diag Pack - FUSEROHM_FAILURE" 87 "Diag Pack - FUSEROHM_FAULT" 86 "Diag Pack - FUSEROHM_WARN2" 85 "Diag Pack - FUSEROHM_WARN1" 84 "Diag BMS- ASIC_LOC_FAILURE" 83 "Diag BMS- ASIC_LOC_FAULT" 82 "Diag BMS- ASIC_LOC_WARN2" 81 "Diag BMS- ASIC_LOC_WARN1" 80 "Diag BMS- ASIC_SHUTDOWN_FAILURE" 79 "Diag BMS- ASIC_SHUTDOWN_FAULT" 78 "Diag BMS- ASIC_SHUTDOWN_WARN2" 77 "Diag BMS- ASIC_SHUTDOWN_WARN1" 76 "Diag BMS- PFET_TIMEOUT_FAILURE" 75 "Diag BMS- PFET_TIMEOUT_FAULT" 74 "Diag BMS- PFET_TIMEOUT_WARN2" 73 "Diag BMS- PFET_TIMEOUT_WARN1" 72 "Diag BMS- PFET_OT_FAILURE" 71 "Diag BMS- PFET_OT_FAULT" 70 "Diag BMS- PFET_OT_WARN2" 69 "Diag BMS- PFET_OT_WARN1" 68 "Diag BMS- CFET_FAILURE" 67 "Diag BMS- CFET_FAULT" 66 "Diag BMS- CFET_WARN2" 65 "Diag BMS- CFET_WARN1" 64 "Diag BMS- DFET_FAILURE" 63 "Diag BMS- DFET_FAULT" 62 "Diag BMS- DFET_WARN2" 61 "Diag BMS- DFET_WARN1" 60 "Diag BMS- SHORT IC" 59 "Diag BMS- OVIC_FAULT" 58 "Diag BMS- OVIC_WARN2" 57 "Diag BMS- OVIC_WARN1" 56 "Diag Cell - SOC-IM_FAILURE" 55 "Diag Cell - SOC-IM_FAULT" 54 "Diag Cell - SOC-IM_WARN2" 53 "Diag Cell - SOC-IM_WARN1" 52 "Diag Cell - TIM_FAILURE" 51 "Diag Cell - TIM_FAULT" 50 "Diag Cell - TIM_WARN2" 49 "Diag Cell - TIM_WARN1" 48 "Diag Cell - CIM-REST_FAILURE" 47 "Diag Cell - CIM-REST_FAULT" 46 "Diag Cell - CIM-REST_WARN2" 45 "Diag Cell - CIM-REST_WARN1" 44 "Diag Cell - CIM-CHG_FAILURE" 43 "Diag Cell - CIM-CHG_FAULT" 42 "Diag Cell - CIM-CHG_WARN2" 41 "Diag Cell - CIM-CHG_WARN1" 40 "Diag Cell - UDTP_FAILURE" 39 "Diag Cell - UDTP_FAULT" 38 "Diag Cell - UDTP_WARN2" 37 "Diag Cell - UDTP_WARN1" 36 "Diag Cell - UCTP_FAILURE" 35 "Diag Cell - UCTP_FAULT" 34 "Diag Cell - UCTP_WARN2" 33 "Diag Cell - UCTP_WARN1" 32 "Diag Cell - ODTP_FAILURE" 31 "Diag Cell - ODTP_FAULT" 30 "Diag Cell - ODTP_WARN2" 29 "Diag Cell - ODTP_WARN1" 28 "Diag Cell - OCTP_FAILURE" 27 "Diag Cell - OCTP_FAULT" 26 "Diag Cell - OCTP_WARN2" 25 "Diag Cell - OCTP_WARN1" 24 "Diag Cell - ODCP_FAILURE" 23 "Diag Cell - ODCP_FAULT" 22 "Diag Cell - ODCP_WARN2" 21 "Diag Cell - ODCP_WARN1" 20 "Diag Cell - OCCP_FAILURE" 19 "Diag Cell - OCCP_FAULT" 18 "Diag Cell - OCCP_WARN2" 17 "Diag Cell - OCCP_WARN1" 16 "Diag Cell - UVP_PACK_FAILURE" 15 "Diag Cell - UVP_PACK_FAULT" 14 "Diag Cell - UVP_PACK_WARN2" 13 "Diag Cell - UVP_PACK_WARN1" 12 "Diag Cell - OVP_PACK_FAILURE" 11 "Diag Cell - OVP_PACK_FAULT" 10 "Diag Cell - OVP_PACK_WARN2" 9 "Diag Cell - OVP_PACK_WARN1" 8 "Diag Cell - UVP_FAILURE" 7 "Diag Cell - UVP_FAULT" 6 "Diag Cell - UVP_WARN2" 5 "Diag Cell - UVP_WARN1" 4 "Diag Cell - OVP_FAILURE" 3 "Diag Cell - OVP_FAULT" 2 "Diag Cell - OVP_WARN2" 1 "Diag Cell - OVP_WARN1" 0 "NORMAL" ;
